VERSION ""

NS_ :

BS_:

BU_:IC_MMI GW AC AVM BCM DSM_D DSM_P FSCM PSR CWC

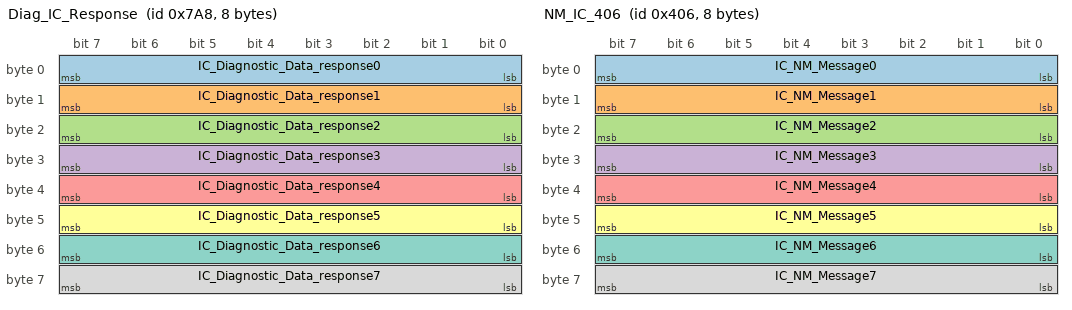
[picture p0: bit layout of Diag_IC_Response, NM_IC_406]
BO_ 1960 Diag_IC_Response: 8 IC_MMI
 SG_ IC_Diagnostic_Data_response0 : 7|8@0+ (1,0) [0|255] "" GW
 SG_ IC_Diagnostic_Data_response1 : 15|8@0+ (1,0) [0|255] "" GW
 SG_ IC_Diagnostic_Data_response2 : 23|8@0+ (1,0) [0|255] "" GW
 SG_ IC_Diagnostic_Data_response3 : 31|8@0+ (1,0) [0|255] "" GW
 SG_ IC_Diagnostic_Data_response4 : 39|8@0+ (1,0) [0|255] "" GW
 SG_ IC_Diagnostic_Data_response5 : 47|8@0+ (1,0) [0|255] "" GW
 SG_ IC_Diagnostic_Data_response6 : 55|8@0+ (1,0) [0|255] "" GW
 SG_ IC_Diagnostic_Data_response7 : 63|8@0+ (1,0) [0|255] "" GW

BO_ 1030 NM_IC_406: 8 IC_MMI
 SG_ IC_NM_Message0 : 7|8@0+ (1,0) [0|255] "" GW,AC,BCM
 SG_ IC_NM_Message1 : 15|8@0+ (1,0) [0|255] "" GW,AC,BCM
 SG_ IC_NM_Message2 : 23|8@0+ (1,0) [0|255] "" GW,AC,BCM
 SG_ IC_NM_Message3 : 31|8@0+ (1,0) [0|255] "" GW,AC,BCM
 SG_ IC_NM_Message4 : 39|8@0+ (1,0) [0|255] "" GW,AC,BCM
 SG_ IC_NM_Message5 : 47|8@0+ (1,0) [0|255] "" GW,AC,BCM
 SG_ IC_NM_Message6 : 55|8@0+ (1,0) [0|255] "" GW,AC,BCM
 SG_ IC_NM_Message7 : 63|8@0+ (1,0) [0|255] "" GW,AC,BCM

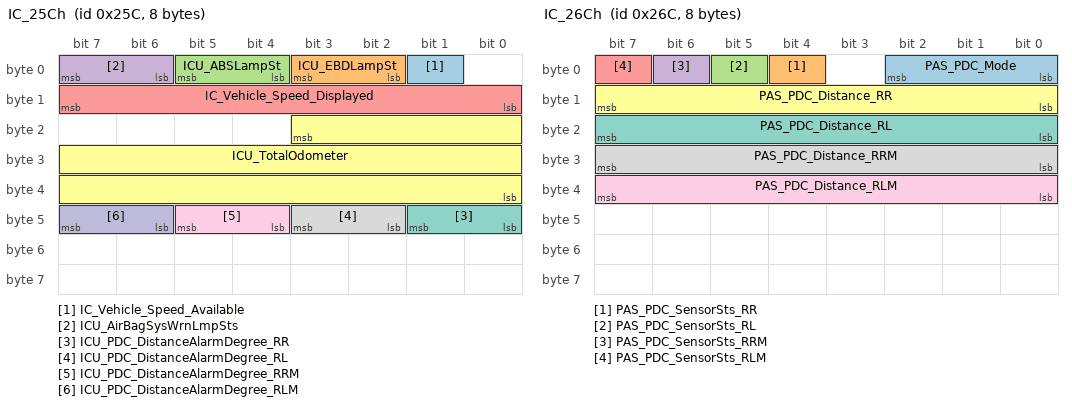
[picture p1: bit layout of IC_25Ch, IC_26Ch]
BO_ 604 IC_25Ch: 8 IC_MMI
 SG_ IC_Vehicle_Speed_Available : 1|1@0+ (1,0) [0|1] "" GW
 SG_ ICU_EBDLampSt : 3|2@0+ (1,0) [0|3] "" GW
 SG_ ICU_ABSLampSt : 5|2@0+ (1,0) [0|3] "" GW
 SG_ ICU_AirBagSysWrnLmpSts : 7|2@0+ (1,0) [0|3] "" GW
 SG_ IC_Vehicle_Speed_Displayed : 15|8@0+ (1,0) [0|255] "km/h" GW,AVM
 SG_ ICU_TotalOdometer : 19|20@0+ (1,0) [0|999999] "Km" GW,AVM,BCM
 SG_ ICU_PDC_DistanceAlarmDegree_RR : 41|2@0+ (1,0) [0|3] "" GW,AVM
 SG_ ICU_PDC_DistanceAlarmDegree_RL : 43|2@0+ (1,0) [0|3] "" GW,AVM
 SG_ ICU_PDC_DistanceAlarmDegree_RRM : 45|2@0+ (1,0) [0|3] "" GW,AVM
 SG_ ICU_PDC_DistanceAlarmDegree_RLM : 47|2@0+ (1,0) [0|3] "" GW,AVM

BO_ 620 IC_26Ch: 8 IC_MMI
 SG_ PAS_PDC_Mode : 2|3@0+ (1,0) [0|7] "" GW,AVM
 SG_ PAS_PDC_SensorSts_RR : 4|1@0+ (1,0) [0|1] "" GW,AVM
 SG_ PAS_PDC_SensorSts_RL : 5|1@0+ (1,0) [0|1] "" GW,AVM
 SG_ PAS_PDC_SensorSts_RRM : 6|1@0+ (1,0) [0|1] "" GW,AVM
 SG_ PAS_PDC_SensorSts_RLM : 7|1@0+ (1,0) [0|1] "" GW,AVM
 SG_ PAS_PDC_Distance_RR : 15|8@0+ (0.01,0) [0|1.5] "m" GW,AVM
 SG_ PAS_PDC_Distance_RL : 23|8@0+ (0.01,0) [0|1.5] "m" GW,AVM
 SG_ PAS_PDC_Distance_RRM : 31|8@0+ (0.01,0) [0|1.5] "m" GW,AVM
 SG_ PAS_PDC_Distance_RLM : 39|8@0+ (0.01,0) [0|1.5] "m" GW,AVM

BO_ 648 MMI_288h: 8 IC_MMI
 SG_ MMI_ACAUTOReqValid : 0|1@0+ (1,0) [0|1] "" GW,AC
 SG_ MMI_ACAUTOReq : 1|1@0+ (1,0) [0|1] "" GW,AC
 SG_ MMI_ACCompressorReqValid : 2|1@0+ (1,0) [0|1] "" GW,AC
 SG_ MMI_ACCompressorReq : 3|1@0+ (1,0) [0|1] "" GW,AC
 SG_ MMI_ACMaxReqValid : 4|1@0+ (1,0) [0|1] "" GW,AC
 SG_ MMI_ACMaxReq : 5|1@0+ (1,0) [0|1] "" GW,AC
 SG_ MMI_ACOFFReqValid : 6|1@0+ (1,0) [0|1] "" GW,AC
 SG_ MMI_ACOFFReq : 7|1@0+ (1,0) [0|1] "" GW,AC
 SG_ MMI_InsideTempIncDecReqValid : 8|1@0+ (1,0) [0|1] "" GW,AC
 SG_ MMI_InsideTempIncDecReq : 9|1@0+ (1,0) [0|1] "" GW,AC
 SG_ MMI_BLOWERReqValid : 10|1@0+ (1,0) [0|1] "" GW,AC
 SG_ MMI_BLOWERReq : 11|1@0+ (1,0) [0|1] "" GW,AC
 SG_ MMI_ACBlowModeReqValid : 12|1@0+ (1,0) [0|1] "" GW,AC
 SG_ MMI_ACBlowModeReq : 15|3@0+ (1,0) [0|7] "" GW,AC
 SG_ MMI_CirculatingModeSetValid : 16|1@0+ (1,0) [0|1] "" GW,AC
 SG_ MMI_CirculatingModeSet : 17|1@0+ (1,0) [0|1] "" GW,AC
 SG_ MMI_InsideTempSetValid : 18|1@0+ (1,0) [0|1] "" GW,AC
 SG_ MMI_InsideTempSet : 23|5@0+ (0.5,18) [18|32] "℃" GW,AC
 SG_ MMI_SeatHeatReq_right : 25|2@0+ (1,0) [0|3] "" GW,AC
 SG_ MMI_SeatHeatReq_left : 27|2@0+ (1,0) [0|3] "" GW,AC
 SG_ MMI_BLOWERGearSetValid : 28|1@0+ (1,0) [0|1] "" GW,AC
 SG_ MMI_BLOWERGearSet : 31|3@0+ (1,0) [0|7] "" GW,AC
 SG_ MMI_FrontDeforstReq : 33|2@0+ (1,0) [0|3] "" GW,AC
 SG_ MMI_RearDeforstReq : 35|2@0+ (1,0) [0|3] "" GW,AC
 SG_ MMI_RearViewMirrorHeatReq : 41|2@0+ (1,0) [0|3] "" GW,AC
 SG_ MMI_AnionNegativeIonReq : 43|2@0+ (1,0) [0|3] "" GW,AC

BO_ 370 MMI_172h: 8 IC_MMI
 SG_ MMI_LDW_Main_Switch : 0|1@0+ (1,0) [0|1] "" GW
 SG_ MMI_LDW_Switch_Available : 1|1@0+ (1,0) [0|1] "" GW
 SG_ MMI_FCW_Sensitivity : 3|2@0+ (1,0) [0|3] "" GW
 SG_ MMI_FCW_Main_Switch : 4|1@0+ (1,0) [0|1] "" GW
 SG_ MMI_FCW_Switch_Available : 5|1@0+ (1,0) [0|1] "" GW
 SG_ MMI_AEB_Main_Switch : 6|1@0+ (1,0) [0|1] "" GW
 SG_ MMI_AEB_Switch_Available : 7|1@0+ (1,0) [0|1] "" GW
 SG_ MMI_TSR_Main_Switch : 10|1@0+ (1,0) [0|1] "" GW
 SG_ MMI_TSR_Switch_Available : 11|1@0+ (1,0) [0|1] "" GW
 SG_ MMI_IHC_Main_Switch : 12|1@0+ (1,0) [0|1] "" GW
 SG_ MMI_IHC_Switch_Available : 13|1@0+ (1,0) [0|1] "" GW
 SG_ MMI_LDW_Sensitivity : 15|2@0+ (1,0) [0|3] "" GW
 SG_ MMI_BSD_Main_Switch : 16|1@0+ (1,0) [0|1] "" GW
 SG_ MMI_BSD_Switch_Available : 17|1@0+ (1,0) [0|1] "" GW
 SG_ MMI_BSD_Sensitivity : 19|2@0+ (1,0) [0|3] "" GW
 SG_ MMI_EPS_ModeSwitch : 22|3@0+ (1,0) [0|7] "" GW
 SG_ MMI_PauseContinueChrgRQ : 25|2@0+ (1,0) [0|3] "" GW
 SG_ MMI_WCBS_CstSwitch : 26|1@0+ (1,0) [0|1] "" GW
 SG_ MMI_WCBS_HDCSwitch : 27|1@0+ (1,0) [0|1] "" GW
 SG_ MMI_OperationMode : 30|3@0+ (1,0) [0|7] "" GW
 SG_ MMI_ChrgMaxPower : 38|7@0+ (1,0) [0|100] "%" GW
 SG_ MMI_ChrgCurrentSet : 47|8@0+ (0.1,0) [0|25.5] "A" GW
 SG_ MMI_EnergyRecoveryContr : 50|3@0+ (1,0) [0|7] "" GW
 SG_ MMI_LKA_Main_Switch : 52|1@0+ (1,0) [0|1] "" GW
 SG_ MMI_LKA_Switch_Available : 53|1@0+ (1,0) [0|1] "" GW

BO_ 630 MMI_276h: 8 IC_MMI
 SG_ MMI_AVM_ConnectStatus : 3|4@0+ (1,0) [0|15] "" GW,AVM
 SG_ MMI_AVM_LanguageSet : 7|4@0+ (1,0) [0|15] "" GW,AVM
 SG_ MMI_AVM_AVM3DDynTrajSet : 9|2@0+ (1,0) [0|3] "" GW,AVM
 SG_ MMI_AVM_AVM3DExitDelaySet : 11|2@0+ (1,0) [0|3] "" GW,AVM
 SG_ MMI_AVM_AVM3DTurnLightSet : 13|2@0+ (1,0) [0|3] "" GW,AVM
 SG_ MMI_AVM_AVM3DBlindFillSet : 15|2@0+ (1,0) [0|3] "" GW,AVM
 SG_ MMI_AVM_BSDFunction : 17|2@0+ (1,0) [0|3] "" GW,AVM
 SG_ MMI_AVM_OTFunction : 19|2@0+ (1,0) [0|3] "" GW,AVM
 SG_ MMI_AVM_AVM3DCarIconColor : 23|4@0+ (1,0) [0|15] "" GW,AVM
 SG_ MMI_AVM_AVM3DCarIconTransparenValid : 25|2@0+ (1,0) [0|3] "" GW,AVM
 SG_ MMI_AVM_VideoOutputStatus : 31|4@0+ (1,0) [0|15] "" GW,AVM
 SG_ MMI_AVM_AVM3DCarIconTransparent : 39|8@0+ (1,0) [0|100] "%" GW,AVM
 SG_ MMI_AmphereLampCtrl_Colour : 43|4@0+ (1,0) [0|15] "" GW
 SG_ MMI_AmphereLampCtrl_Fleshmode : 46|3@0+ (1,0) [0|7] "" GW
 SG_ MMI_AmphereLampCtrl_Drivingmode : 49|2@0+ (1,0) [0|3] "" GW
 SG_ MMI_AmphereLampCtrl_SW : 51|2@0+ (1,0) [0|3] "" GW
 SG_ MMI_AmphereLampCtrl_BrtnsVal : 63|8@0+ (1,0) [0|100] "" GW

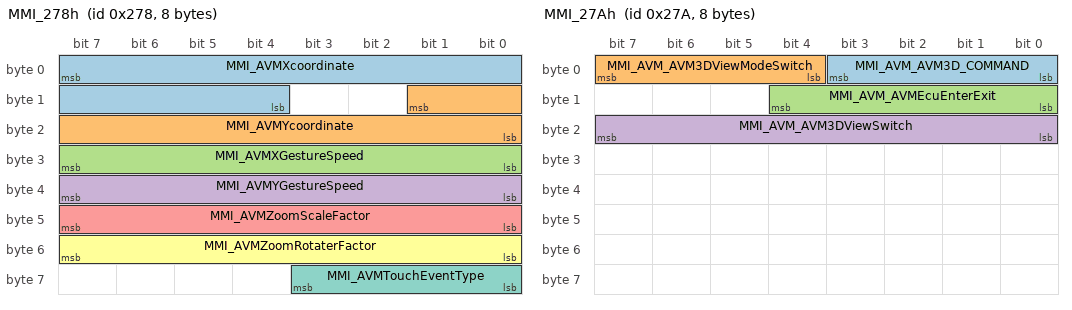
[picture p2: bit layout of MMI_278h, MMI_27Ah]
BO_ 632 MMI_278h: 8 IC_MMI
 SG_ MMI_AVMXcoordinate : 7|12@0+ (1,0) [0|4094] "" GW,AVM
 SG_ MMI_AVMYcoordinate : 9|10@0+ (1,0) [0|1022] "" GW,AVM
 SG_ MMI_AVMXGestureSpeed : 31|8@0+ (1,0) [0|254] "pixels/100ms" GW,AVM
 SG_ MMI_AVMYGestureSpeed : 39|8@0+ (1,0) [0|254] "pixels/100ms" GW,AVM
 SG_ MMI_AVMZoomScaleFactor : 47|8@0+ (1,0) [0|254] "" GW,AVM
 SG_ MMI_AVMZoomRotaterFactor : 55|8@0+ (1,0) [0|254] "" GW,AVM
 SG_ MMI_AVMTouchEventType : 59|4@0+ (1,0) [0|15] "" GW,AVM

BO_ 634 MMI_27Ah: 8 IC_MMI
 SG_ MMI_AVM_AVM3D_COMMAND : 3|4@0+ (1,0) [0|15] "" GW,AVM
 SG_ MMI_AVM_AVM3DViewModeSwitch : 7|4@0+ (1,0) [0|15] "" GW,AVM
 SG_ MMI_AVM_AVMEcuEnterExit : 12|5@0+ (1,0) [0|31] "" GW,AVM
 SG_ MMI_AVM_AVM3DViewSwitch : 23|8@0+ (1,0) [0|255] "" GW,AVM

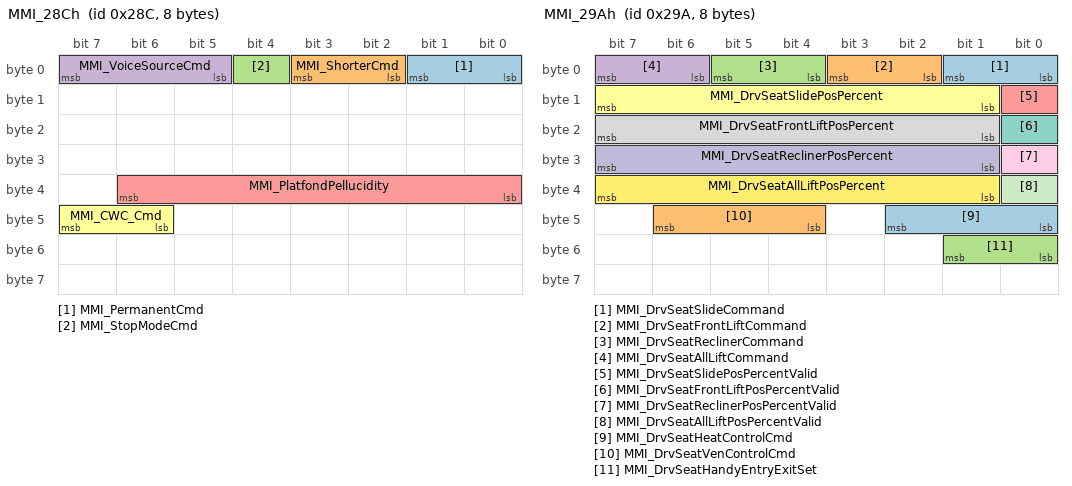
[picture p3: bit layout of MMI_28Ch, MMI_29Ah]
BO_ 652 MMI_28Ch: 8 IC_MMI
 SG_ MMI_PermanentCmd : 1|2@0+ (1,0) [0|3] "" GW
 SG_ MMI_ShorterCmd : 3|2@0+ (1,0) [0|3] "" GW
 SG_ MMI_StopModeCmd : 4|1@0+ (1,0) [0|1] "" GW
 SG_ MMI_VoiceSourceCmd : 7|3@0+ (1,0) [0|7] "" GW
 SG_ MMI_PlatfondPellucidity : 38|7@0+ (1,0) [0|100] "%" PSR
 SG_ MMI_CWC_Cmd : 47|2@0+ (1,0) [0|3] "" GW,CWC

BO_ 666 MMI_29Ah: 8 IC_MMI
 SG_ MMI_DrvSeatSlideCommand : 1|2@0+ (1,0) [0|3] "" DSM_D
 SG_ MMI_DrvSeatFrontLiftCommand : 3|2@0+ (1,0) [0|3] "" DSM_D
 SG_ MMI_DrvSeatReclinerCommand : 5|2@0+ (1,0) [0|3] "" DSM_D
 SG_ MMI_DrvSeatAllLiftCommand : 7|2@0+ (1,0) [0|3] "" DSM_D
 SG_ MMI_DrvSeatSlidePosPercentValid : 8|1@0+ (1,0) [0|1] "" DSM_D
 SG_ MMI_DrvSeatSlidePosPercent : 15|7@0+ (1,0) [0|100] "%" DSM_D
 SG_ MMI_DrvSeatFrontLiftPosPercentValid : 16|1@0+ (1,0) [0|1] "" DSM_D
 SG_ MMI_DrvSeatFrontLiftPosPercent : 23|7@0+ (1,0) [0|100] "%" DSM_D
 SG_ MMI_DrvSeatReclinerPosPercentValid : 24|1@0+ (1,0) [0|1] "" DSM_D
 SG_ MMI_DrvSeatReclinerPosPercent : 31|7@0+ (1,0) [0|100] "%" DSM_D
 SG_ MMI_DrvSeatAllLiftPosPercentValid : 32|1@0+ (1,0) [0|1] "" DSM_D
 SG_ MMI_DrvSeatAllLiftPosPercent : 39|7@0+ (1,0) [0|100] "%" DSM_D
 SG_ MMI_DrvSeatHeatControlCmd : 42|3@0+ (1,0) [0|7] "" FSCM
 SG_ MMI_DrvSeatVenControlCmd : 46|3@0+ (1,0) [0|7] "" FSCM
 SG_ MMI_DrvSeatHandyEntryExitSet : 49|2@0+ (1,0) [0|3] "" DSM_D

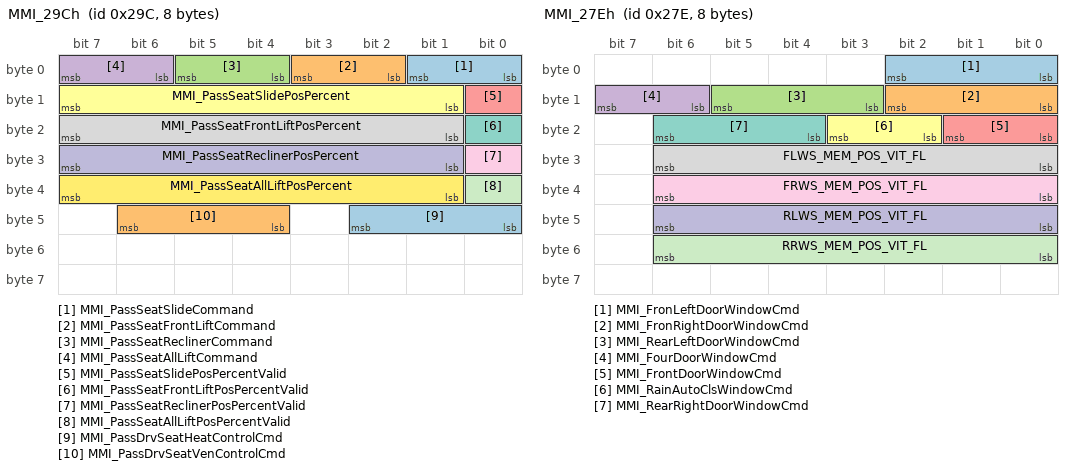
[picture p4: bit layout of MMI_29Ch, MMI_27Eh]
BO_ 668 MMI_29Ch: 8 IC_MMI
 SG_ MMI_PassSeatSlideCommand : 1|2@0+ (1,0) [0|3] "" DSM_P
 SG_ MMI_PassSeatFrontLiftCommand : 3|2@0+ (1,0) [0|3] "" DSM_P
 SG_ MMI_PassSeatReclinerCommand : 5|2@0+ (1,0) [0|3] "" DSM_P
 SG_ MMI_PassSeatAllLiftCommand : 7|2@0+ (1,0) [0|3] "" DSM_P
 SG_ MMI_PassSeatSlidePosPercentValid : 8|1@0+ (1,0) [0|1] "" DSM_P
 SG_ MMI_PassSeatSlidePosPercent : 15|7@0+ (1,0) [0|100] "%" DSM_P
 SG_ MMI_PassSeatFrontLiftPosPercentValid : 16|1@0+ (1,0) [0|1] "" DSM_P
 SG_ MMI_PassSeatFrontLiftPosPercent : 23|7@0+ (1,0) [0|100] "%" DSM_P
 SG_ MMI_PassSeatReclinerPosPercentValid : 24|1@0+ (1,0) [0|1] "" DSM_P
 SG_ MMI_PassSeatReclinerPosPercent : 31|7@0+ (1,0) [0|100] "%" DSM_P
 SG_ MMI_PassSeatAllLiftPosPercentValid : 32|1@0+ (1,0) [0|1] "" DSM_P
 SG_ MMI_PassSeatAllLiftPosPercent : 39|7@0+ (1,0) [0|100] "%" DSM_P
 SG_ MMI_PassDrvSeatHeatControlCmd : 42|3@0+ (1,0) [0|7] "" FSCM
 SG_ MMI_PassDrvSeatVenControlCmd : 46|3@0+ (1,0) [0|7] "" FSCM

BO_ 670 MMI_29Eh: 8 IC_MMI
 SG_ MMI_HazardLightCmd : 1|2@0+ (1,0) [0|3] "" BCM
 SG_ MMI_BCMLightCmd : 3|2@0+ (1,0) [0|3] "" BCM
 SG_ MMI_TailgateCmd : 5|2@0+ (1,0) [0|3] "" BCM
 SG_ MMI_RearViewCmd : 7|2@0+ (1,0) [0|3] "" BCM
 SG_ MMI_DoorLockCmd : 11|2@0+ (1,0) [0|3] "" BCM
 SG_ MMI_LowBeamLightCmd : 13|2@0+ (1,0) [0|3] "" BCM
 SG_ MMI_HighBeamLightCmd : 15|2@0+ (1,0) [0|3] "" BCM
 SG_ MMI_FoglightCmd : 17|2@0+ (1,0) [0|3] "" BCM
 SG_ MMI_WiperCmd : 20|3@0+ (1,0) [0|7] "" BCM
 SG_ MMI_AutolightSWCmd : 37|2@0+ (1,0) [0|3] "" BCM
 SG_ MMI_RainAutoClsWindowCmd : 39|2@0+ (1,0) [0|3] "" BCM
 SG_ MMI_ComfortModeSelectCmd : 41|2@0+ (1,0) [0|3] "" BCM
 SG_ MMI_RearViewMirrorSelect : 47|2@0+ (1,0) [0|3] "" BCM
 SG_ MMI_RearViewMirrorUpDown : 49|2@0+ (1,0) [0|3] "" BCM
 SG_ MMI_RearViewMirrorLeftRight : 51|2@0+ (1,0) [0|3] "" BCM
 SG_ MMI_LockVehicleWarmingTip : 53|2@0+ (1,0) [0|3] "" BCM
 SG_ MMI_UnlockVehicleOpenCourtesyLampSW : 55|2@0+ (1,0) [0|3] "" BCM
 SG_ MMI_AccLampSet : 59|2@0+ (1,0) [0|3] "" BCM
 SG_ MMI_RearViewMirrorAutoFoldFuc : 61|2@0+ (1,0) [0|3] "" BCM
 SG_ MMI_WiperMaintain : 63|2@0+ (1,0) [0|3] "" BCM

BO_ 638 MMI_27Eh: 8 IC_MMI
 SG_ MMI_FronLeftDoorWindowCmd : 2|3@0+ (1,0) [0|7] "" BCM
 SG_ MMI_FronRightDoorWindowCmd : 10|3@0+ (1,0) [0|7] "" BCM
 SG_ MMI_RearLeftDoorWindowCmd : 13|3@0+ (1,0) [0|7] "" BCM
 SG_ MMI_FourDoorWindowCmd : 15|2@0+ (1,0) [0|3] "" BCM
 SG_ MMI_FrontDoorWindowCmd : 17|2@0+ (1,0) [0|3] "" BCM
 SG_ MMI_RainAutoClsWindowCmd : 19|2@0+ (1,0) [0|3] "" BCM
 SG_ MMI_RearRightDoorWindowCmd : 22|3@0+ (1,0) [0|7] "" BCM
 SG_ FLWS_MEM_POS_VIT_FL : 30|7@0+ (1,0) [0|100] "%" BCM
 SG_ FRWS_MEM_POS_VIT_FL : 38|7@0+ (1,0) [0|100] "%" BCM
 SG_ RLWS_MEM_POS_VIT_FL : 46|7@0+ (1,0) [0|100] "%" BCM
 SG_ RRWS_MEM_POS_VIT_FL : 54|7@0+ (1,0) [0|100] "%" BCM

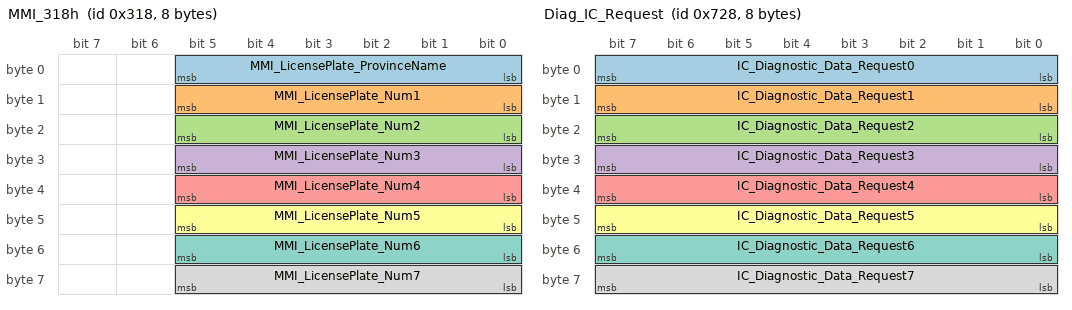
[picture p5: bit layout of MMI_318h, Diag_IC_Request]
BO_ 792 MMI_318h: 8 IC_MMI
 SG_ MMI_LicensePlate_ProvinceName : 5|6@0+ (1,0) [0|31] "" GW,AVM
 SG_ MMI_LicensePlate_Num1 : 13|6@0+ (1,0) [0|36] "" GW,AVM
 SG_ MMI_LicensePlate_Num2 : 21|6@0+ (1,0) [0|36] "" GW,AVM
 SG_ MMI_LicensePlate_Num3 : 29|6@0+ (1,0) [0|36] "" GW,AVM
 SG_ MMI_LicensePlate_Num4 : 37|6@0+ (1,0) [0|36] "" GW,AVM
 SG_ MMI_LicensePlate_Num5 : 45|6@0+ (1,0) [0|36] "" GW,AVM
 SG_ MMI_LicensePlate_Num6 : 53|6@0+ (1,0) [0|36] "" GW,AVM
 SG_ MMI_LicensePlate_Num7 : 61|6@0+ (1,0) [0|36] "" GW,AVM

BO_ 1832 Diag_IC_Request: 8 GW
 SG_ IC_Diagnostic_Data_Request0 : 7|8@0+ (1,0) [0|255] "" IC_MMI
 SG_ IC_Diagnostic_Data_Request1 : 15|8@0+ (1,0) [0|255] "" IC_MMI
 SG_ IC_Diagnostic_Data_Request2 : 23|8@0+ (1,0) [0|255] "" IC_MMI
 SG_ IC_Diagnostic_Data_Request3 : 31|8@0+ (1,0) [0|255] "" IC_MMI
 SG_ IC_Diagnostic_Data_Request4 : 39|8@0+ (1,0) [0|255] "" IC_MMI
 SG_ IC_Diagnostic_Data_Request5 : 47|8@0+ (1,0) [0|255] "" IC_MMI
 SG_ IC_Diagnostic_Data_Request6 : 55|8@0+ (1,0) [0|255] "" IC_MMI
 SG_ IC_Diagnostic_Data_Request7 : 63|8@0+ (1,0) [0|255] "" IC_MMI

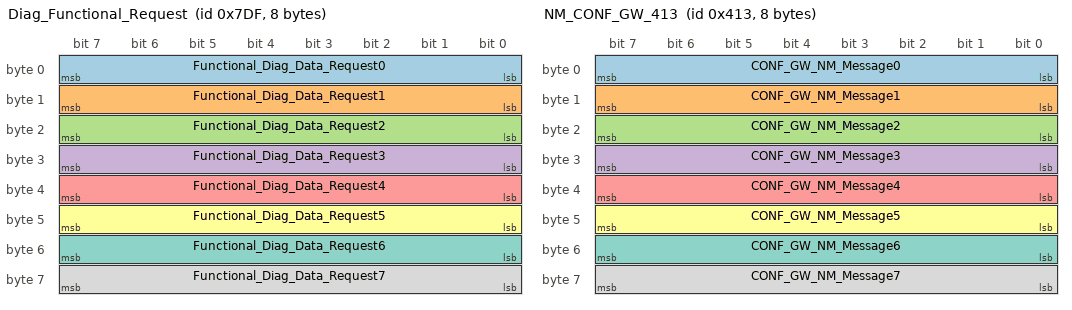
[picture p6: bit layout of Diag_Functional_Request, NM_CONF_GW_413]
BO_ 2015 Diag_Functional_Request: 8 GW
 SG_ Functional_Diag_Data_Request0 : 7|8@0+ (1,0) [0|255] "" IC_MMI,AC,AVM,BCM,DSM_D,DSM_P,FSCM,PSR,CWC
 SG_ Functional_Diag_Data_Request1 : 15|8@0+ (1,0) [0|255] "" IC_MMI,AC,AVM,BCM,DSM_D,DSM_P,FSCM,PSR,CWC
 SG_ Functional_Diag_Data_Request2 : 23|8@0+ (1,0) [0|255] "" IC_MMI,AC,AVM,BCM,DSM_D,DSM_P,FSCM,PSR,CWC
 SG_ Functional_Diag_Data_Request3 : 31|8@0+ (1,0) [0|255] "" IC_MMI,AC,AVM,BCM,DSM_D,DSM_P,FSCM,PSR,CWC
 SG_ Functional_Diag_Data_Request4 : 39|8@0+ (1,0) [0|255] "" IC_MMI,AC,AVM,BCM,DSM_D,DSM_P,FSCM,PSR,CWC
 SG_ Functional_Diag_Data_Request5 : 47|8@0+ (1,0) [0|255] "" IC_MMI,AC,AVM,BCM,DSM_D,DSM_P,FSCM,PSR,CWC
 SG_ Functional_Diag_Data_Request6 : 55|8@0+ (1,0) [0|255] "" IC_MMI,AC,AVM,BCM,DSM_D,DSM_P,FSCM,PSR,CWC
 SG_ Functional_Diag_Data_Request7 : 63|8@0+ (1,0) [0|255] "" IC_MMI,AC,AVM,BCM,DSM_D,DSM_P,FSCM,PSR,CWC

BO_ 1043 NM_CONF_GW_413: 8 GW
 SG_ CONF_GW_NM_Message0 : 7|8@0+ (1,0) [0|255] "" IC_MMI,AC,BCM
 SG_ CONF_GW_NM_Message1 : 15|8@0+ (1,0) [0|255] "" IC_MMI,AC,BCM
 SG_ CONF_GW_NM_Message2 : 23|8@0+ (1,0) [0|255] "" IC_MMI,AC,BCM
 SG_ CONF_GW_NM_Message3 : 31|8@0+ (1,0) [0|255] "" IC_MMI,AC,BCM
 SG_ CONF_GW_NM_Message4 : 39|8@0+ (1,0) [0|255] "" IC_MMI,AC,BCM
 SG_ CONF_GW_NM_Message5 : 47|8@0+ (1,0) [0|255] "" IC_MMI,AC,BCM
 SG_ CONF_GW_NM_Message6 : 55|8@0+ (1,0) [0|255] "" IC_MMI,AC,BCM
 SG_ CONF_GW_NM_Message7 : 63|8@0+ (1,0) [0|255] "" IC_MMI,AC,BCM

CM_ SG_ 604 IC_Vehicle_Speed_Available "indicates if IC is available
指示仪表车速信号是否可用";
CM_ SG_ 604 ICU_EBDLampSt "EBD灯的状态";
CM_ SG_ 604 ICU_ABSLampSt "ABS故障灯的状态";
CM_ SG_ 604 ICU_AirBagSysWrnLmpSts "Airbag System Warning Lamp Status

安全气囊报警指示灯状态";
CM_ SG_ 604 IC_Vehicle_Speed_Displayed "IPK displayed vehicle speed
仪表车速";
CM_ SG_ 604 ICU_TotalOdometer "Total Odometer 
总里程";
CM_ SG_ 604 ICU_PDC_DistanceAlarmDegree_RR "PDC rear right distance alarm degree
倒车雷达后右距离报警级别";
CM_ SG_ 604 ICU_PDC_DistanceAlarmDegree_RL "PDC rear left distance alarm degree
倒车雷达后左距离报警级别";
CM_ SG_ 604 ICU_PDC_DistanceAlarmDegree_RRM "PDC rear right midle distance alarm degree
倒车雷达后右中距离报警级别";
CM_ SG_ 604 ICU_PDC_DistanceAlarmDegree_RLM "PDC rear left midle distance alarm degree
倒车雷达后左中距离报警级别";
CM_ SG_ 620 PAS_PDC_Mode "PDC mode
倒车雷达的工作模式";
CM_ SG_ 620 PAS_PDC_SensorSts_RR "PDC Rear right sensor status
倒车雷达后右传感器状态";
CM_ SG_ 620 PAS_PDC_SensorSts_RL "PDC Rear left sensor status
倒车雷达后左传感器状态";
CM_ SG_ 620 PAS_PDC_SensorSts_RRM "PDC Rear right midle sensor status
倒车雷达后右中传感器状态";
CM_ SG_ 620 PAS_PDC_SensorSts_RLM "PDC Rear left midle sensor status
倒车雷达后左中传感器状态";
CM_ SG_ 620 PAS_PDC_Distance_RR "PDC Rear right distance display
倒车雷达后右区距离显示";
CM_ SG_ 620 PAS_PDC_Distance_RL "PDC Rear left distance display
倒车雷达后左区距离显示";
CM_ SG_ 620 PAS_PDC_Distance_RRM "PDC Rear right midle distance display
倒车雷达后右中区距离显示";
CM_ SG_ 620 PAS_PDC_Distance_RLM "PDC Rear left midle distance display
倒车雷达后左中区距离显示";
CM_ BO_ 648 "MMI发给空调的控制命令";
CM_ SG_ 648 MMI_ACAUTOReqValid "空调AUTO命令信号有效性";
CM_ SG_ 648 MMI_ACAUTOReq "空调AUTO命令";
CM_ SG_ 648 MMI_ACCompressorReqValid "空调压缩机命令信号有效性";
CM_ SG_ 648 MMI_ACCompressorReq "空调压缩机命令";
CM_ SG_ 648 MMI_ACMaxReqValid "最大制冷命令信号有效性";
CM_ SG_ 648 MMI_ACMaxReq "最大制冷命令请求";
CM_ SG_ 648 MMI_ACOFFReqValid "空调关机命令信号有效性";
CM_ SG_ 648 MMI_ACOFFReq "空调关机命令";
CM_ SG_ 648 MMI_InsideTempIncDecReqValid "温度增减命令信号有效性";
CM_ SG_ 648 MMI_InsideTempIncDecReq "温度增减命令
温度为18℃（LO）时，不响应温度减指令，温度为32℃（HI）时，不响应温度加指令；增减步进为0.5℃；";
CM_ SG_ 648 MMI_BLOWERReqValid "鼓风机风量增减命令信号有效性";
CM_ SG_ 648 MMI_BLOWERReq "鼓风机风量增减命令
风量为1档时，不执行风量减，风量为7时，不执行风量加指令";
CM_ SG_ 648 MMI_ACBlowModeReqValid "空调吹风模式命令信号有效性";
CM_ SG_ 648 MMI_ACBlowModeReq "空调吹风模式命令";
CM_ SG_ 648 MMI_CirculatingModeSetValid "循环模式设定信号有效性";
CM_ SG_ 648 MMI_CirculatingModeSet "循环模式设定";
CM_ SG_ 648 MMI_InsideTempSetValid "室内温度设定值命令信号有效性";
CM_ SG_ 648 MMI_InsideTempSet "室内温度设定值命令";
CM_ SG_ 648 MMI_SeatHeatReq_right "副驾座椅加热请求";
CM_ SG_ 648 MMI_SeatHeatReq_left "主驾座椅加热请求";
CM_ SG_ 648 MMI_BLOWERGearSetValid "鼓风机风量档位设定信号有效性";
CM_ SG_ 648 MMI_BLOWERGearSet "鼓风机风量档位设定
按照档位设定（1-7档），可在范围内设定；MMI下发指令设定风量时，直接赋值，不执行加减";
CM_ SG_ 648 MMI_FrontDeforstReq "前除霜控制命令";
CM_ SG_ 648 MMI_RearDeforstReq "后除霜控制命令";
CM_ SG_ 648 MMI_RearViewMirrorHeatReq "外后视镜加热控制命令";
CM_ SG_ 648 MMI_AnionNegativeIonReq "负离子开关命令";
CM_ BO_ 370 "给ADAS、BSD、预约充电的开关信号";
CM_ SG_ 370 MMI_LDW_Main_Switch "LDW main switch status
LDW主开关状态";
CM_ SG_ 370 MMI_LDW_Switch_Available "indicates if LDW switch is available
指示LDW开关信号是否可用";
CM_ SG_ 370 MMI_FCW_Sensitivity "driver selected sensitivity level
驾驶员选择的FCW敏感等级";
CM_ SG_ 370 MMI_FCW_Main_Switch "FCW main switch status
FCW主开关状态";
CM_ SG_ 370 MMI_FCW_Switch_Available "indicates if FCW switch is available
指示FCW开关是否可用";
CM_ SG_ 370 MMI_AEB_Main_Switch "AEB main switch status
AEB主开关状态";
CM_ SG_ 370 MMI_AEB_Switch_Available "indicates if AEB switch is available
指示AEB开关信号是否可用";
CM_ SG_ 370 MMI_TSR_Main_Switch "TSR main switch status
TSR主开关状态";
CM_ SG_ 370 MMI_TSR_Switch_Available "indicates if TSR switch is available
指示TSR开关是否可用";
CM_ SG_ 370 MMI_IHC_Main_Switch "IHC main switch status
IHC主开关状态";
CM_ SG_ 370 MMI_IHC_Switch_Available "indicates if IHC switch is available
指示IHC开关信号是否可用";
CM_ SG_ 370 MMI_LDW_Sensitivity "driver selected sensitivity level
驾驶员选择的LDW敏感等级";
CM_ SG_ 370 MMI_BSD_Main_Switch "BSD main switch status
BSD主开关状态";
CM_ SG_ 370 MMI_BSD_Switch_Available "indicates if BSDswitch is available
指示BSD开关信号是否可用";
CM_ SG_ 370 MMI_BSD_Sensitivity "driver selected sensitivity level
驾驶员选择的BSD敏感等级";
CM_ SG_ 370 MMI_EPS_ModeSwitch "EPS Mode Select
EPS模式选择";
CM_ SG_ 370 MMI_PauseContinueChrgRQ "Pause/Continue charge Request
请求暂停/继续充电(预留)";
CM_ SG_ 370 MMI_WCBS_CstSwitch "Comfortable Brake Swtich
CST功能开关";
CM_ SG_ 370 MMI_WCBS_HDCSwitch "陡坡缓降功能开关";
CM_ SG_ 370 MMI_OperationMode "Running mode
运行模式";
CM_ SG_ 370 MMI_ChrgMaxPower "Max Charging Power Set
最大充电电量设置(预留)";
CM_ SG_ 370 MMI_ChrgCurrentSet "Charge Current Set
充电电流设置(预留)";
CM_ SG_ 370 MMI_EnergyRecoveryContr "能量回收等级控制";
CM_ SG_ 370 MMI_LKA_Main_Switch "LKA main switch status
LKA主开关状态";
CM_ SG_ 370 MMI_LKA_Switch_Available "indicates if LKA switch is available
指示LKA开关信号是否可用";
CM_ BO_ 630 "MMI发给AVM的信号1(APA共用)";
CM_ SG_ 630 MMI_AVM_ConnectStatus "MMI connect status
MMI 与AVM连接状态";
CM_ SG_ 630 MMI_AVM_LanguageSet "语言设置";
CM_ SG_ 630 MMI_AVM_AVM3DDynTrajSet "AVM3D动态轨迹线设置";
CM_ SG_ 630 MMI_AVM_AVM3DExitDelaySet "AVM3D退出延迟设置";
CM_ SG_ 630 MMI_AVM_AVM3DTurnLightSet "AVM3D转向灯随动设置";
CM_ SG_ 630 MMI_AVM_AVM3DBlindFillSet "AVM3D车底盲区填充设置";
CM_ SG_ 630 MMI_AVM_BSDFunction "BSD功能是否开启";
CM_ SG_ 630 MMI_AVM_OTFunction "OTF功能是否开启";
CM_ SG_ 630 MMI_AVM_AVM3DCarIconColor "AVM车模颜色选择";
CM_ SG_ 630 MMI_AVM_AVM3DCarIconTransparenValid "AVM3D车模透明度是否有效";
CM_ SG_ 630 MMI_AVM_VideoOutputStatus "MMI AVM video outputstatus
MMI AVM 视频输出状态";
CM_ SG_ 630 MMI_AVM_AVM3DCarIconTransparent "AVM3D车模透明度";
CM_ SG_ 630 MMI_AmphereLampCtrl_Colour "氛围灯颜色控制";
CM_ SG_ 630 MMI_AmphereLampCtrl_Fleshmode "氛围灯呼吸模式控制";
CM_ SG_ 630 MMI_AmphereLampCtrl_Drivingmode "氛围灯驾驶模式控制";
CM_ SG_ 630 MMI_AmphereLampCtrl_SW "氛围灯开关控制";
CM_ SG_ 630 MMI_AmphereLampCtrl_BrtnsVal "氛围灯亮度值控制（0-100%）";
CM_ BO_ 632 "MMI发给AVM的信号2";
CM_ SG_ 632 MMI_AVMXcoordinate "触摸点横坐标";
CM_ SG_ 632 MMI_AVMYcoordinate "触摸点纵坐标";
CM_ SG_ 632 MMI_AVMXGestureSpeed "手势横向速度";
CM_ SG_ 632 MMI_AVMYGestureSpeed "手势纵向速度";
CM_ SG_ 632 MMI_AVMZoomScaleFactor "缩放系数";
CM_ SG_ 632 MMI_AVMZoomRotaterFactor "旋转系数";
CM_ SG_ 632 MMI_AVMTouchEventType "触摸事件类型";
CM_ BO_ 634 "MMI发给AVM的信号3";
CM_ SG_ 634 MMI_AVM_AVM3D_COMMAND "AVM3D操作指令";
CM_ SG_ 634 MMI_AVM_AVM3DViewModeSwitch "AVM3D视角模式切换";
CM_ SG_ 634 MMI_AVM_AVMEcuEnterExit "AVM_ECU进入/退出";
CM_ SG_ 634 MMI_AVM_AVM3DViewSwitch "AVM3D视角状态";
CM_ BO_ 652 "VSP/氛围灯/CWC/EPS/天窗的控制命令";
CM_ SG_ 652 MMI_PermanentCmd "VSP永久模式控制命令";
CM_ SG_ 652 MMI_ShorterCmd "VSP单次模式控制命令";
CM_ SG_ 652 MMI_StopModeCmd "VSP停车模式控制命令";
CM_ SG_ 652 MMI_VoiceSourceCmd "VSP声源选择控制命令";
CM_ SG_ 652 MMI_PlatfondPellucidity "全景天窗透明度";
CM_ SG_ 652 MMI_CWC_Cmd "CWC_OPEN_CLS                                                                  对无线充电器的开启与关闭";
CM_ BO_ 666 "MMI发送给主座椅调节及通风、加热命令";
CM_ SG_ 666 MMI_DrvSeatSlideCommand "主驾座椅前后调节指令";
CM_ SG_ 666 MMI_DrvSeatFrontLiftCommand "主驾座椅前升降调节指令";
CM_ SG_ 666 MMI_DrvSeatReclinerCommand "主驾座椅靠背调角调节指令";
CM_ SG_ 666 MMI_DrvSeatAllLiftCommand "主驾座椅全升降调节指令";
CM_ SG_ 666 MMI_DrvSeatSlidePosPercentValid "主驾座椅前后调节设置有效性";
CM_ SG_ 666 MMI_DrvSeatSlidePosPercent "主驾座椅前后调节设置";
CM_ SG_ 666 MMI_DrvSeatFrontLiftPosPercentValid "主驾座椅前升降调节设置有效性";
CM_ SG_ 666 MMI_DrvSeatFrontLiftPosPercent "主驾座椅前升降调节设置";
CM_ SG_ 666 MMI_DrvSeatReclinerPosPercentValid "主驾座椅靠背调角调节设置有效性";
CM_ SG_ 666 MMI_DrvSeatReclinerPosPercent "主驾座椅靠背调角调节设置";
CM_ SG_ 666 MMI_DrvSeatAllLiftPosPercentValid "主驾座椅全升降调节设置有效性";
CM_ SG_ 666 MMI_DrvSeatAllLiftPosPercent "主驾座椅全升降调节设置";
CM_ SG_ 666 MMI_DrvSeatHeatControlCmd "Driver seat heat control command
主驾座椅加热控制命令";
CM_ SG_ 666 MMI_DrvSeatVenControlCmd "Driver seat ventilation control command
主驾座椅通风控制命令";
CM_ SG_ 666 MMI_DrvSeatHandyEntryExitSet "便利进出设置";
CM_ BO_ 668 "MMI发送给副座椅调节及通风、加热命令";
CM_ SG_ 668 MMI_PassSeatSlideCommand "副驾座椅前后调节指令";
CM_ SG_ 668 MMI_PassSeatFrontLiftCommand "副驾座椅前升降调节指令";
CM_ SG_ 668 MMI_PassSeatReclinerCommand "副驾座椅靠背调角调节指令";
CM_ SG_ 668 MMI_PassSeatAllLiftCommand "副驾座椅全升降调节指令";
CM_ SG_ 668 MMI_PassSeatSlidePosPercentValid "副驾座椅前后调节设置有效性";
CM_ SG_ 668 MMI_PassSeatSlidePosPercent "副驾座椅前后调节设置";
CM_ SG_ 668 MMI_PassSeatFrontLiftPosPercentValid "副驾座椅前升降调节设置有效性";
CM_ SG_ 668 MMI_PassSeatFrontLiftPosPercent "副驾座椅前升降调节设置";
CM_ SG_ 668 MMI_PassSeatReclinerPosPercentValid "副驾座椅靠背调角调节设置有效性";
CM_ SG_ 668 MMI_PassSeatReclinerPosPercent "副驾座椅靠背调角调节设置";
CM_ SG_ 668 MMI_PassSeatAllLiftPosPercentValid "副驾座椅全升降调节设置有效性";
CM_ SG_ 668 MMI_PassSeatAllLiftPosPercent "副驾座椅全升降调节设置";
CM_ SG_ 668 MMI_PassDrvSeatHeatControlCmd "Pass Driver seat heat control command
副驾座椅加热控制命令";
CM_ SG_ 668 MMI_PassDrvSeatVenControlCmd "Pass seat ventilation control command
副驾座椅通风控制命令";
CM_ BO_ 670 "发送给BCM的控制命令";
CM_ SG_ 670 MMI_HazardLightCmd "对双闪灯的控制命令";
CM_ SG_ 670 MMI_BCMLightCmd "对小灯的控制命令";
CM_ SG_ 670 MMI_TailgateCmd "对尾门的控制命令";
CM_ SG_ 670 MMI_RearViewCmd "对后视镜的控制命令";
CM_ SG_ 670 MMI_DoorLockCmd "对车门门锁的控制命令";
CM_ SG_ 670 MMI_LowBeamLightCmd "对近光灯的控制命令";
CM_ SG_ 670 MMI_HighBeamLightCmd "对远光灯的控制命令";
CM_ SG_ 670 MMI_FoglightCmd "发送给雾灯的控制命令";
CM_ SG_ 670 MMI_WiperCmd "发送给雨刮的控制命令";
CM_ SG_ 670 MMI_AutolightSWCmd "自动大灯开关命令";
CM_ SG_ 670 MMI_RainAutoClsWindowCmd "雨天自动关闭四门车窗";
CM_ SG_ 670 MMI_ComfortModeSelectCmd "露营模式的选择命令";
CM_ SG_ 670 MMI_RearViewMirrorSelect "外后视镜选择控制命令(预留)";
CM_ SG_ 670 MMI_RearViewMirrorUpDown "视镜上下调节控制命令(预留)";
CM_ SG_ 670 MMI_RearViewMirrorLeftRight "视镜左右调节控制命令(预留)";
CM_ SG_ 670 MMI_LockVehicleWarmingTip "锁车提醒方式";
CM_ SG_ 670 MMI_UnlockVehicleOpenCourtesyLampSW "解锁车辆点亮迎宾灯开关";
CM_ SG_ 670 MMI_AccLampSet "伴我回家灯设置";
CM_ SG_ 670 MMI_RearViewMirrorAutoFoldFuc "后视镜自动折叠功能";
CM_ SG_ 670 MMI_WiperMaintain "雨刮维护功能控制命令";
CM_ BO_ 638 "车窗的控制命令";
CM_ SG_ 638 MMI_FronLeftDoorWindowCmd "主车窗的控制命令";
CM_ SG_ 638 MMI_FronRightDoorWindowCmd "副车窗的控制命令";
CM_ SG_ 638 MMI_RearLeftDoorWindowCmd "左后车窗的控制命令";
CM_ SG_ 638 MMI_FourDoorWindowCmd "四门车窗的控制命令";
CM_ SG_ 638 MMI_FrontDoorWindowCmd "前车窗的控制命令";
CM_ SG_ 638 MMI_RainAutoClsWindowCmd "雨天自动关闭四门车窗";
CM_ SG_ 638 MMI_RearRightDoorWindowCmd "右后车窗的控制命令";
CM_ SG_ 638 FLWS_MEM_POS_VIT_FL "Left Front window memory position
左前车窗记忆位置";
CM_ SG_ 638 FRWS_MEM_POS_VIT_FL "Right front window position
右前车窗记忆位置";
CM_ SG_ 638 RLWS_MEM_POS_VIT_FL "Left rear Window position
左后车窗记忆位置";
CM_ SG_ 638 RRWS_MEM_POS_VIT_FL "Right rear Window position
右后车窗记忆位置";
CM_ BO_ 792 "MMI发给AVM的信号4";
CM_ SG_ 792 MMI_LicensePlate_ProvinceName "Car License Plate Province
车牌号-省";
CM_ SG_ 792 MMI_LicensePlate_Num1 "Car License Plate Number 1
车牌号-数字号1";
CM_ SG_ 792 MMI_LicensePlate_Num2 "Car License Plate Number 2
车牌号-数字号2";
CM_ SG_ 792 MMI_LicensePlate_Num3 "Car License Plate Number 3
车牌号-数字号3";
CM_ SG_ 792 MMI_LicensePlate_Num4 "Car License Plate Number 4
车牌号-数字号4";
CM_ SG_ 792 MMI_LicensePlate_Num5 "Car License Plate Number 5
车牌号-数字号5";
CM_ SG_ 792 MMI_LicensePlate_Num6 "Car License Plate Number6
车牌号-数字号6";
CM_ SG_ 792 MMI_LicensePlate_Num7 "Car License Plate Number 7
车牌号-数字号7";
BA_DEF_ BO_  "NmMessage" ENUM "No","Yes";
BA_DEF_ BO_  "DiagState" ENUM  "No","Yes";
BA_DEF_ BO_  "DiagResponse" ENUM  "No","Yes";
BA_DEF_ BO_  "GenMsgSendType" ENUM  "NoSendType","Cycle","Event","IfActive","CE","CA";
BA_DEF_ BO_  "GenMsgCycleTime" INT 0 0;
BA_DEF_ SG_  "GenSigSendType" ENUM  "NoSendType","Cycle","OnWrite","OnWriteWithRepetition","OnChange","OnChangeWithRepetition","IfActive","IfActiveWithRepetition";
BA_DEF_ SG_  "GenSigStartValue" INT 0 0;
BA_DEF_ SG_  "GenSigInvalidValue" STRING;
BA_DEF_ BO_  "GenMsgCycleTimeFast" INT 0 0;
BA_DEF_ BO_  "GenMsgNrOfRepetition" INT 0 0;
BA_DEF_ BO_  "GenMsgDelayTime" INT 0 0;
BA_DEF_  "DBName" STRING ;
BA_DEF_ BU_  "NodeLayerModules" STRING ;
BA_DEF_ BU_  "NmNode" ENUM  "Not","Yes";
BA_DEF_  "NmBaseAddress" HEX 0 2047;
BA_DEF_  "NmMessageCount" INT 0 255;
BA_DEF_  "BusType" STRING ;

BA_DEF_DEF_  "NmMessage" "No";
BA_DEF_DEF_  "DiagState" "No";
BA_DEF_DEF_  "DiagResponse" "No";
BA_DEF_DEF_  "GenMsgSendType" "Cycle";
BA_DEF_DEF_  "GenMsgCycleTime" 0;
BA_DEF_DEF_  "GenSigSendType" "Cycle";
BA_DEF_DEF_  "GenSigStartValue" 0;
BA_DEF_DEF_  "GenSigInvalidValue" "";
BA_DEF_DEF_  "GenMsgCycleTimeFast" 0;
BA_DEF_DEF_  "GenMsgNrOfRepetition" 0;
BA_DEF_DEF_  "GenMsgDelayTime" 0;
BA_DEF_DEF_  "DBName" "";
BA_DEF_DEF_  "NodeLayerModules" "oseknm01.dll,osek_tp.dll,CANoeILNLVector.dll";
BA_DEF_DEF_  "NmNode" "Not";
BA_DEF_DEF_  "NmBaseAddress" 1024;
BA_DEF_DEF_  "NmMessageCount" 128;
BA_DEF_DEF_  "BusType" "CAN";
BA_ "DBName" "CAN";
BA_ "DiagState" BO_ 1960 1 ;
BA_ "DiagResponse" BO_ 1960 1 ;
BA_ "GenMsgSendType" BO_ 1960 2;
BA_ "GenSigSendType" SG_ 1960 IC_Diagnostic_Data_response0 2;
BA_ "GenSigSendType" SG_ 1960 IC_Diagnostic_Data_response1 2;
BA_ "GenSigSendType" SG_ 1960 IC_Diagnostic_Data_response2 2;
BA_ "GenSigSendType" SG_ 1960 IC_Diagnostic_Data_response3 2;
BA_ "GenSigSendType" SG_ 1960 IC_Diagnostic_Data_response4 2;
BA_ "GenSigSendType" SG_ 1960 IC_Diagnostic_Data_response5 2;
BA_ "GenSigSendType" SG_ 1960 IC_Diagnostic_Data_response6 2;
BA_ "GenSigSendType" SG_ 1960 IC_Diagnostic_Data_response7 2;
BA_ "NmMessage" BO_ 1030 1 ;
BA_ "GenMsgSendType" BO_ 1030 2;
BA_ "GenSigSendType" SG_ 1030 IC_NM_Message0 2;
BA_ "GenSigSendType" SG_ 1030 IC_NM_Message1 2;
BA_ "GenSigSendType" SG_ 1030 IC_NM_Message2 2;
BA_ "GenSigSendType" SG_ 1030 IC_NM_Message3 2;
BA_ "GenSigSendType" SG_ 1030 IC_NM_Message4 2;
BA_ "GenSigSendType" SG_ 1030 IC_NM_Message5 2;
BA_ "GenSigSendType" SG_ 1030 IC_NM_Message6 2;
BA_ "GenSigSendType" SG_ 1030 IC_NM_Message7 2;
BA_ "GenMsgCycleTime" BO_ 604 100 ;
BA_ "GenSigInvalidValue" SG_ 604 ICU_TotalOdometer "0xFFFFF";
BA_ "GenMsgCycleTime" BO_ 620 100 ;
BA_ "GenSigStartValue" SG_ 620 PAS_PDC_Distance_RR 255;
BA_ "GenSigInvalidValue" SG_ 620 PAS_PDC_Distance_RR "0xFF";
BA_ "GenSigStartValue" SG_ 620 PAS_PDC_Distance_RL 255;
BA_ "GenSigInvalidValue" SG_ 620 PAS_PDC_Distance_RL "0xFF";
BA_ "GenSigStartValue" SG_ 620 PAS_PDC_Distance_RRM 255;
BA_ "GenSigInvalidValue" SG_ 620 PAS_PDC_Distance_RRM "0xFF";
BA_ "GenSigStartValue" SG_ 620 PAS_PDC_Distance_RLM 255;
BA_ "GenSigInvalidValue" SG_ 620 PAS_PDC_Distance_RLM "0xFF";
BA_ "GenMsgSendType" BO_ 648 2;
BA_ "GenMsgCycleTimeFast" BO_ 648 100 ;
BA_ "GenMsgNrOfRepetition" BO_ 648 3 ;
BA_ "GenSigSendType" SG_ 648 MMI_ACAUTOReqValid 3;
BA_ "GenSigInvalidValue" SG_ 648 MMI_ACAUTOReqValid "0x0";
BA_ "GenSigSendType" SG_ 648 MMI_ACAUTOReq 3;
BA_ "GenSigSendType" SG_ 648 MMI_ACCompressorReqValid 3;
BA_ "GenSigInvalidValue" SG_ 648 MMI_ACCompressorReqValid "0x0";
BA_ "GenSigSendType" SG_ 648 MMI_ACCompressorReq 3;
BA_ "GenSigSendType" SG_ 648 MMI_ACMaxReqValid 3;
BA_ "GenSigInvalidValue" SG_ 648 MMI_ACMaxReqValid "0x0";
BA_ "GenSigSendType" SG_ 648 MMI_ACMaxReq 3;
BA_ "GenSigSendType" SG_ 648 MMI_ACOFFReqValid 3;
BA_ "GenSigInvalidValue" SG_ 648 MMI_ACOFFReqValid "0x0";
BA_ "GenSigSendType" SG_ 648 MMI_ACOFFReq 3;
BA_ "GenSigSendType" SG_ 648 MMI_InsideTempIncDecReqValid 3;
BA_ "GenSigInvalidValue" SG_ 648 MMI_InsideTempIncDecReqValid "0x0";
BA_ "GenSigSendType" SG_ 648 MMI_InsideTempIncDecReq 3;
BA_ "GenSigSendType" SG_ 648 MMI_BLOWERReqValid 3;
BA_ "GenSigInvalidValue" SG_ 648 MMI_BLOWERReqValid "0x0";
BA_ "GenSigSendType" SG_ 648 MMI_BLOWERReq 3;
BA_ "GenSigSendType" SG_ 648 MMI_ACBlowModeReqValid 3;
BA_ "GenSigInvalidValue" SG_ 648 MMI_ACBlowModeReqValid "0x0";
BA_ "GenSigSendType" SG_ 648 MMI_ACBlowModeReq 3;
BA_ "GenSigSendType" SG_ 648 MMI_CirculatingModeSetValid 3;
BA_ "GenSigInvalidValue" SG_ 648 MMI_CirculatingModeSetValid "0x0";
BA_ "GenSigSendType" SG_ 648 MMI_CirculatingModeSet 3;
BA_ "GenSigSendType" SG_ 648 MMI_InsideTempSetValid 3;
BA_ "GenSigInvalidValue" SG_ 648 MMI_InsideTempSetValid "0x0";
BA_ "GenSigSendType" SG_ 648 MMI_InsideTempSet 3;
BA_ "GenSigSendType" SG_ 648 MMI_SeatHeatReq_right 3;
BA_ "GenSigInvalidValue" SG_ 648 MMI_SeatHeatReq_right "0x0";
BA_ "GenSigSendType" SG_ 648 MMI_SeatHeatReq_left 3;
BA_ "GenSigInvalidValue" SG_ 648 MMI_SeatHeatReq_left "0x0";
BA_ "GenSigSendType" SG_ 648 MMI_BLOWERGearSetValid 3;
BA_ "GenSigInvalidValue" SG_ 648 MMI_BLOWERGearSetValid "0x0";
BA_ "GenSigSendType" SG_ 648 MMI_BLOWERGearSet 3;
BA_ "GenSigSendType" SG_ 648 MMI_FrontDeforstReq 3;
BA_ "GenSigInvalidValue" SG_ 648 MMI_FrontDeforstReq "0x0";
BA_ "GenSigSendType" SG_ 648 MMI_RearDeforstReq 3;
BA_ "GenSigInvalidValue" SG_ 648 MMI_RearDeforstReq "0x0";
BA_ "GenSigSendType" SG_ 648 MMI_RearViewMirrorHeatReq 3;
BA_ "GenSigInvalidValue" SG_ 648 MMI_RearViewMirrorHeatReq "0x0";
BA_ "GenSigSendType" SG_ 648 MMI_AnionNegativeIonReq 3;
BA_ "GenSigInvalidValue" SG_ 648 MMI_AnionNegativeIonReq "0x0";
BA_ "GenMsgSendType" BO_ 370 2;
BA_ "GenMsgCycleTimeFast" BO_ 370 100 ;
BA_ "GenMsgNrOfRepetition" BO_ 370 3 ;
BA_ "GenSigSendType" SG_ 370 MMI_LDW_Main_Switch 3;
BA_ "GenSigSendType" SG_ 370 MMI_LDW_Switch_Available 3;
BA_ "GenSigStartValue" SG_ 370 MMI_LDW_Switch_Available 1;
BA_ "GenSigSendType" SG_ 370 MMI_FCW_Sensitivity 3;
BA_ "GenSigSendType" SG_ 370 MMI_FCW_Main_Switch 3;
BA_ "GenSigSendType" SG_ 370 MMI_FCW_Switch_Available 3;
BA_ "GenSigStartValue" SG_ 370 MMI_FCW_Switch_Available 1;
BA_ "GenSigSendType" SG_ 370 MMI_AEB_Main_Switch 3;
BA_ "GenSigSendType" SG_ 370 MMI_AEB_Switch_Available 3;
BA_ "GenSigStartValue" SG_ 370 MMI_AEB_Switch_Available 1;
BA_ "GenSigSendType" SG_ 370 MMI_TSR_Main_Switch 3;
BA_ "GenSigSendType" SG_ 370 MMI_TSR_Switch_Available 3;
BA_ "GenSigStartValue" SG_ 370 MMI_TSR_Switch_Available 1;
BA_ "GenSigSendType" SG_ 370 MMI_IHC_Main_Switch 3;
BA_ "GenSigSendType" SG_ 370 MMI_IHC_Switch_Available 3;
BA_ "GenSigStartValue" SG_ 370 MMI_IHC_Switch_Available 1;
BA_ "GenSigSendType" SG_ 370 MMI_LDW_Sensitivity 3;
BA_ "GenSigSendType" SG_ 370 MMI_BSD_Main_Switch 3;
BA_ "GenSigSendType" SG_ 370 MMI_BSD_Switch_Available 3;
BA_ "GenSigSendType" SG_ 370 MMI_BSD_Sensitivity 3;
BA_ "GenSigSendType" SG_ 370 MMI_EPS_ModeSwitch 3;
BA_ "GenSigInvalidValue" SG_ 370 MMI_EPS_ModeSwitch "0x0";
BA_ "GenSigSendType" SG_ 370 MMI_PauseContinueChrgRQ 3;
BA_ "GenSigInvalidValue" SG_ 370 MMI_PauseContinueChrgRQ "0x0";
BA_ "GenSigSendType" SG_ 370 MMI_WCBS_CstSwitch 3;
BA_ "GenSigSendType" SG_ 370 MMI_WCBS_HDCSwitch 3;
BA_ "GenSigSendType" SG_ 370 MMI_OperationMode 3;
BA_ "GenSigSendType" SG_ 370 MMI_ChrgMaxPower 3;
BA_ "GenSigInvalidValue" SG_ 370 MMI_ChrgMaxPower "0x7F";
BA_ "GenSigSendType" SG_ 370 MMI_ChrgCurrentSet 3;
BA_ "GenSigInvalidValue" SG_ 370 MMI_ChrgCurrentSet "0x0";
BA_ "GenSigSendType" SG_ 370 MMI_EnergyRecoveryContr 3;
BA_ "GenSigInvalidValue" SG_ 370 MMI_EnergyRecoveryContr "0x0";
BA_ "GenSigSendType" SG_ 370 MMI_LKA_Main_Switch 3;
BA_ "GenSigSendType" SG_ 370 MMI_LKA_Switch_Available 3;
BA_ "GenMsgCycleTime" BO_ 630 100 ;
BA_ "GenSigInvalidValue" SG_ 630 MMI_AVM_ConnectStatus "f";
BA_ "GenSigInvalidValue" SG_ 630 MMI_AVM_LanguageSet "f";
BA_ "GenSigInvalidValue" SG_ 630 MMI_AVM_AVM3DDynTrajSet "3";
BA_ "GenSigInvalidValue" SG_ 630 MMI_AVM_AVM3DExitDelaySet "3";
BA_ "GenSigInvalidValue" SG_ 630 MMI_AVM_AVM3DTurnLightSet "3";
BA_ "GenSigInvalidValue" SG_ 630 MMI_AVM_AVM3DBlindFillSet "3";
BA_ "GenSigInvalidValue" SG_ 630 MMI_AVM_BSDFunction "3";
BA_ "GenSigInvalidValue" SG_ 630 MMI_AVM_OTFunction "3";
BA_ "GenSigInvalidValue" SG_ 630 MMI_AVM_AVM3DCarIconColor "f";
BA_ "GenSigInvalidValue" SG_ 630 MMI_AVM_AVM3DCarIconTransparenValid "3";
BA_ "GenSigInvalidValue" SG_ 630 MMI_AVM_VideoOutputStatus "f";
BA_ "GenSigInvalidValue" SG_ 630 MMI_AVM_AVM3DCarIconTransparent "FF";
BA_ "GenSigInvalidValue" SG_ 630 MMI_AmphereLampCtrl_Fleshmode "0x0";
BA_ "GenSigInvalidValue" SG_ 630 MMI_AmphereLampCtrl_Drivingmode "0x0";
BA_ "GenSigInvalidValue" SG_ 630 MMI_AmphereLampCtrl_SW "0x0";
BA_ "GenSigStartValue" SG_ 630 MMI_AmphereLampCtrl_BrtnsVal 255;
BA_ "GenSigInvalidValue" SG_ 630 MMI_AmphereLampCtrl_BrtnsVal "0xFF";
BA_ "GenMsgSendType" BO_ 632 2;
BA_ "GenMsgCycleTimeFast" BO_ 632 20 ;
BA_ "GenMsgNrOfRepetition" BO_ 632 3 ;
BA_ "GenSigSendType" SG_ 632 MMI_AVMXcoordinate 3;
BA_ "GenSigInvalidValue" SG_ 632 MMI_AVMXcoordinate "0xFFF";
BA_ "GenSigSendType" SG_ 632 MMI_AVMYcoordinate 3;
BA_ "GenSigInvalidValue" SG_ 632 MMI_AVMYcoordinate "0x3FF";
BA_ "GenSigSendType" SG_ 632 MMI_AVMXGestureSpeed 3;
BA_ "GenSigInvalidValue" SG_ 632 MMI_AVMXGestureSpeed "0xFF";
BA_ "GenSigSendType" SG_ 632 MMI_AVMYGestureSpeed 3;
BA_ "GenSigInvalidValue" SG_ 632 MMI_AVMYGestureSpeed "0xFF";
BA_ "GenSigSendType" SG_ 632 MMI_AVMZoomScaleFactor 3;
BA_ "GenSigInvalidValue" SG_ 632 MMI_AVMZoomScaleFactor "0xFF";
BA_ "GenSigSendType" SG_ 632 MMI_AVMZoomRotaterFactor 3;
BA_ "GenSigInvalidValue" SG_ 632 MMI_AVMZoomRotaterFactor "0xFF";
BA_ "GenSigSendType" SG_ 632 MMI_AVMTouchEventType 3;
BA_ "GenSigInvalidValue" SG_ 632 MMI_AVMTouchEventType "0x0";
BA_ "GenMsgSendType" BO_ 634 2;
BA_ "GenMsgCycleTimeFast" BO_ 634 20 ;
BA_ "GenMsgNrOfRepetition" BO_ 634 3 ;
BA_ "GenSigSendType" SG_ 634 MMI_AVM_AVM3D_COMMAND 3;
BA_ "GenSigInvalidValue" SG_ 634 MMI_AVM_AVM3D_COMMAND "0xf";
BA_ "GenSigSendType" SG_ 634 MMI_AVM_AVM3DViewModeSwitch 3;
BA_ "GenSigInvalidValue" SG_ 634 MMI_AVM_AVM3DViewModeSwitch "0xf";
BA_ "GenSigSendType" SG_ 634 MMI_AVM_AVMEcuEnterExit 3;
BA_ "GenSigSendType" SG_ 634 MMI_AVM_AVM3DViewSwitch 3;
BA_ "GenMsgSendType" BO_ 652 2;
BA_ "GenMsgCycleTimeFast" BO_ 652 100 ;
BA_ "GenMsgNrOfRepetition" BO_ 652 3 ;
BA_ "GenSigSendType" SG_ 652 MMI_PermanentCmd 3;
BA_ "GenSigSendType" SG_ 652 MMI_ShorterCmd 3;
BA_ "GenSigSendType" SG_ 652 MMI_StopModeCmd 3;
BA_ "GenSigSendType" SG_ 652 MMI_VoiceSourceCmd 3;
BA_ "GenSigSendType" SG_ 652 MMI_PlatfondPellucidity 3;
BA_ "GenSigInvalidValue" SG_ 652 MMI_PlatfondPellucidity "0x7f";
BA_ "GenSigSendType" SG_ 652 MMI_CWC_Cmd 3;
BA_ "GenSigInvalidValue" SG_ 652 MMI_CWC_Cmd "0x0";
BA_ "GenMsgSendType" BO_ 666 2;
BA_ "GenMsgCycleTimeFast" BO_ 666 100 ;
BA_ "GenMsgNrOfRepetition" BO_ 666 3 ;
BA_ "GenSigSendType" SG_ 666 MMI_DrvSeatSlideCommand 3;
BA_ "GenSigInvalidValue" SG_ 666 MMI_DrvSeatSlideCommand "0x0";
BA_ "GenSigSendType" SG_ 666 MMI_DrvSeatFrontLiftCommand 3;
BA_ "GenSigInvalidValue" SG_ 666 MMI_DrvSeatFrontLiftCommand "0x0";
BA_ "GenSigSendType" SG_ 666 MMI_DrvSeatReclinerCommand 3;
BA_ "GenSigInvalidValue" SG_ 666 MMI_DrvSeatReclinerCommand "0x0";
BA_ "GenSigSendType" SG_ 666 MMI_DrvSeatAllLiftCommand 3;
BA_ "GenSigInvalidValue" SG_ 666 MMI_DrvSeatAllLiftCommand "0x0";
BA_ "GenSigSendType" SG_ 666 MMI_DrvSeatSlidePosPercentValid 3;
BA_ "GenSigInvalidValue" SG_ 666 MMI_DrvSeatSlidePosPercentValid "0x0";
BA_ "GenSigSendType" SG_ 666 MMI_DrvSeatSlidePosPercent 3;
BA_ "GenSigStartValue" SG_ 666 MMI_DrvSeatSlidePosPercent 63;
BA_ "GenSigInvalidValue" SG_ 666 MMI_DrvSeatSlidePosPercent "0x3F";
BA_ "GenSigSendType" SG_ 666 MMI_DrvSeatFrontLiftPosPercentValid 3;
BA_ "GenSigInvalidValue" SG_ 666 MMI_DrvSeatFrontLiftPosPercentValid "0x0";
BA_ "GenSigSendType" SG_ 666 MMI_DrvSeatFrontLiftPosPercent 3;
BA_ "GenSigStartValue" SG_ 666 MMI_DrvSeatFrontLiftPosPercent 63;
BA_ "GenSigInvalidValue" SG_ 666 MMI_DrvSeatFrontLiftPosPercent "0x3F";
BA_ "GenSigSendType" SG_ 666 MMI_DrvSeatReclinerPosPercentValid 3;
BA_ "GenSigInvalidValue" SG_ 666 MMI_DrvSeatReclinerPosPercentValid "0x0";
BA_ "GenSigSendType" SG_ 666 MMI_DrvSeatReclinerPosPercent 3;
BA_ "GenSigStartValue" SG_ 666 MMI_DrvSeatReclinerPosPercent 63;
BA_ "GenSigInvalidValue" SG_ 666 MMI_DrvSeatReclinerPosPercent "0x3F";
BA_ "GenSigSendType" SG_ 666 MMI_DrvSeatAllLiftPosPercentValid 3;
BA_ "GenSigInvalidValue" SG_ 666 MMI_DrvSeatAllLiftPosPercentValid "0x0";
BA_ "GenSigSendType" SG_ 666 MMI_DrvSeatAllLiftPosPercent 3;
BA_ "GenSigStartValue" SG_ 666 MMI_DrvSeatAllLiftPosPercent 63;
BA_ "GenSigInvalidValue" SG_ 666 MMI_DrvSeatAllLiftPosPercent "0x3F";
BA_ "GenSigSendType" SG_ 666 MMI_DrvSeatHeatControlCmd 3;
BA_ "GenSigInvalidValue" SG_ 666 MMI_DrvSeatHeatControlCmd "0x0";
BA_ "GenSigSendType" SG_ 666 MMI_DrvSeatVenControlCmd 3;
BA_ "GenSigInvalidValue" SG_ 666 MMI_DrvSeatVenControlCmd "0x0";
BA_ "GenSigSendType" SG_ 666 MMI_DrvSeatHandyEntryExitSet 3;
BA_ "GenSigInvalidValue" SG_ 666 MMI_DrvSeatHandyEntryExitSet "0x0";
BA_ "GenMsgSendType" BO_ 668 2;
BA_ "GenMsgCycleTimeFast" BO_ 668 100 ;
BA_ "GenMsgNrOfRepetition" BO_ 668 3 ;
BA_ "GenSigSendType" SG_ 668 MMI_PassSeatSlideCommand 3;
BA_ "GenSigInvalidValue" SG_ 668 MMI_PassSeatSlideCommand "0x0";
BA_ "GenSigSendType" SG_ 668 MMI_PassSeatFrontLiftCommand 3;
BA_ "GenSigInvalidValue" SG_ 668 MMI_PassSeatFrontLiftCommand "0x0";
BA_ "GenSigSendType" SG_ 668 MMI_PassSeatReclinerCommand 3;
BA_ "GenSigInvalidValue" SG_ 668 MMI_PassSeatReclinerCommand "0x0";
BA_ "GenSigSendType" SG_ 668 MMI_PassSeatAllLiftCommand 3;
BA_ "GenSigInvalidValue" SG_ 668 MMI_PassSeatAllLiftCommand "0x0";
BA_ "GenSigSendType" SG_ 668 MMI_PassSeatSlidePosPercentValid 3;
BA_ "GenSigInvalidValue" SG_ 668 MMI_PassSeatSlidePosPercentValid "0x0";
BA_ "GenSigSendType" SG_ 668 MMI_PassSeatSlidePosPercent 3;
BA_ "GenSigStartValue" SG_ 668 MMI_PassSeatSlidePosPercent 63;
BA_ "GenSigInvalidValue" SG_ 668 MMI_PassSeatSlidePosPercent "0x3F";
BA_ "GenSigSendType" SG_ 668 MMI_PassSeatFrontLiftPosPercentValid 3;
BA_ "GenSigInvalidValue" SG_ 668 MMI_PassSeatFrontLiftPosPercentValid "0x0";
BA_ "GenSigSendType" SG_ 668 MMI_PassSeatFrontLiftPosPercent 3;
BA_ "GenSigStartValue" SG_ 668 MMI_PassSeatFrontLiftPosPercent 63;
BA_ "GenSigInvalidValue" SG_ 668 MMI_PassSeatFrontLiftPosPercent "0x3F";
BA_ "GenSigSendType" SG_ 668 MMI_PassSeatReclinerPosPercentValid 3;
BA_ "GenSigInvalidValue" SG_ 668 MMI_PassSeatReclinerPosPercentValid "0x0";
BA_ "GenSigSendType" SG_ 668 MMI_PassSeatReclinerPosPercent 3;
BA_ "GenSigStartValue" SG_ 668 MMI_PassSeatReclinerPosPercent 63;
BA_ "GenSigInvalidValue" SG_ 668 MMI_PassSeatReclinerPosPercent "0x3F";
BA_ "GenSigSendType" SG_ 668 MMI_PassSeatAllLiftPosPercentValid 3;
BA_ "GenSigInvalidValue" SG_ 668 MMI_PassSeatAllLiftPosPercentValid "0x0";
BA_ "GenSigSendType" SG_ 668 MMI_PassSeatAllLiftPosPercent 3;
BA_ "GenSigStartValue" SG_ 668 MMI_PassSeatAllLiftPosPercent 63;
BA_ "GenSigInvalidValue" SG_ 668 MMI_PassSeatAllLiftPosPercent "0x3F";
BA_ "GenSigSendType" SG_ 668 MMI_PassDrvSeatHeatControlCmd 3;
BA_ "GenSigInvalidValue" SG_ 668 MMI_PassDrvSeatHeatControlCmd "0x0";
BA_ "GenSigSendType" SG_ 668 MMI_PassDrvSeatVenControlCmd 3;
BA_ "GenSigInvalidValue" SG_ 668 MMI_PassDrvSeatVenControlCmd "0x0";
BA_ "GenMsgSendType" BO_ 670 2;
BA_ "GenMsgCycleTimeFast" BO_ 670 20 ;
BA_ "GenMsgNrOfRepetition" BO_ 670 3 ;
BA_ "GenSigSendType" SG_ 670 MMI_HazardLightCmd 3;
BA_ "GenSigSendType" SG_ 670 MMI_BCMLightCmd 3;
BA_ "GenSigSendType" SG_ 670 MMI_TailgateCmd 3;
BA_ "GenSigSendType" SG_ 670 MMI_RearViewCmd 3;
BA_ "GenSigSendType" SG_ 670 MMI_DoorLockCmd 3;
BA_ "GenSigSendType" SG_ 670 MMI_LowBeamLightCmd 3;
BA_ "GenSigSendType" SG_ 670 MMI_HighBeamLightCmd 3;
BA_ "GenSigSendType" SG_ 670 MMI_FoglightCmd 3;
BA_ "GenSigSendType" SG_ 670 MMI_WiperCmd 3;
BA_ "GenSigSendType" SG_ 670 MMI_AutolightSWCmd 3;
BA_ "GenSigSendType" SG_ 670 MMI_RainAutoClsWindowCmd 3;
BA_ "GenSigInvalidValue" SG_ 670 MMI_RainAutoClsWindowCmd "0";
BA_ "GenSigSendType" SG_ 670 MMI_ComfortModeSelectCmd 3;
BA_ "GenSigInvalidValue" SG_ 670 MMI_ComfortModeSelectCmd "0x0";
BA_ "GenSigSendType" SG_ 670 MMI_RearViewMirrorSelect 3;
BA_ "GenSigInvalidValue" SG_ 670 MMI_RearViewMirrorSelect "0x0";
BA_ "GenSigSendType" SG_ 670 MMI_RearViewMirrorUpDown 3;
BA_ "GenSigInvalidValue" SG_ 670 MMI_RearViewMirrorUpDown "0x0";
BA_ "GenSigSendType" SG_ 670 MMI_RearViewMirrorLeftRight 3;
BA_ "GenSigInvalidValue" SG_ 670 MMI_RearViewMirrorLeftRight "0x0";
BA_ "GenSigSendType" SG_ 670 MMI_LockVehicleWarmingTip 3;
BA_ "GenSigInvalidValue" SG_ 670 MMI_LockVehicleWarmingTip "0";
BA_ "GenSigSendType" SG_ 670 MMI_UnlockVehicleOpenCourtesyLampSW 3;
BA_ "GenSigInvalidValue" SG_ 670 MMI_UnlockVehicleOpenCourtesyLampSW "0";
BA_ "GenSigSendType" SG_ 670 MMI_AccLampSet 3;
BA_ "GenSigInvalidValue" SG_ 670 MMI_AccLampSet "0";
BA_ "GenSigSendType" SG_ 670 MMI_RearViewMirrorAutoFoldFuc 3;
BA_ "GenSigInvalidValue" SG_ 670 MMI_RearViewMirrorAutoFoldFuc "0";
BA_ "GenSigSendType" SG_ 670 MMI_WiperMaintain 3;
BA_ "GenSigInvalidValue" SG_ 670 MMI_WiperMaintain "0x0";
BA_ "GenMsgSendType" BO_ 638 2;
BA_ "GenMsgCycleTimeFast" BO_ 638 20 ;
BA_ "GenMsgNrOfRepetition" BO_ 638 3 ;
BA_ "GenSigSendType" SG_ 638 MMI_FronLeftDoorWindowCmd 3;
BA_ "GenSigInvalidValue" SG_ 638 MMI_FronLeftDoorWindowCmd "0x0";
BA_ "GenSigSendType" SG_ 638 MMI_FronRightDoorWindowCmd 3;
BA_ "GenSigInvalidValue" SG_ 638 MMI_FronRightDoorWindowCmd "0x0";
BA_ "GenSigSendType" SG_ 638 MMI_RearLeftDoorWindowCmd 3;
BA_ "GenSigInvalidValue" SG_ 638 MMI_RearLeftDoorWindowCmd "0x0";
BA_ "GenSigSendType" SG_ 638 MMI_FourDoorWindowCmd 3;
BA_ "GenSigInvalidValue" SG_ 638 MMI_FourDoorWindowCmd "0x0";
BA_ "GenSigSendType" SG_ 638 MMI_FrontDoorWindowCmd 3;
BA_ "GenSigInvalidValue" SG_ 638 MMI_FrontDoorWindowCmd "0x0";
BA_ "GenSigSendType" SG_ 638 MMI_RainAutoClsWindowCmd 3;
BA_ "GenSigInvalidValue" SG_ 638 MMI_RainAutoClsWindowCmd "0";
BA_ "GenSigSendType" SG_ 638 MMI_RearRightDoorWindowCmd 3;
BA_ "GenSigInvalidValue" SG_ 638 MMI_RearRightDoorWindowCmd "0x0";
BA_ "GenSigInvalidValue" SG_ 638 FLWS_MEM_POS_VIT_FL "0x7F";
BA_ "GenSigInvalidValue" SG_ 638 FRWS_MEM_POS_VIT_FL "0x7F";
BA_ "GenSigInvalidValue" SG_ 638 RLWS_MEM_POS_VIT_FL "0x7F";
BA_ "GenSigInvalidValue" SG_ 638 RRWS_MEM_POS_VIT_FL "0x7F";
BA_ "GenMsgCycleTime" BO_ 792 2000 ;
BA_ "GenSigStartValue" SG_ 792 MMI_LicensePlate_ProvinceName 63;
BA_ "GenSigInvalidValue" SG_ 792 MMI_LicensePlate_ProvinceName "3f";
BA_ "GenSigStartValue" SG_ 792 MMI_LicensePlate_Num1 63;
BA_ "GenSigInvalidValue" SG_ 792 MMI_LicensePlate_Num1 "3f";
BA_ "GenSigStartValue" SG_ 792 MMI_LicensePlate_Num2 63;
BA_ "GenSigInvalidValue" SG_ 792 MMI_LicensePlate_Num2 "3f";
BA_ "GenSigStartValue" SG_ 792 MMI_LicensePlate_Num3 63;
BA_ "GenSigInvalidValue" SG_ 792 MMI_LicensePlate_Num3 "3f";
BA_ "GenSigStartValue" SG_ 792 MMI_LicensePlate_Num4 63;
BA_ "GenSigInvalidValue" SG_ 792 MMI_LicensePlate_Num4 "3f";
BA_ "GenSigStartValue" SG_ 792 MMI_LicensePlate_Num5 63;
BA_ "GenSigInvalidValue" SG_ 792 MMI_LicensePlate_Num5 "3f";
BA_ "GenSigStartValue" SG_ 792 MMI_LicensePlate_Num6 63;
BA_ "GenSigInvalidValue" SG_ 792 MMI_LicensePlate_Num6 "3f";
BA_ "GenSigStartValue" SG_ 792 MMI_LicensePlate_Num7 63;
BA_ "GenSigInvalidValue" SG_ 792 MMI_LicensePlate_Num7 "3f";
BA_ "DiagState" BO_ 1832 1 ;
BA_ "DiagResponse" BO_ 1832 1 ;
BA_ "GenMsgSendType" BO_ 1832 2;
BA_ "GenSigSendType" SG_ 1832 IC_Diagnostic_Data_Request0 2;
BA_ "GenSigSendType" SG_ 1832 IC_Diagnostic_Data_Request1 2;
BA_ "GenSigSendType" SG_ 1832 IC_Diagnostic_Data_Request2 2;
BA_ "GenSigSendType" SG_ 1832 IC_Diagnostic_Data_Request3 2;
BA_ "GenSigSendType" SG_ 1832 IC_Diagnostic_Data_Request4 2;
BA_ "GenSigSendType" SG_ 1832 IC_Diagnostic_Data_Request5 2;
BA_ "GenSigSendType" SG_ 1832 IC_Diagnostic_Data_Request6 2;
BA_ "GenSigSendType" SG_ 1832 IC_Diagnostic_Data_Request7 2;
BA_ "DiagState" BO_ 2015 1 ;
BA_ "DiagResponse" BO_ 2015 1 ;
BA_ "GenMsgSendType" BO_ 2015 2;
BA_ "GenSigSendType" SG_ 2015 Functional_Diag_Data_Request0 2;
BA_ "GenSigSendType" SG_ 2015 Functional_Diag_Data_Request1 2;
BA_ "GenSigSendType" SG_ 2015 Functional_Diag_Data_Request2 2;
BA_ "GenSigSendType" SG_ 2015 Functional_Diag_Data_Request3 2;
BA_ "GenSigSendType" SG_ 2015 Functional_Diag_Data_Request4 2;
BA_ "GenSigSendType" SG_ 2015 Functional_Diag_Data_Request5 2;
BA_ "GenSigSendType" SG_ 2015 Functional_Diag_Data_Request6 2;
BA_ "GenSigSendType" SG_ 2015 Functional_Diag_Data_Request7 2;
BA_ "NmMessage" BO_ 1043 1 ;
BA_ "GenMsgSendType" BO_ 1043 2;
BA_ "GenSigSendType" SG_ 1043 CONF_GW_NM_Message0 2;
BA_ "GenSigSendType" SG_ 1043 CONF_GW_NM_Message1 2;
BA_ "GenSigSendType" SG_ 1043 CONF_GW_NM_Message2 2;
BA_ "GenSigSendType" SG_ 1043 CONF_GW_NM_Message3 2;
BA_ "GenSigSendType" SG_ 1043 CONF_GW_NM_Message4 2;
BA_ "GenSigSendType" SG_ 1043 CONF_GW_NM_Message5 2;
BA_ "GenSigSendType" SG_ 1043 CONF_GW_NM_Message6 2;
BA_ "GenSigSendType" SG_ 1043 CONF_GW_NM_Message7 2;
VAL_ 604 IC_Vehicle_Speed_Available 0 "Unavailable
" 1 "Available"  ;
VAL_ 604 ICU_EBDLampSt 0 "LightOff_with no failure
" 1 "LightOn_with no failure
" 2 "not used
" 3 "Off - failure present"  ;
VAL_ 604 ICU_ABSLampSt 0 "LightOff_with no failure
" 1 "LightOn_with no failure
" 2 "not used
" 3 "Off - failure present"  ;
VAL_ 604 ICU_AirBagSysWrnLmpSts 0 "LightOff_with no failure
" 1 "LightOn_with no failure
" 2 "not used
" 3 "Off - failure present"  ;
VAL_ 604 ICU_PDC_DistanceAlarmDegree_RR 0 "no alarm；
" 1 "alarm 1(距离<40cm)；
" 2 "alarm 2(40cm<距离<65cm)；
" 3 "reserved"  ;
VAL_ 604 ICU_PDC_DistanceAlarmDegree_RL 0 "no alarm；
" 1 "alarm 1(距离<40cm)；
" 2 "alarm 2(40cm<距离<65cm)；
" 3 "reserved"  ;
VAL_ 604 ICU_PDC_DistanceAlarmDegree_RRM 0 "no alarm；
" 1 "alarm 1(距离<40cm)；
" 2 "alarm 2(40cm<距离<100cm)；
" 3 "alarm 3(100cm<距离<150cm)；"  ;
VAL_ 604 ICU_PDC_DistanceAlarmDegree_RLM 0 "no alarm；
" 1 "alarm 1(距离<40cm)；
" 2 "alarm 2(40cm<距离<100cm)；
" 3 "alarm 3(100cm<距离<150cm)；"  ;
VAL_ 620 PAS_PDC_Mode 0 "车型请求模式
" 1 "自检模式
" 2 "正常工作模式
" 3 "停止
" 4 "通讯超时故障
" 5 "Reserved
" 6 "Reserved
" 7 "Reserved"  ;
VAL_ 620 PAS_PDC_SensorSts_RR 0 "normal
" 1 "fault"  ;
VAL_ 620 PAS_PDC_SensorSts_RL 0 "normal
" 1 "fault"  ;
VAL_ 620 PAS_PDC_SensorSts_RRM 0 "normal
" 1 "fault"  ;
VAL_ 620 PAS_PDC_SensorSts_RLM 0 "normal
" 1 "fault"  ;
VAL_ 648 MMI_ACAUTOReqValid 0 "Invalid
" 1 "Valid"  ;
VAL_ 648 MMI_ACAUTOReq 0 "OFF
" 1 "ON"  ;
VAL_ 648 MMI_ACCompressorReqValid 0 "Invalid
" 1 "Valid"  ;
VAL_ 648 MMI_ACCompressorReq 0 "OFF
" 1 "ON"  ;
VAL_ 648 MMI_ACMaxReqValid 0 "Invalid
" 1 "Valid"  ;
VAL_ 648 MMI_ACMaxReq 0 "No Req
" 1 "Req"  ;
VAL_ 648 MMI_ACOFFReqValid 0 "Invalid
" 1 "Valid"  ;
VAL_ 648 MMI_ACOFFReq 0 "No Req
" 1 "OFF"  ;
VAL_ 648 MMI_InsideTempIncDecReqValid 0 "Invalid
" 1 "Valid"  ;
VAL_ 648 MMI_InsideTempIncDecReq 0 "Up
" 1 "Down"  ;
VAL_ 648 MMI_BLOWERReqValid 0 "Invalid
" 1 "Valid"  ;
VAL_ 648 MMI_BLOWERReq 0 "Up
" 1 "Down"  ;
VAL_ 648 MMI_ACBlowModeReqValid 0 "Invalid
" 1 "Valid"  ;
VAL_ 648 MMI_ACBlowModeReq 0 "No Req
" 1 "Face
" 2 "Reserved
" 3 "FootAndDefrost
" 4 "Foot
" 5 "FaceAndFoot
" 6 "reserved
" 7 "reserved"  ;
VAL_ 648 MMI_CirculatingModeSetValid 0 "Invalid
" 1 "Valid"  ;
VAL_ 648 MMI_CirculatingModeSet 0 "车内循环
" 1 "车外循环"  ;
VAL_ 648 MMI_InsideTempSetValid 0 "Invalid
" 1 "Valid"  ;
VAL_ 648 MMI_SeatHeatReq_right 0 "Invalid
" 1 "off
" 2 "1档
" 3 "2档"  ;
VAL_ 648 MMI_SeatHeatReq_left 0 "Invalid
" 1 "off
" 2 "1档
" 3 "2档"  ;
VAL_ 648 MMI_BLOWERGearSetValid 0 "Invalid
" 1 "Valid"  ;
VAL_ 648 MMI_BLOWERGearSet 0 "No req
" 1 "Gear1
" 2 "Gear2
" 3 "Gear3
" 4 "Gear4
" 5 "Gear5
" 6 "Gear6
" 7 "Gear7"  ;
VAL_ 648 MMI_FrontDeforstReq 0 "Invalid
" 1 "On
" 2 "Off
" 3 "Reserved"  ;
VAL_ 648 MMI_RearDeforstReq 0 "Invalid
" 1 "On
" 2 "Off
" 3 "Reserved"  ;
VAL_ 648 MMI_RearViewMirrorHeatReq 0 "invalid
" 1 "open
" 2 "close
" 3 "reserved"  ;
VAL_ 648 MMI_AnionNegativeIonReq 0 "Invalid
" 1 "On
" 2 "Off
" 3 "Reserved"  ;
VAL_ 370 MMI_LDW_Main_Switch 0 "Off
" 1 "On"  ;
VAL_ 370 MMI_LDW_Switch_Available 0 "Available
" 1 "Unavailable"  ;
VAL_ 370 MMI_FCW_Sensitivity 0 "Reserved
" 1 "Level 1
" 2 "Level 2
" 3 "Level 3"  ;
VAL_ 370 MMI_FCW_Main_Switch 0 "Off
" 1 "On"  ;
VAL_ 370 MMI_FCW_Switch_Available 0 "Available
" 1 "Unavailable"  ;
VAL_ 370 MMI_AEB_Main_Switch 0 "Off
" 1 "On"  ;
VAL_ 370 MMI_AEB_Switch_Available 0 "Available
" 1 "Unavailable"  ;
VAL_ 370 MMI_TSR_Main_Switch 0 "Off
" 1 "On"  ;
VAL_ 370 MMI_TSR_Switch_Available 0 "Available
" 1 "Unavailable"  ;
VAL_ 370 MMI_IHC_Main_Switch 0 "Off
" 1 "On"  ;
VAL_ 370 MMI_IHC_Switch_Available 0 "Available
" 1 "Unavailable"  ;
VAL_ 370 MMI_LDW_Sensitivity 0 "Reserved
" 1 "Low
" 2 "Normal
" 3 "High"  ;
VAL_ 370 MMI_BSD_Main_Switch 0 "Off
" 1 "On"  ;
VAL_ 370 MMI_BSD_Switch_Available 0 "Unavailable
" 1 "Available"  ;
VAL_ 370 MMI_BSD_Sensitivity 0 "Reserved
" 1 "Low
" 2 "Normal
" 3 "High"  ;
VAL_ 370 MMI_EPS_ModeSwitch 0 "Invalid
" 1 "normal正常
" 2 "sport运动
" 3 "reserved
" 4 "reserved
" 5 "reserved
" 6 "reserved
" 7 "reserved"  ;
VAL_ 370 MMI_PauseContinueChrgRQ 0 "invalid
" 1 "暂停充电
" 2 "继续充电
" 3 "reserved"  ;
VAL_ 370 MMI_WCBS_CstSwitch 0 "Off
" 1 "On"  ;
VAL_ 370 MMI_WCBS_HDCSwitch 0 "Off
" 1 "On"  ;
VAL_ 370 MMI_OperationMode 0 "Reserved保留
" 1 "normal正常
" 2 "Economic经济
" 3 "Sport运动
" 4 "User define自定义
" 5 "Reserved
" 6 "Reserved
" 7 "Reserved"  ;
VAL_ 370 MMI_ChrgCurrentSet 0 "invalid"  ;
VAL_ 370 MMI_EnergyRecoveryContr 0 "Invalid
" 1 "Lev0
" 2 "Lev1
" 3 "Lev2
" 4 "Lev3
" 5 "reserved
" 6 "reserved
" 7 "reserved"  ;
VAL_ 370 MMI_LKA_Main_Switch 0 "Off
" 1 "On"  ;
VAL_ 370 MMI_LKA_Switch_Available 0 "Unavailable
" 1 "Available"  ;
VAL_ 630 MMI_AVM_ConnectStatus 0 "none(解决车机晚于AVM启动。AVM侧此状态可认为车机默认为已连接处理)
" 1 "disconnect
" 2 "connected
" 15 "invalid"  ;
VAL_ 630 MMI_AVM_LanguageSet 0 "none
" 1 "English
" 2 "Chinese
" 3 "reserved
" 4 "reserved
" 5 "reserved
" 6 "reserved
" 7 "reserved
" 8 "reserved
" 9 "reserved
" 10 "reserved
" 11 "reserved
" 12 "reserved
" 13 "reserved
" 14 "reserved
" 15 "invalid"  ;
VAL_ 630 MMI_AVM_AVM3DDynTrajSet 0 "none
" 1 "off
" 2 "on
" 3 "invalid"  ;
VAL_ 630 MMI_AVM_AVM3DExitDelaySet 0 "none
" 1 "off
" 2 "on
" 3 "invalid"  ;
VAL_ 630 MMI_AVM_AVM3DTurnLightSet 0 "none
" 1 "off
" 2 "on
" 3 "invalid"  ;
VAL_ 630 MMI_AVM_AVM3DBlindFillSet 0 "none
" 1 "off
" 2 "on
" 3 "invalid"  ;
VAL_ 630 MMI_AVM_BSDFunction 0 "none
" 1 "off
" 2 "on
" 3 "invalid"  ;
VAL_ 630 MMI_AVM_OTFunction 0 "none
" 1 "off
" 2 "on
" 3 "invalid"  ;
VAL_ 630 MMI_AVM_AVM3DCarIconColor 0 "none
" 1 "red
" 2 "yellow
" 3 "blue
" 4 "white
" 5 "black
" 6 "reserved
" 7 "reserved
" 8 "reserved
" 9 "reserved
" 10 "reserved
" 11 "reserved
" 12 "reserved
" 13 "reserved
" 14 "reserved
" 15 "invalid"  ;
VAL_ 630 MMI_AVM_AVM3DCarIconTransparenValid 0 "none
" 1 "valid/有效时，才能使用AVM3D车模透明度
" 2 "reserved
" 3 "invalid"  ;
VAL_ 630 MMI_AVM_VideoOutputStatus 0 "none/显示MMI画面
" 1 "off/显示MMI画面
" 2 "on/显示AVM画面
" 3 "invalid/显示MMI画面
" 4 "reserved
" 5 "reserved
" 6 "reserved
" 7 "reserved
" 8 "reserved
" 9 "reserved
" 10 "reserved
" 11 "reserved
" 12 "reserved
" 13 "reserved
" 14 "reserved
" 15 "invalid"  ;
VAL_ 630 MMI_AVM_AVM3DCarIconTransparent 0 "车模透明度的0~100%
" 1 "车模透明度的0~100%
" 2 "车模透明度的0~100%
" 3 "车模透明度的0~100%
" 4 "车模透明度的0~100%
" 5 "车模透明度的0~100%
" 6 "车模透明度的0~100%
" 7 "车模透明度的0~100%
" 8 "车模透明度的0~100%
" 9 "车模透明度的0~100%
" 10 "车模透明度的0~100%
" 11 "车模透明度的0~100%
" 12 "车模透明度的0~100%
" 13 "车模透明度的0~100%
" 14 "车模透明度的0~100%
" 15 "车模透明度的0~100%
" 16 "车模透明度的0~100%
" 17 "车模透明度的0~100%
" 18 "车模透明度的0~100%
" 19 "车模透明度的0~100%
" 20 "车模透明度的0~100%
" 21 "车模透明度的0~100%
" 22 "车模透明度的0~100%
" 23 "车模透明度的0~100%
" 24 "车模透明度的0~100%
" 25 "车模透明度的0~100%
" 26 "车模透明度的0~100%
" 27 "车模透明度的0~100%
" 28 "车模透明度的0~100%
" 29 "车模透明度的0~100%
" 30 "车模透明度的0~100%
" 31 "车模透明度的0~100%
" 32 "车模透明度的0~100%
" 33 "车模透明度的0~100%
" 34 "车模透明度的0~100%
" 35 "车模透明度的0~100%
" 36 "车模透明度的0~100%
" 37 "车模透明度的0~100%
" 38 "车模透明度的0~100%
" 39 "车模透明度的0~100%
" 40 "车模透明度的0~100%
" 41 "车模透明度的0~100%
" 42 "车模透明度的0~100%
" 43 "车模透明度的0~100%
" 44 "车模透明度的0~100%
" 45 "车模透明度的0~100%
" 46 "车模透明度的0~100%
" 47 "车模透明度的0~100%
" 48 "车模透明度的0~100%
" 49 "车模透明度的0~100%
" 50 "车模透明度的0~100%
" 51 "车模透明度的0~100%
" 52 "车模透明度的0~100%
" 53 "车模透明度的0~100%
" 54 "车模透明度的0~100%
" 55 "车模透明度的0~100%
" 56 "车模透明度的0~100%
" 57 "车模透明度的0~100%
" 58 "车模透明度的0~100%
" 59 "车模透明度的0~100%
" 60 "车模透明度的0~100%
" 61 "车模透明度的0~100%
" 62 "车模透明度的0~100%
" 63 "车模透明度的0~100%
" 64 "车模透明度的0~100%
" 65 "车模透明度的0~100%
" 66 "车模透明度的0~100%
" 67 "车模透明度的0~100%
" 68 "车模透明度的0~100%
" 69 "车模透明度的0~100%
" 70 "车模透明度的0~100%
" 71 "车模透明度的0~100%
" 72 "车模透明度的0~100%
" 73 "车模透明度的0~100%
" 74 "车模透明度的0~100%
" 75 "车模透明度的0~100%
" 76 "车模透明度的0~100%
" 77 "车模透明度的0~100%
" 78 "车模透明度的0~100%
" 79 "车模透明度的0~100%
" 80 "车模透明度的0~100%
" 81 "车模透明度的0~100%
" 82 "车模透明度的0~100%
" 83 "车模透明度的0~100%
" 84 "车模透明度的0~100%
" 85 "车模透明度的0~100%
" 86 "车模透明度的0~100%
" 87 "车模透明度的0~100%
" 88 "车模透明度的0~100%
" 89 "车模透明度的0~100%
" 90 "车模透明度的0~100%
" 91 "车模透明度的0~100%
" 92 "车模透明度的0~100%
" 93 "车模透明度的0~100%
" 94 "车模透明度的0~100%
" 95 "车模透明度的0~100%
" 96 "车模透明度的0~100%
" 97 "车模透明度的0~100%
" 98 "车模透明度的0~100%
" 99 "车模透明度的0~100%
" 100 "车模透明度的0~100%
" 255 "invalid"  ;
VAL_ 630 MMI_AmphereLampCtrl_Colour 0 "默认颜色
" 1 "红色
" 2 "橙色
" 3 "黄色
" 4 "绿色
" 5 "青色
" 6 "蓝色
" 7 "紫色
" 8 "Reserved
" 9 "Reserved
" 10 "Reserved
" 11 "Reserved
" 12 "Reserved
" 13 "Reserved
" 14 "Reserved
" 15 "Reserved"  ;
VAL_ 630 MMI_AmphereLampCtrl_Fleshmode 0 "无效
" 1 "打开普通呼吸模式
" 2 "打开车速呼吸模式
" 3 "打开人脸识别呼吸模式
" 4 "保留
" 5 "保留
" 6 "保留
" 7 "保留"  ;
VAL_ 630 MMI_AmphereLampCtrl_Drivingmode 0 "Invalid
" 1 "打开驾驶模式
" 2 "关闭驾驶模式
" 3 "保留"  ;
VAL_ 630 MMI_AmphereLampCtrl_SW 0 "Invalid
" 1 "OFF
" 2 "ON
" 3 "Reserved"  ;
VAL_ 632 MMI_AVMTouchEventType 0 "Invalid
" 1 "GESTURE_ONE_FINGER_DOWN
" 2 "GESTURE_ONE_FINGER_UP
" 3 "GESTURE_ONE_FINGER_SINGLE_CLICK
" 4 "GESTURE_ONE_FINGER_DOUBLE_CLICK
" 5 "GESTURE_ONE_FINGER_LONG_PRESS
" 6 "GESTURE_ONE_FINGER_MOVING
" 7 "GESTURE_ONE_FINGER_SWIPE
" 8 "GESTURE_ZOOM_IN
" 9 "GESTURE_ZOOM_OUT
" 10 "GESTURE_ROTATE
" 11 "Reserved
" 12 "Reserved
" 13 "Reserved
" 14 "Reserved
" 15 "Reserved"  ;
VAL_ 634 MMI_AVM_AVM3D_COMMAND 0 "none
" 1 "clear otf calibration data
" 15 "invalid"  ;
VAL_ 634 MMI_AVM_AVM3DViewModeSwitch 0 "none
" 1 "2d
" 2 "3d
" 3 "speed3D
" 4 "Ctv_Front
" 5 "Ctv_Rear
" 6 "Rim_Front
" 7 "Rim_Rear
" 8 "reserved
" 9 "reserved
" 10 "reserved
" 11 "reserved
" 12 "reserved
" 13 "reserved
" 14 "reserved
" 15 "invalid"  ;
VAL_ 634 MMI_AVM_AVMEcuEnterExit 0 "none
" 1 "avm3d_enter_softkey
" 2 "avm3d_enter_hardkey
" 3 "avm3d_enter_gesture
" 4 "avm3d_enter_recognition
" 5 "reserved
" 6 "reserved
" 7 "reserved
" 8 "avm3d_exit_softkey
" 9 "avm3d_exit_hardkey
" 10 "avm3d_exit_gesture
" 11 "avm3d_exit_recognition
" 16 "reserved
" 17 "calibration enter/标定只有进入，禁止从车机请求退出"  ;
VAL_ 634 MMI_AVM_AVM3DViewSwitch 0 "none
" 1 "2d_front
" 2 "2d_right
" 3 "2d_left
" 4 "2d_rear
" 5 "reserved
" 6 "reserved
" 7 "reserved
" 8 "reserved
" 9 "reserved
" 10 "reserved
" 11 "reserved
" 12 "reserved
" 13 "reserved
" 14 "reserved
" 15 "reserved
" 16 "reserved
" 17 "3d_front
" 18 "3d_right
" 19 "3d_left
" 20 "3d_rear
" 21 "3d_right_front
" 22 "3d_left_front
" 23 "3d_left_rear
" 24 "3d_right_rear
" 25 "reserved
" 26 "reserved
" 27 "reserved
" 28 "reserved
" 29 "reserved
" 30 "reserved
" 31 "reserved
" 32 "reserved
" 33 "reserved
" 34 "reserved
" 35 "reserved
" 36 "reserved
" 37 "reserved
" 38 "reserved
" 39 "reserved
" 40 "reserved
" 41 "reserved
" 42 "reserved
" 43 "reserved
" 44 "reserved
" 45 "reserved
" 46 "reserved
" 47 "reserved
" 48 "reserved
" 49 "reserved
" 50 "reserved
" 51 "reserved
" 52 "reserved
" 53 "reserved
" 54 "reserved
" 55 "reserved
" 56 "reserved
" 57 "reserved
" 58 "reserved
" 59 "reserved
" 60 "reserved
" 61 "reserved
" 62 "reserved
" 63 "reserved
" 64 "reserved
" 65 "reserved
" 66 "reserved
" 67 "reserved
" 68 "reserved
" 69 "reserved
" 70 "reserved
" 71 "reserved
" 72 "reserved
" 73 "reserved
" 74 "reserved
" 75 "reserved
" 76 "reserved
" 77 "reserved
" 78 "reserved
" 79 "reserved
" 80 "reserved
" 81 "reserved
" 82 "reserved
" 83 "reserved
" 84 "reserved
" 85 "reserved
" 86 "reserved
" 87 "reserved
" 88 "reserved
" 89 "reserved
" 90 "reserved
" 91 "reserved
" 92 "reserved
" 93 "reserved
" 94 "reserved
" 95 "reserved
" 96 "reserved
" 97 "reserved
" 98 "reserved
" 99 "reserved
" 100 "reserved
" 101 "reserved
" 102 "reserved
" 103 "reserved
" 104 "reserved
" 105 "reserved
" 106 "reserved
" 107 "reserved
" 108 "reserved
" 109 "reserved
" 110 "reserved
" 111 "reserved
" 112 "reserved
" 113 "reserved
" 114 "reserved
" 115 "reserved
" 116 "reserved
" 117 "reserved
" 118 "reserved
" 119 "reserved
" 120 "reserved
" 121 "reserved
" 122 "reserved
" 123 "reserved
" 124 "reserved
" 125 "reserved
" 126 "reserved
" 127 "reserved
" 128 "reserved
" 129 "reserved
" 130 "reserved
" 131 "reserved
" 132 "reserved
" 133 "reserved
" 134 "reserved
" 135 "reserved
" 136 "reserved
" 137 "reserved
" 138 "reserved
" 139 "reserved
" 140 "reserved
" 141 "reserved
" 142 "reserved
" 143 "reserved
" 144 "reserved
" 145 "reserved
" 146 "reserved
" 147 "reserved
" 148 "reserved
" 149 "reserved
" 150 "reserved
" 151 "reserved
" 152 "reserved
" 153 "reserved
" 154 "reserved
" 155 "reserved
" 156 "reserved
" 157 "reserved
" 158 "reserved
" 159 "reserved
" 160 "reserved
" 161 "reserved
" 162 "reserved
" 163 "reserved
" 164 "reserved
" 165 "reserved
" 166 "reserved
" 167 "reserved
" 168 "reserved
" 169 "reserved
" 170 "reserved
" 171 "reserved
" 172 "reserved
" 173 "reserved
" 174 "reserved
" 175 "reserved
" 176 "reserved
" 177 "reserved
" 178 "reserved
" 179 "reserved
" 180 "reserved
" 181 "reserved
" 182 "reserved
" 183 "reserved
" 184 "reserved
" 185 "reserved
" 186 "reserved
" 187 "reserved
" 188 "reserved
" 189 "reserved
" 190 "reserved
" 191 "reserved
" 192 "reserved
" 193 "reserved
" 194 "reserved
" 195 "reserved
" 196 "reserved
" 197 "reserved
" 198 "reserved
" 199 "reserved
" 200 "reserved
" 201 "reserved
" 202 "reserved
" 203 "reserved
" 204 "reserved
" 205 "reserved
" 206 "reserved
" 207 "reserved
" 208 "reserved
" 209 "reserved
" 210 "reserved
" 211 "reserved
" 212 "reserved
" 213 "reserved
" 214 "reserved
" 215 "reserved
" 216 "reserved
" 217 "reserved
" 218 "reserved
" 219 "reserved
" 220 "reserved
" 221 "reserved
" 222 "reserved
" 223 "reserved
" 224 "reserved
" 225 "reserved
" 226 "reserved
" 227 "reserved
" 228 "reserved
" 229 "reserved
" 230 "reserved
" 231 "reserved
" 232 "reserved
" 233 "reserved
" 234 "reserved
" 235 "reserved
" 236 "reserved
" 237 "reserved
" 238 "reserved
" 239 "reserved
" 240 "reserved
" 241 "reserved
" 242 "reserved
" 243 "reserved
" 244 "reserved
" 245 "reserved
" 246 "reserved
" 247 "reserved
" 248 "reserved
" 249 "reserved
" 250 "reserved
" 251 "reserved
" 252 "reserved
" 253 "reserved
" 254 "reserved
" 255 "reserved"  ;
VAL_ 652 MMI_PermanentCmd 0 "无效
" 1 "永久开（永久性翻转VSP状态开）
" 2 "永久关（永久性翻转VSP状态关）
" 3 "保留"  ;
VAL_ 652 MMI_ShorterCmd 0 "无效
" 1 "临时开（临时性翻转VSP状态开）
" 2 "临时关（临时性翻转VSP状态关）
" 3 "保留"  ;
VAL_ 652 MMI_StopModeCmd 0 "停车模式开
" 1 "停车模式关"  ;
VAL_ 652 MMI_VoiceSourceCmd 0 "Invalid
" 1 "选择声源1
" 2 "选择声源2
" 3 "选择声源3
" 4 "选择声源4
" 5 "选择声源5
" 6 "选择声源6
" 7 "选择声源7"  ;
VAL_ 652 MMI_PlatfondPellucidity 127 " Invalid" 0 "0%~100%" 1 "0%~100%" 2 "0%~100%" 3 "0%~100%" 4 "0%~100%" 5 "0%~100%" 6 "0%~100%" 7 "0%~100%" 8 "0%~100%" 9 "0%~100%" 10 "0%~100%" 11 "0%~100%" 12 "0%~100%" 13 "0%~100%" 14 "0%~100%" 15 "0%~100%" 16 "0%~100%" 17 "0%~100%" 18 "0%~100%" 19 "0%~100%" 20 "0%~100%" 21 "0%~100%" 22 "0%~100%" 23 "0%~100%" 24 "0%~100%" 25 "0%~100%" 26 "0%~100%" 27 "0%~100%" 28 "0%~100%" 29 "0%~100%" 30 "0%~100%" 31 "0%~100%" 32 "0%~100%" 33 "0%~100%" 34 "0%~100%" 35 "0%~100%" 36 "0%~100%" 37 "0%~100%" 38 "0%~100%" 39 "0%~100%" 40 "0%~100%" 41 "0%~100%" 42 "0%~100%" 43 "0%~100%" 44 "0%~100%" 45 "0%~100%" 46 "0%~100%" 47 "0%~100%" 48 "0%~100%" 49 "0%~100%" 50 "0%~100%" 51 "0%~100%" 52 "0%~100%" 53 "0%~100%" 54 "0%~100%" 55 "0%~100%" 56 "0%~100%" 57 "0%~100%" 58 "0%~100%" 59 "0%~100%" 60 "0%~100%" 61 "0%~100%" 62 "0%~100%" 63 "0%~100%" 64 "0%~100%" 65 "0%~100%" 66 "0%~100%" 67 "0%~100%" 68 "0%~100%" 69 "0%~100%" 70 "0%~100%" 71 "0%~100%" 72 "0%~100%" 73 "0%~100%" 74 "0%~100%" 75 "0%~100%" 76 "0%~100%" 77 "0%~100%" 78 "0%~100%" 79 "0%~100%" 80 "0%~100%" 81 "0%~100%" 82 "0%~100%" 83 "0%~100%" 84 "0%~100%" 85 "0%~100%" 86 "0%~100%" 87 "0%~100%" 88 "0%~100%" 89 "0%~100%" 90 "0%~100%" 91 "0%~100%" 92 "0%~100%" 93 "0%~100%" 94 "0%~100%" 95 "0%~100%" 96 "0%~100%" 97 "0%~100%" 98 "0%~100%" 99 "0%~100%" 100 "0%~100%"  ;
VAL_ 652 MMI_CWC_Cmd 0 "Invalid
" 1 "打开
" 2 "关闭
" 3 "reserve"  ;
VAL_ 666 MMI_DrvSeatSlideCommand 0 "invalid
" 1 "停止调节
" 2 "向前调节
" 3 "向后调节"  ;
VAL_ 666 MMI_DrvSeatFrontLiftCommand 0 "invalid
" 1 "停止调节
" 2 "向上调节
" 3 "向下调节"  ;
VAL_ 666 MMI_DrvSeatReclinerCommand 0 "invalid
" 1 "停止调节
" 2 "向前调节
" 3 "向后调节"  ;
VAL_ 666 MMI_DrvSeatAllLiftCommand 0 "invalid
" 1 "停止调节
" 2 "向上调节
" 3 "向下调节"  ;
VAL_ 666 MMI_DrvSeatSlidePosPercentValid 0 "invalid
" 1 "有效"  ;
VAL_ 666 MMI_DrvSeatFrontLiftPosPercentValid 0 "invalid
" 1 "有效"  ;
VAL_ 666 MMI_DrvSeatReclinerPosPercentValid 0 "invalid
" 1 "有效"  ;
VAL_ 666 MMI_DrvSeatAllLiftPosPercentValid 0 "invalid
" 1 "有效"  ;
VAL_ 666 MMI_DrvSeatHeatControlCmd 0 "Invalid
" 1 "OFF
" 2 "Heating Level 1
" 3 "Heating Level 2
" 4 "Heating Level 3
" 5 "reserved
" 6 "reserved
" 7 "reserved"  ;
VAL_ 666 MMI_DrvSeatVenControlCmd 0 "Invalid
" 1 "OFF
" 2 "Venting Level 1
" 3 "Venting Level 2
" 4 "Venting Level 3
" 5 "reserved
" 6 "reserved
" 7 "reserved"  ;
VAL_ 666 MMI_DrvSeatHandyEntryExitSet 0 "invalid
" 1 "Open
" 2 "Close
" 3 "Reserved"  ;
VAL_ 668 MMI_PassSeatSlideCommand 0 "invalid
" 1 "停止调节
" 2 "向前调节
" 3 "向后调节"  ;
VAL_ 668 MMI_PassSeatFrontLiftCommand 0 "invalid
" 1 "停止调节
" 2 "向上调节
" 3 "向下调节"  ;
VAL_ 668 MMI_PassSeatReclinerCommand 0 "invalid
" 1 "停止调节
" 2 "向前调节
" 3 "向后调节"  ;
VAL_ 668 MMI_PassSeatAllLiftCommand 0 "invalid
" 1 "停止调节
" 2 "向上调节
" 3 "向下调节"  ;
VAL_ 668 MMI_PassSeatSlidePosPercentValid 0 "invalid
" 1 "有效"  ;
VAL_ 668 MMI_PassSeatFrontLiftPosPercentValid 0 "invalid
" 1 "有效"  ;
VAL_ 668 MMI_PassSeatReclinerPosPercentValid 0 "invalid
" 1 "有效"  ;
VAL_ 668 MMI_PassSeatAllLiftPosPercentValid 0 "invalid
" 1 "有效"  ;
VAL_ 668 MMI_PassDrvSeatHeatControlCmd 0 "Invalid
" 1 "OFF
" 2 "Heating Level 1
" 3 "Heating Level 2
" 4 "Heating Level 3
" 5 "reserved
" 6 "reserved
" 7 "reserved"  ;
VAL_ 668 MMI_PassDrvSeatVenControlCmd 0 "Invalid
" 1 "OFF
" 2 "Venting Level 1
" 3 "Venting Level 2
" 4 "Venting Level 3
" 5 "reserved
" 6 "reserved
" 7 "reserved"  ;
VAL_ 670 MMI_HazardLightCmd 0 "无指令
" 1 "打开
" 2 "关闭"  ;
VAL_ 670 MMI_BCMLightCmd 0 "无指令
" 1 "打开
" 2 "关闭"  ;
VAL_ 670 MMI_TailgateCmd 0 "无指令
" 1 "尾门打开
" 2 "尾门关闭"  ;
VAL_ 670 MMI_RearViewCmd 0 "无指令
" 1 "后视镜折叠
" 2 "后视镜展开"  ;
VAL_ 670 MMI_DoorLockCmd 0 "无指令
" 1 "打开锁
" 2 "关闭锁"  ;
VAL_ 670 MMI_LowBeamLightCmd 0 "无指令
" 1 "打开
" 2 "关闭"  ;
VAL_ 670 MMI_HighBeamLightCmd 0 "无指令
" 1 "打开
" 2 "关闭"  ;
VAL_ 670 MMI_FoglightCmd 0 "无指令
" 1 "打开
" 2 "关闭"  ;
VAL_ 670 MMI_WiperCmd 0 "无指令
" 1 "点动
" 2 "间歇1档
" 3 "间歇2档
" 4 "间歇3档
" 5 "低速
" 6 "高速
" 7 "停止"  ;
VAL_ 670 MMI_AutolightSWCmd 0 "无指令
" 1 "打开
" 2 "关闭"  ;
VAL_ 670 MMI_RainAutoClsWindowCmd 0 " invalid" 1 " Open" 2 " Close" 3 " Reserved"  ;
VAL_ 670 MMI_ComfortModeSelectCmd 0 " 默认模式/无露营" 1 " 模式1" 2 " 模式2" 3 " 模式3"  ;
VAL_ 670 MMI_RearViewMirrorSelect 0 "Invalid
" 1 "左后视镜
" 2 "右后视镜
" 3 "Reserved"  ;
VAL_ 670 MMI_RearViewMirrorUpDown 0 "Invalid
" 1 "上调
" 2 "下调
" 3 "Reserved"  ;
VAL_ 670 MMI_RearViewMirrorLeftRight 0 "Invalid
" 1 "左调
" 2 "右调
" 3 "Reserved"  ;
VAL_ 670 MMI_LockVehicleWarmingTip 0 "invalid
" 1 "flash
" 2 "flash with horn
" 3 "Reserved"  ;
VAL_ 670 MMI_UnlockVehicleOpenCourtesyLampSW 0 "invalid
" 1 "close
" 2 "open
" 3 "Reserved"  ;
VAL_ 670 MMI_AccLampSet 0 "invalid
" 1 "close
" 2 "开启(延迟30s关闭)
" 3 "开启(延迟60s关闭)"  ;
VAL_ 670 MMI_RearViewMirrorAutoFoldFuc 0 "invalid
" 1 "close
" 2 "open
" 3 "Reserved"  ;
VAL_ 670 MMI_WiperMaintain 0 "Invalid
" 1 "close
" 2 "open
" 3 "Reserved"  ;
VAL_ 638 MMI_FronLeftDoorWindowCmd 0 "Invalid
" 1 "一键降主驾窗
" 2 "一键升主驾窗
" 3 "点动降主驾窗
" 4 "点动升主驾窗                                                                    0x5～0x7"  ;
VAL_ 638 MMI_FronRightDoorWindowCmd 0 "Invalid
" 1 "一键降副驾窗
" 2 "一键升副驾窗
" 3 "点动降副驾窗
" 4 "点动升副驾窗                                                                    0x5～0x7"  ;
VAL_ 638 MMI_RearLeftDoorWindowCmd 0 "Invalid
" 1 "一键降左后窗
" 2 "一键升左后窗
" 3 "点动降左后窗
" 4 "点动升左后窗                                                                    0x5～0x7"  ;
VAL_ 638 MMI_FourDoorWindowCmd 0 "Invalid
" 1 "一键降四门车窗
" 2 "一键升四门车窗
" 3 "Reserved"  ;
VAL_ 638 MMI_FrontDoorWindowCmd 0 "Invalid
" 1 "一键降前车窗至10%(透气)
" 2 "一键降前车窗至30%(通风)
" 3 "Reserved"  ;
VAL_ 638 MMI_RainAutoClsWindowCmd 0 "invalid
" 1 "Open
" 2 "Close
" 3 "Reserved"  ;
VAL_ 638 MMI_RearRightDoorWindowCmd 0 "Invalid
" 1 "一键降右后窗
" 2 "一键升右后窗
" 3 "点动降右后窗
" 4 "点动升右后窗                                                                    0x5～0x7"  ;
VAL_ 792 MMI_LicensePlate_ProvinceName 0 "none；
" 1 "京；
" 2 "津；
" 3 "沪；
" 4 "渝；
" 5 "冀；
" 6 "晋；
" 7 "辽；
" 8 "吉；
" 9 "黑；
" 10 "苏；
" 11 "浙；
" 12 "皖；
" 13 "闽；
" 14 "赣；
" 15 "鲁；
" 16 "豫；
" 17 "鄂；
" 18 "湘；
" 19 "粤；
" 20 "琼；
" 21 "川；
" 22 "贵；
" 23 "云；
" 24 "陕；
" 25 "甘；
" 26 "青；
" 27 "桂；
" 28 "蒙；
" 29 "藏；
" 30 "宁；
" 31 "新；
" 63 "invalid"  ;
VAL_ 792 MMI_LicensePlate_Num1 0 "none；
" 1 "A；
" 2 "B；
" 3 "C；
" 4 "D；
" 5 "E；
" 6 "F；
" 7 "G；
" 8 "H；
" 9 "I；
" 10 "J；
" 11 "K；
" 12 "L；
" 13 "M；
" 14 "N；
" 15 "O；
" 16 "P；
" 17 "Q；
" 18 "R；
" 19 "S；
" 20 "T；
" 21 "U；
" 22 "V；
" 23 "W；
" 24 "X；
" 25 "Y；
" 26 "Z；
" 27 "0；
" 28 "1
" 29 "2；
" 30 "3；
" 31 "4；
" 32 "5；
" 33 "6
" 34 "7；
" 35 "8；
" 36 "9；
" 63 "invalid"  ;
VAL_ 792 MMI_LicensePlate_Num2 0 "none；
" 1 "A；
" 2 "B；
" 3 "C；
" 4 "D；
" 5 "E；
" 6 "F；
" 7 "G；
" 8 "H；
" 9 "I；
" 10 "J；
" 11 "K；
" 12 "L；
" 13 "M；
" 14 "N；
" 15 "O；
" 16 "P；
" 17 "Q；
" 18 "R；
" 19 "S；
" 20 "T；
" 21 "U；
" 22 "V；
" 23 "W；
" 24 "X；
" 25 "Y；
" 26 "Z；
" 27 "0；
" 28 "1
" 29 "2；
" 30 "3；
" 31 "4；
" 32 "5；
" 33 "6
" 34 "7；
" 35 "8；
" 36 "9；
" 63 "invalid"  ;
VAL_ 792 MMI_LicensePlate_Num3 0 "none；
" 1 "A；
" 2 "B；
" 3 "C；
" 4 "D；
" 5 "E；
" 6 "F；
" 7 "G；
" 8 "H；
" 9 "I；
" 10 "J；
" 11 "K；
" 12 "L；
" 13 "M；
" 14 "N；
" 15 "O；
" 16 "P；
" 17 "Q；
" 18 "R；
" 19 "S；
" 20 "T；
" 21 "U；
" 22 "V；
" 23 "W；
" 24 "X；
" 25 "Y；
" 26 "Z；
" 27 "0；
" 28 "1
" 29 "2；
" 30 "3；
" 31 "4；
" 32 "5；
" 33 "6
" 34 "7；
" 35 "8；
" 36 "9；
" 63 "invalid"  ;
VAL_ 792 MMI_LicensePlate_Num4 0 "none；
" 1 "A；
" 2 "B；
" 3 "C；
" 4 "D；
" 5 "E；
" 6 "F；
" 7 "G；
" 8 "H；
" 9 "I；
" 10 "J；
" 11 "K；
" 12 "L；
" 13 "M；
" 14 "N；
" 15 "O；
" 16 "P；
" 17 "Q；
" 18 "R；
" 19 "S；
" 20 "T；
" 21 "U；
" 22 "V；
" 23 "W；
" 24 "X；
" 25 "Y；
" 26 "Z；
" 27 "0；
" 28 "1
" 29 "2；
" 30 "3；
" 31 "4；
" 32 "5；
" 33 "6
" 34 "7；
" 35 "8；
" 36 "9；
" 63 "invalid"  ;
VAL_ 792 MMI_LicensePlate_Num5 0 "none；
" 1 "A；
" 2 "B；
" 3 "C；
" 4 "D；
" 5 "E；
" 6 "F；
" 7 "G；
" 8 "H；
" 9 "I；
" 10 "J；
" 11 "K；
" 12 "L；
" 13 "M；
" 14 "N；
" 15 "O；
" 16 "P；
" 17 "Q；
" 18 "R；
" 19 "S；
" 20 "T；
" 21 "U；
" 22 "V；
" 23 "W；
" 24 "X；
" 25 "Y；
" 26 "Z；
" 27 "0；
" 28 "1
" 29 "2；
" 30 "3；
" 31 "4；
" 32 "5；
" 33 "6
" 34 "7；
" 35 "8；
" 36 "9；
" 63 "invalid"  ;
VAL_ 792 MMI_LicensePlate_Num6 0 "none；
" 1 "A；
" 2 "B；
" 3 "C；
" 4 "D；
" 5 "E；
" 6 "F；
" 7 "G；
" 8 "H；
" 9 "I；
" 10 "J；
" 11 "K；
" 12 "L；
" 13 "M；
" 14 "N；
" 15 "O；
" 16 "P；
" 17 "Q；
" 18 "R；
" 19 "S；
" 20 "T；
" 21 "U；
" 22 "V；
" 23 "W；
" 24 "X；
" 25 "Y；
" 26 "Z；
" 27 "0；
" 28 "1
" 29 "2；
" 30 "3；
" 31 "4；
" 32 "5；
" 33 "6
" 34 "7；
" 35 "8；
" 36 "9；
" 63 "invalid"  ;
VAL_ 792 MMI_LicensePlate_Num7 0 "none；
" 1 "A；
" 2 "B；
" 3 "C；
" 4 "D；
" 5 "E；
" 6 "F；
" 7 "G；
" 8 "H；
" 9 "I；
" 10 "J；
" 11 "K；
" 12 "L；
" 13 "M；
" 14 "N；
" 15 "O；
" 16 "P；
" 17 "Q；
" 18 "R；
" 19 "S；
" 20 "T；
" 21 "U；
" 22 "V；
" 23 "W；
" 24 "X；
" 25 "Y；
" 26 "Z；
" 27 "0；
" 28 "1
" 29 "2；
" 30 "3；
" 31 "4；
" 32 "5；
" 33 "6
" 34 "7；
" 35 "8；
" 36 "9；
" 63 "invalid"  ;
VAL_ 342 SteerWheel_L_OK 0 "not pressed
" 1 "pressed"  ;
VAL_ 342 SteerWheel_Voice 0 "not pressed
" 1 "pressed"  ;
VAL_ 342 SteerWheel_VOL_Inc 0 "not pressed
" 1 "pressed"  ;
VAL_ 342 SteerWheel_VOL_Dec 0 "not pressed
" 1 "pressed"  ;
VAL_ 342 SteerWheel_PREV 0 "not pressed
" 1 "pressed"  ;
VAL_ 342 SteerWheel_Defi 0 "not pressed
" 1 "pressed"  ;
VAL_ 342 SteerWheel_NEXT 0 "not pressed
" 1 "pressed"  ;
VAL_ 342 SteerWheel_Mode 0 "not pressed
" 1 "pressed"  ;
VAL_ 342 SteerWheel_Return_Home 0 "not pressed
" 1 "pressed"  ;
VAL_ 342 SteerWheel_Hang_Down 0 "not pressed
" 1 "pressed"  ;
VAL_ 342 AmphereLampMode 0 "无效
" 1 "打开普通呼吸模式
" 2 "打开车速呼吸模式
" 3 "打开人脸识别呼吸模式
" 4 "保留
" 5 "保留
" 6 "保留
" 7 "保留"  ;
VAL_ 342 AmphereLampSta_Drivingmode 0 "无效
" 1 "驾驶模式开
" 2 "驾驶模式关
" 3 "保留"  ;
VAL_ 342 AmphereLampSta_SW 0 "Invalid
" 1 "OFF
" 2 "ON
" 3 "Reserved"  ;
VAL_ 342 AmphereLampSta_Colour 0 "默认颜色
" 1 "红色
" 2 "橙色
" 3 "黄色
" 4 "绿色
" 5 "青色
" 6 "蓝色
" 7 "紫色"  ;
VAL_ 586 ACU_AirBagSysWrnLmpCmd 0 "Off
" 1 "On"  ;
VAL_ 586 ACU_Crashinfo 0 "no crash
" 1 "front crash
" 2 "left side crash
" 3 "right side crash
" 4 "rear crash
" 5 "reserved
" 6 "reserved
" 7 "invalid"  ;
VAL_ 352 ACC_DecToStop 0 "Not active
" 1 "Active"  ;
VAL_ 352 ACC_Set_Headway 0 "No gap set
" 1 "Distance stage 1
" 2 "Distance stage 2
" 3 "Distance stage 3
" 4 "Distance stage 4
" 5 "Reserved
" 6 "Reserved
" 7 "Invalid value"  ;
VAL_ 352 ADAS_TJAorHWATouchWarning 0 "Normal
" 1 "ShortLeave
" 2 "LongLeave
" 3 "Reserved"  ;
VAL_ 352 ADAS_TJA_HWAFuncStatus 0 "Inhibit
" 1 "Standby
" 2 "Active
" 3 "Failure
" 4 "Pause
" 5 "Abort
" 6 "Nextcycle
" 7 "Reserved
" 8 "Reserved
" 9 "Reserved
" 10 "Invalid"  ;
VAL_ 352 TJAHWA_Auto_Cancel 0 "No request
" 1 "Condition dissatisfy
" 2 "Function cancel"  ;
VAL_ 352 ALC_Auto_Cancel 0 "No request
" 1 "Condition dissatisfy
" 2 "Function cancel"  ;
VAL_ 354 AEB_ABA_Level 0 "Normal sensitivity
" 1 "Low sensitivity
" 2 "Middle sensitivity
" 3 "High sensivitity"  ;
VAL_ 354 AEB_ABA_Req 0 "No request
" 1 "Request"  ;
VAL_ 354 AEB_Prefill_Request 0 "No request
" 1 "Request"  ;
VAL_ 354 AEB_AWB_Req 0 "No request
" 1 "Request"  ;
VAL_ 354 AEB_State 0 "Unavailable state
" 1 "Off
" 2 "Standby
" 3 "Active (no intervention)
" 4 "Active"  ;
VAL_ 354 AEB_DecCtlReq 0 "No request
" 1 "Request"  ;
VAL_ 354 FCW_State 0 "Unavailable state
" 1 "Off
" 2 "Standby
" 3 "Active (no intervention)
" 4 "Active"  ;
VAL_ 354 ACC_MinBraking 0 "No requst
" 1 "Request"  ;
VAL_ 354 ADAS_Sensorstatus 0 "No error
" 1 "System Initialize摄像头初始化
" 2 "Sensor blocked摄像头被遮挡
" 3 "service requoired摄像头系统故障
" 4 "Reserved
" 5 "Reserved
" 6 "Reserved
" 7 "Reserved"  ;
VAL_ 354 HW_Warning_Level 0 "No warning
" 1 "Warning Level 1
" 2 "Warning Level 2
" 3 "Reserved"  ;
VAL_ 354 FCW_Warning_Level 0 "No warning
" 1 "Warning Level 1
" 2 "Warning Level 2
" 3 "Reserved"  ;
VAL_ 354 ACC_CIPV_Indicator 0 "No request
" 1 "Request"  ;
VAL_ 354 ACC_Auto_Cancel 0 "No request
" 1 "Condition dissatisfy
" 2 "Function cancel"  ;
VAL_ 354 ACC_Driver_Cancel 0 "No request
" 1 "Request"  ;
VAL_ 354 ACC_ModeReq 0 "OFF
" 1 "Passive
" 2 "StandBy
" 3 "Active Control
" 4 "Brake Only
" 5 "Override
" 6 "Stand Still
" 7 "Failure"  ;
VAL_ 354 AEB_AWB_Level 0 "No level
" 1 "Level 1
" 2 "Level 2
" 3 "Level 3"  ;
VAL_ 354 ACC_ShutDownMode 0 "Soft Off
" 1 "Fast Off
" 2 "immediate Off
" 3 "No Request"  ;
VAL_ 354 ACC_DriveOff 0 "Not active
" 1 "Active"  ;
VAL_ 354 ACC_BrkPreferred 0 "Not active
" 1 "Active"  ;
VAL_ 354 ACC_Go_Indicator 0 "No request
" 1 "Request"  ;
VAL_ 354 ACC_Takeover_Indicator 0 "No request
" 1 "Request"  ;
VAL_ 356 TSR_State 0 "Unavailable state
" 1 "Off
" 2 "Standby
" 3 "Active (no intervention)
" 4 "Active"  ;
VAL_ 356 DAS_TSR_Main_Switch 0 "off
" 1 "on"  ;
VAL_ 356 IHC_Mainbeam_Request 0 "On
" 1 "Off"  ;
VAL_ 356 IHC_State 0 "Unavailable state
" 1 "Off
" 2 "Standby
" 3 "Active (no intervention)
" 4 "Active"  ;
VAL_ 356 LDW_Line_Detect_Status 0 "Neither side lane mark detected
" 1 "Left side lane mark detected
" 2 "Right side lane mark detected
" 3 "Both side lane marks detected"  ;
VAL_ 356 LDW_Warning 0 "No warning
" 1 "Left Warning
" 2 "Right Warning
" 3 "Reserved"  ;
VAL_ 356 LDW_State 0 "Unavailable state
" 1 "Off
" 2 "Standby
" 3 "Active (no intervention)
" 4 "Active"  ;
VAL_ 356 TSR_Targetspeed_Request 0 "release warning识别到限速解除
" 255 "Invalid"  ;
VAL_ 356 LKA_Takeover_Request 0 "No Request
" 1 "Request"  ;
VAL_ 356 LKA_Torque_Request_Status 0 "no torque request
" 1 "torque request"  ;
VAL_ 356 LCK_State 0 "Unavailable state
" 1 "Off
" 2 "Standby
" 3 "Active (no intervene)
" 4 "Active (left intervene)
" 5 "Active (right intervene)
" 6 "Exit
" 7 "Reserved"  ;
VAL_ 356 LKA_State 0 "Unavailable state
" 1 "Off
" 2 "Standby
" 3 "Active (no intervene)
" 4 "Active (left intervene)
" 5 "Active (right intervene)
" 6 "Exit
" 7 "Reserved"  ;
VAL_ 356 LKA_Hands_Off_Warning 0 "No warning
" 1 "Warning"  ;
VAL_ 356 DAS_LDW_Main_Switch 0 "Off
" 1 "On"  ;
VAL_ 356 DAS_LDW_Sensitivity 0 "Reserved
" 1 "Level 1
" 2 "Level 2
" 3 "Level 3"  ;
VAL_ 356 DAS_FCW_Main_Switch 0 "Off
" 1 "On"  ;
VAL_ 356 DAS_FCW_Sensitivity 0 "Reserved
" 1 "Level 1
" 2 "Level 2
" 3 "Level 3"  ;
VAL_ 356 DAS_AEB_Main_Switch 0 "Off
" 1 "On"  ;
VAL_ 356 DAS_IHC_Main_Switch 0 "Off
" 1 "On"  ;
VAL_ 1281 ADAS_RelativeLogitudinalDistToObject1 2047 " Invalid"  ;
VAL_ 1281 ADAS_RelativeLateralDistToObject1 2047 " Invalid"  ;
VAL_ 1281 ADAS_Object1Type 0 " None" 1 " Car" 2 " Truck" 3 " Bicycle" 4 " Moto" 5 " PasserBy" 7 " Uncertainvehicle"  ;
VAL_ 1281 ADAS_RelativeLogitudinalDistToObject2 2047 " Invalid"  ;
VAL_ 1281 ADAS_RelativeLateralDistToObject2 2047 " Invalid"  ;
VAL_ 1281 ADAS_Object2Type 0 " None" 1 " Car" 2 " Truck" 3 " Bicycle" 4 " Moto" 5 " PasserBy" 7 " Uncertainvehicle"  ;
VAL_ 1281 ADAS_Object1_2_RollingCounter  ;
VAL_ 1281 ADAS_Object1_2_Checksum  ;
VAL_ 1282 ADAS_RelativeLogitudinalDistToObject3 2047 " Invalid"  ;
VAL_ 1282 ADAS_RelativeLateralDistToObject3 2047 " Invalid"  ;
VAL_ 1282 ADAS_Object3Type 0 " None" 1 " Car" 2 " Truck" 3 " Bicycle" 4 " Moto" 5 " PasserBy" 7 " Uncertainvehicle"  ;
VAL_ 1282 ADAS_RelativeLogitudinalDistToObject4 2047 " Invalid"  ;
VAL_ 1282 ADAS_RelativeLateralDistToObject4 2047 " Invalid"  ;
VAL_ 1282 ADAS_Object4Type 0 " None" 1 " Car" 2 " Truck" 3 " Bicycle" 4 " Moto" 5 " PasserBy" 7 " Uncertainvehicle"  ;
VAL_ 1282 ADAS_Object3_4_RollingCounter  ;
VAL_ 1282 ADAS_Object3_4_Checksum  ;
VAL_ 1283 ADAS_RelativeLogitudinalDistToObject5 2047 " Invalid"  ;
VAL_ 1283 ADAS_RelativeLateralDistToObject5 2047 " Invalid"  ;
VAL_ 1283 ADAS_Object5Type 0 " None" 1 " Car" 2 " Truck" 3 " Bicycle" 4 " Moto" 5 " PasserBy" 7 " Uncertainvehicle"  ;
VAL_ 1283 ADAS_RelativeLogitudinalDistToObject6 2047 " Invalid"  ;
VAL_ 1283 ADAS_RelativeLateralDistToObject6 2047 " Invalid"  ;
VAL_ 1283 ADAS_Object6Type 0 " None" 1 " Car" 2 " Truck" 3 " Bicycle" 4 " Moto" 5 " PasserBy" 7 " Uncertainvehicle"  ;
VAL_ 1283 ADAS_Object5_6_RollingCounter  ;
VAL_ 1283 ADAS_Object5_6_Checksum  ;
VAL_ 1288 ADAS_LeftLaneColor 0 " None" 1 " White Line" 2 " Yellow Line" 3 " Else Color" 4 " Reserved                                                            0x6" 7 " Invaild"  ;
VAL_ 1288 ADAS_LeftLaneType 0 " None" 1 " Dotted Line" 2 " Solid Line" 3 " Roadside" 4 " Reserved                                                                    0x5" 7 " Invaild"  ;
VAL_ 1288 ADAS_LeftLeftLaneType 0 " None" 1 " Dotted Line" 2 " Solid Line" 3 " Roadside" 4 " Reserved                                                                    0x5" 7 " Invaild"  ;
VAL_ 1288 ADAS_RightLaneColor 0 " None" 1 " White Line" 2 " Yellow Line" 3 " Else Color" 4 " Reserved                                                            0x6" 7 " Invaild"  ;
VAL_ 1288 ADAS_RightLaneType 0 " None" 1 " Dotted Line" 2 " Solid Line" 3 " Roadside" 4 " Reserved                                                                    0x5" 7 " Invaild"  ;
VAL_ 1288 ADAS_RightRightLaneType 0 " None" 1 " Dotted Line" 2 " Solid Line" 3 " Roadside" 4 " Reserved                                                                    0x5" 7 " Invaild"  ;
VAL_ 1288 ADAS_RightRightLaneColor 0 " None" 1 " White Line" 2 " Yellow Line" 3 " Else Color" 4 " Reserved                                                            0x6" 7 " Invaild"  ;
VAL_ 1288 ADAS_LeftLeftLaneColor 0 " None" 1 " White Line" 2 " Yellow Line" 3 " Else Color" 4 " Reserved                                                            0x6" 7 " Invaild"  ;
VAL_ 1288 ADAS_ALCStatusup 0 " Init" 1 " standby" 2 " Active_lane_chaning（right）" 3 " Active_lane_chaning（left）" 4 " Active_waiting" 5 " takeover request" 6 " Fault" 7 " Reserved"  ;
VAL_ 1288 ADAS_ALCAvailable 0 " Avalilable" 1 " Unavailable"  ;
VAL_ 384 APA_MMI_ConnectStatus 0 "none/提示用户APA_ECU等待连接
" 1 "disconnect/提示用户APA_ECU断开连接
" 2 "connected
" 15 "invalid/提示用户APA_ECU连接异常"  ;
VAL_ 384 APA_MMI_EcuStatus 0 "none/提示用户APA_ECU上电中
" 1 "power off/提示用户APA_ECU已下电
" 2 "power on
" 3 "reserved
" 4 "reserved
" 5 "reserved
" 6 "reserved
" 7 "reserved
" 8 "reserved
" 9 "reserved
" 10 "reserved
" 11 "reserved
" 12 "reserved
" 13 "reserved
" 14 "reserved
" 15 "invalid/提示用户APA_ECU状态异常"  ;
VAL_ 384 APA_MMI_VideoOutputStatus 0 "none/显示MMI画面
" 1 "off/显示MMI画面
" 2 "on/显示APA画面
" 3 "invalid/显示MMI画面"  ;
VAL_ 384 APA_MMI_3DViewModeStatus 0 "none
" 1 "2d
" 2 "3d
" 3 "speed3D
" 4 "Ctv_Front
" 5 "Ctv_Rear
" 6 "Rim_Front
" 7 "Rim_Rear
" 8 "reserved
" 9 "reserved
" 10 "reserved
" 11 "reserved
" 12 "reserved
" 13 "reserved
" 14 "reserved
" 15 "invalid"  ;
VAL_ 384 APA_MMI_AVM3DViewSwitch 0 "none
" 1 "2d_front
" 2 "2d_right
" 3 "2d_left
" 4 "2d_rear
" 5 "reserved
" 6 "reserved
" 7 "reserved
" 8 "reserved
" 9 "reserved
" 10 "reserved
" 11 "reserved
" 12 "reserved
" 13 "reserved
" 14 "reserved
" 15 "reserved
" 16 "reserved
" 17 "3d_front
" 18 "3d_right
" 19 "3d_left
" 20 "3d_rear
" 21 "3d_right_front
" 22 "3d_left_front
" 23 "3d_left_rear
" 24 "3d_right_rear
" 25 "reserved
" 26 "reserved
" 27 "reserved
" 28 "reserved
" 29 "reserved
" 30 "reserved
" 31 "reserved
" 32 "reserved
" 33 "reserved
" 34 "reserved
" 35 "reserved
" 36 "reserved
" 37 "reserved
" 38 "reserved
" 39 "reserved
" 40 "reserved
" 41 "reserved
" 42 "reserved
" 43 "reserved
" 44 "reserved
" 45 "reserved
" 46 "reserved
" 47 "reserved
" 48 "reserved
" 49 "reserved
" 50 "reserved
" 51 "reserved
" 52 "reserved
" 53 "reserved
" 54 "reserved
" 55 "reserved
" 56 "reserved
" 57 "reserved
" 58 "reserved
" 59 "reserved
" 60 "reserved
" 61 "reserved
" 62 "reserved
" 63 "reserved
" 64 "reserved
" 65 "reserved
" 66 "reserved
" 67 "reserved
" 68 "reserved
" 69 "reserved
" 70 "reserved
" 71 "reserved
" 72 "reserved
" 73 "reserved
" 74 "reserved
" 75 "reserved
" 76 "reserved
" 77 "reserved
" 78 "reserved
" 79 "reserved
" 80 "reserved
" 81 "reserved
" 82 "reserved
" 83 "reserved
" 84 "reserved
" 85 "reserved
" 86 "reserved
" 87 "reserved
" 88 "reserved
" 89 "reserved
" 90 "reserved
" 91 "reserved
" 92 "reserved
" 93 "reserved
" 94 "reserved
" 95 "reserved
" 96 "reserved
" 97 "reserved
" 98 "reserved
" 99 "reserved
" 100 "reserved
" 101 "reserved
" 102 "reserved
" 103 "reserved
" 104 "reserved
" 105 "reserved
" 106 "reserved
" 107 "reserved
" 108 "reserved
" 109 "reserved
" 110 "reserved
" 111 "reserved
" 112 "reserved
" 113 "reserved
" 114 "reserved
" 115 "reserved
" 116 "reserved
" 117 "reserved
" 118 "reserved
" 119 "reserved
" 120 "reserved
" 121 "reserved
" 122 "reserved
" 123 "reserved
" 124 "reserved
" 125 "reserved
" 126 "reserved
" 127 "reserved
" 128 "reserved
" 129 "reserved
" 130 "reserved
" 131 "reserved
" 132 "reserved
" 133 "reserved
" 134 "reserved
" 135 "reserved
" 136 "reserved
" 137 "reserved
" 138 "reserved
" 139 "reserved
" 140 "reserved
" 141 "reserved
" 142 "reserved
" 143 "reserved
" 144 "reserved
" 145 "reserved
" 146 "reserved
" 147 "reserved
" 148 "reserved
" 149 "reserved
" 150 "reserved
" 151 "reserved
" 152 "reserved
" 153 "reserved
" 154 "reserved
" 155 "reserved
" 156 "reserved
" 157 "reserved
" 158 "reserved
" 159 "reserved
" 160 "reserved
" 161 "reserved
" 162 "reserved
" 163 "reserved
" 164 "reserved
" 165 "reserved
" 166 "reserved
" 167 "reserved
" 168 "reserved
" 169 "reserved
" 170 "reserved
" 171 "reserved
" 172 "reserved
" 173 "reserved
" 174 "reserved
" 175 "reserved
" 176 "reserved
" 177 "reserved
" 178 "reserved
" 179 "reserved
" 180 "reserved
" 181 "reserved
" 182 "reserved
" 183 "reserved
" 184 "reserved
" 185 "reserved
" 186 "reserved
" 187 "reserved
" 188 "reserved
" 189 "reserved
" 190 "reserved
" 191 "reserved
" 192 "reserved
" 193 "reserved
" 194 "reserved
" 195 "reserved
" 196 "reserved
" 197 "reserved
" 198 "reserved
" 199 "reserved
" 200 "reserved
" 201 "reserved
" 202 "reserved
" 203 "reserved
" 204 "reserved
" 205 "reserved
" 206 "reserved
" 207 "reserved
" 208 "reserved
" 209 "reserved
" 210 "reserved
" 211 "reserved
" 212 "reserved
" 213 "reserved
" 214 "reserved
" 215 "reserved
" 216 "reserved
" 217 "reserved
" 218 "reserved
" 219 "reserved
" 220 "reserved
" 221 "reserved
" 222 "reserved
" 223 "reserved
" 224 "reserved
" 225 "reserved
" 226 "reserved
" 227 "reserved
" 228 "reserved
" 229 "reserved
" 230 "reserved
" 231 "reserved
" 232 "reserved
" 233 "reserved
" 234 "reserved
" 235 "reserved
" 236 "reserved
" 237 "reserved
" 238 "reserved
" 239 "reserved
" 240 "reserved
" 241 "reserved
" 242 "reserved
" 243 "reserved
" 244 "reserved
" 245 "reserved
" 246 "reserved
" 247 "reserved
" 248 "reserved
" 249 "reserved
" 250 "reserved
" 251 "reserved
" 252 "reserved
" 253 "reserved
" 254 "reserved
" 255 "reserved"  ;
VAL_ 384 APA_Status 0 "Off
" 1 "Standby
" 2 "Seaching
" 3 "Guidance Active
" 4 "Completed Sucessfully
" 5 "Faliure
" 6 "Suspend
" 7 "Invalid 无效"  ;
VAL_ 384 PAS_APA_Mode 0 "车型请求模式
" 1 "自检模式
" 2 "正常工作模式
" 3 "停止
" 4 "通讯超时故障
" 5 "Reserved
" 6 "Reserved
" 7 "Reserved"  ;
VAL_ 384 PSA_APA_SensorStsLR_RL 0 "Normal
" 1 "Fault"  ;
VAL_ 384 PSA_APA_SensorStsLR_RR 0 "Normal
" 1 "Fault"  ;
VAL_ 384 PSA_APA_SensorStsSR_RL 0 "Normal
" 1 "Fault"  ;
VAL_ 384 PSA_APA_SensorStsSR_RML 0 "Normal
" 1 "Fault"  ;
VAL_ 384 PAS_APA_SensorStsSR_RMR 0 "Normal
" 1 "Fault"  ;
VAL_ 384 PAS_APA_SensorStsSR_RR 0 "Normal
" 1 "Fault"  ;
VAL_ 384 PSA_APA_SensorStsLR_FL 0 "Normal
" 1 "Fault"  ;
VAL_ 384 PSA_APA_SensorStsLR_FR 0 "Normal
" 1 "Fault"  ;
VAL_ 384 PSA_APA_SensorStsSR_FL 0 "Normal
" 1 "Fault"  ;
VAL_ 384 PSA_APA_SensorStsSR_FML 0 "Normal
" 1 "Fault"  ;
VAL_ 384 PAS_APA_SensorStsSR_FMR 0 "Normal
" 1 "Fault"  ;
VAL_ 384 PAS_APA_SensorStsSR_FR 0 "Normal
" 1 "Fault"  ;
VAL_ 386 APA_BSDLeftWaringSeverity 0 "level0
" 1 "level1
" 2 "level2
" 3 "level3
" 127 "invalid"  ;
VAL_ 386 APA_BSDLeftWaringValid 0 "invalid
" 1 "valid"  ;
VAL_ 386 APA_BSDRightWaringSeverity 0 "level0
" 1 "level1
" 2 "level2
" 3 "level3
" 127 "invalid"  ;
VAL_ 386 APA_BSDRightWaringValid 0 "invalid
" 1 "valid"  ;
VAL_ 386 APA_BSDStatus 0 "BSD not run
" 1 "BSD run"  ;
VAL_ 386 APA_BSDStatusValid 0 "invalid
" 1 "valid"  ;
VAL_ 784 APA_AVM_MCU_Version 0 "none
" 16777215 "invalid"  ;
VAL_ 784 APA_AVM_BSP_Version 0 "none
" 16777215 "invalid"  ;
VAL_ 786 APA_AVM_ZADAS_Version 0 "none
" 16777215 "invalid"  ;
VAL_ 786 APA_Avm3d_licenseStatus 0 "none
" 1 "no license
" 2 "has license
" 3 "invalid"  ;
VAL_ 786 APA_BSD_licenseStatus 0 "none
" 1 "no license
" 2 "has license
" 3 "invalid"  ;
VAL_ 514 BMS_Err_DischrgAnodeRelay 0 "Invalid
" 1 "Normal正常
" 2 "Cake烧结
" 3 "Failure错误"  ;
VAL_ 514 BMS_DischargeAnodeRelay_status 0 "Invalid
" 1 "Open
" 2 "Connect
" 3 "Reserved"  ;
VAL_ 514 BMS_Boot_Detection 0 "False；
" 1 "Pull"  ;
VAL_ 514 BMS_A 0 "False；
" 1 "Pull"  ;
VAL_ 514 BMS_Relay_HEAT 0 "OFF断开；
" 1 "ON吸合；
" 2 "adhesion粘连；
" 3 "reserved保留"  ;
VAL_ 514 BMS_Err_PrechargeAnodeRelay 0 "Invalid
" 1 "Normal正常
" 2 "Cake烧结
" 3 "Failure错误"  ;
VAL_ 514 BMS_Precharge_anode_Relay_status 0 "Invalid
" 1 "Open
" 2 "Connect
" 3 "Reserved"  ;
VAL_ 514 BMS_ChrgHeatColEnable 0 "无效
" 1 "交流充电允许
" 2 "交流加热/冷却允许
" 3 "直流充电允许；
" 4 "直流加热/冷却允许；
" 5 "Reserved
" 6 "Reserved
" 7 "Reserved"  ;
VAL_ 514 BMS_Sys_ChgorDisChrgSts 0 "Invalid
" 1 "Discharging
" 2 "Charging（快充中）
" 3 "Charging（慢充中）"  ;
VAL_ 514 BMS_FastChrgSts 0 "Invalid
" 1 "Not charged未充电
" 2 "充电就绪
" 3 "充电中
" 4 "充电完成
" 5 "充电结束
" 6 "故障结束
" 7 "Reserved保留"  ;
VAL_ 514 BMS_SlowChrgSts 0 "Invalid
" 1 "Not charged未充电
" 2 "充电就绪
" 3 "充电中
" 4 "充电完成
" 5 "充电结束
" 6 "故障结束
" 7 "Reserved保留"  ;
VAL_ 514 BMS_ChrgCouplesSt 0 "Disconnected
" 1 "Quick_charge_Connect
" 2 "Reserved
" 3 "Reserved"  ;
VAL_ 514 BMS_req_ConnectChargeRelay 0 "no request
" 1 "open
" 2 "Connect
" 3 "Reserved"  ;
VAL_ 514 BMS_request_subscribe_allow 0 "prohibit
" 1 "allow"  ;
VAL_ 514 BMS_CC2 0 "disconnected未连接；
" 1 "half-connected连接；"  ;
VAL_ 514 BMS_PauseContinueChrgStus 0 "invalid
" 1 "暂停充电
" 2 "继续充电
" 3 "reserved"  ;
VAL_ 518 BMS_ThermalManageReq 0 "no request
" 1 "heating
" 2 "cooling
" 3 "pump cycle"  ;
VAL_ 524 BMS_Powertrain_System_fault 0 "fault-free无故障；
" 1 "First-level faults一级故障；
" 2 "Second-degree faults二级故障；
" 3 "Level three faults三级故障"  ;
VAL_ 524 BMS_cell_Voltage_low 0 "fault-free无故障；
" 1 "First-level faults一级故障；
" 2 "Second-degree faults二级故障；
" 3 "Level three faults三级故障"  ;
VAL_ 524 BMS_cell_Voltage_High 0 "fault-free无故障；
" 1 "First-level faults一级故障；
" 2 "Second-degree faults二级故障；
" 3 "Level three faults三级故障"  ;
VAL_ 524 BMS_Battery_LowTemp_warning 0 "fault-free无故障；
" 1 "First-level faults一级故障；
" 2 "Second-degree faults二级故障；
" 3 "Level three faults三级故障"  ;
VAL_ 524 BMS_Battery_HighTemp_warning 0 "fault-free无故障；
" 1 "First-level faults一级故障；
" 2 "Second-degree faults二级故障；
" 3 "Level three faults三级故障"  ;
VAL_ 524 BMS_SOCHigh_Warning 0 "fault-free无故障；
" 1 "First-level faults一级故障；
" 2 "Second-degree faults二级故障；
" 3 "Level three faults三级故障"  ;
VAL_ 524 BMS_SOCLow_Warning 0 "fault-free无故障；
" 1 "First-level faults一级故障；
" 2 "Second-degree faults二级故障；
" 3 "Level three faults三级故障"  ;
VAL_ 524 BMS_Battery_SumVoltage_High 0 "fault-free无故障；
" 1 "First-level faults一级故障；
" 2 "Second-degree faults二级故障；
" 3 "Level three faults三级故障"  ;
VAL_ 524 BMS_Battery_SumVoltage_Low 0 "fault-free无故障；
" 1 "First-level faults一级故障；
" 2 "Second-degree faults二级故障；
" 3 "Level three faults三级故障"  ;
VAL_ 524 BMS_HVBatCellDiffFalt 0 "fault-free无故障；
" 1 "First-level faults一级故障；
" 2 "Second-degree faults二级故障；
" 3 "Level three faults三级故障"  ;
VAL_ 524 BMS_SOCJump_Warning 0 "fault-free无故障；
" 1 "First-level faults一级故障；
" 2 "Second-degree faults二级故障；
" 3 "Level three faults三级故障"  ;
VAL_ 524 BMS_BatNotMatchFlt 0 "fault-free无故障；
" 1 "fault 故障；
" 2 "Reserved
" 3 "Reserved"  ;
VAL_ 524 BMS_Err_ISO_LOW 0 "fault-free无故障；
" 1 "First-level faults一级故障；
" 2 "Second-degree faults二级故障；
" 3 "Level three faults三级故障"  ;
VAL_ 524 BMS_Err_ChgCurrent_High 0 "fault-free无故障；
" 1 "First-level faults一级故障；
" 2 "Second-degree faults二级故障；
" 3 "Level three faults三级故障"  ;
VAL_ 524 BMS_Err_DchCurrent_High 0 "fault-free无故障；
" 1 "First-level faults一级故障；
" 2 "Second-degree faults二级故障；
" 3 "Level three faults三级故障"  ;
VAL_ 524 BMS_Err_DtT_High 0 "fault-free无故障；
" 1 "First-level faults一级故障；
" 2 "Second-degree faults二级故障；
" 3 "Level three faults三级故障"  ;
VAL_ 524 ThermalManage_System_fault 0 "无故障；
" 1 "一级故障；
" 2 "二级故障；
" 3 "三级故障"  ;
VAL_ 524 BMS_Err_comunicacion 0 "fault-free无故障；
" 1 "Internal communication failure内部通讯故障；
" 2 "External communication failure外部通讯故障；
" 3 "内外部通讯故障"  ;
VAL_ 524 BMS_Err_InterLock 0 "fault-free无故障；
" 1 "Interlock faults互锁故障"  ;
VAL_ 524 BMS_Circuit_Protection 0 "normal正常；
" 1 "open短路保护开启"  ;
VAL_ 524 BMS_FeedFault 0 "fault-free无故障；
" 1 "First-level faults一级故障；
" 2 "Second-degree faults二级故障；
" 3 "Level three faults三级故障"  ;
VAL_ 340 RCTA_warm_status_left 0 "No Alarm
" 1 "warning
" 2 "Serious Warnning
" 3 "Invalid"  ;
VAL_ 340 BSDLCA_warm_status_left 0 "No Alarm
" 1 "warning
" 2 "Serious Warnning
" 3 "Invalid"  ;
VAL_ 340 BSD_ConnectionFault_left 0 "正常；
" 1 "异常；"  ;
VAL_ 340 BSD_RFICFault_left 0 "正常；
" 1 "异常；"  ;
VAL_ 340 BSD_OverTempFault_left 0 "正常；
" 1 "异常；"  ;
VAL_ 340 BSD_StoreFault_left 0 "正常；
" 1 "异常；"  ;
VAL_ 340 BSDDOW_warm_status_left 0 "No Alarm
" 1 "warning
" 2 "Serious Warnning
" 3 "Invalid"  ;
VAL_ 340 BSD_EnableStatus 0 "Invalid
" 1 "BSD系统待机
" 2 "BSD系统工作
" 3 "BSD系统异常"  ;
VAL_ 344 RCTA_warm_status_right 0 "No Alarm
" 1 "warning
" 2 "Serious Warnning
" 3 "Invalid"  ;
VAL_ 344 BSDLCA_warm_status_right 0 "No Alarm
" 1 "warning
" 2 "Serious Warnning
" 3 "Invalid"  ;
VAL_ 344 BSD_ConnectionFault_right 0 "正常；
" 1 "异常；"  ;
VAL_ 344 BSD_RFICFault_right 0 "正常；
" 1 "异常；"  ;
VAL_ 344 BSD_OverTempFault_right 0 "正常；
" 1 "异常；"  ;
VAL_ 344 BSD_StoreFault_right 0 "正常；
" 1 "异常；"  ;
VAL_ 344 BSDDOW_warm_status_right 0 "No Alarm
" 1 "warning
" 2 "Serious Warnning
" 3 "Invalid"  ;
VAL_ 332 WCBS_FaultStus 0 "No fault
" 1 "故障等级1
" 2 "故障等级2
" 3 "Reseved
" 4 "Reseved
" 5 "Reseved
" 6 "Reseved
" 7 "Reseved"  ;
VAL_ 332 WCBS_EPB_SystemStatus 0 "Released
" 1 "Applied
" 2 "Releasing
" 3 "Fault_Unknown state
" 4 "Applying
" 5 "Disengaged
" 6 "Reserved
" 7 "Reserved"  ;
VAL_ 332 WCBS_EPB_SwitchSstatus 0 "Neutral
" 1 "Release
" 2 "Apply
" 3 "invalid"  ;
VAL_ 332 WCBS_CC_Cancel_Request 0 "No request
" 1 "Request"  ;
VAL_ 332 WCBS_TMM_Open_Request 0 "No request
" 1 "Request"  ;
VAL_ 332 WCBS_EPB_WarnLampStatus 0 "Off
" 1 "On
" 2 "Blinking
" 3 "Reserved"  ;
VAL_ 332 WCBS_EPB_ParkLampStatus 0 "Off
" 1 "On
" 2 "Blinking
" 3 "Reserved"  ;
VAL_ 332 WCBS_Brake_Lights_Request 0 "No request
" 1 "Request"  ;
VAL_ 332 WCBS_EPB_DynamicApplyStatus 0 "Not Active
" 1 "EDC request active
" 2 "RWU active
" 3 "Degrade Apply
" 4 "reserved
" 5 "reserved
" 6 "reserved
" 7 "reserved"  ;
VAL_ 332 WCBS_EPB_Disp_ReleaseWithoutBrake 0 "Off
" 1 "Push brake pedal"  ;
VAL_ 332 WCBS_EPB_Disp_DAAWithoutDoorOrBelt 0 "Off
" 1 "Fasten the belt or Close the door"  ;
VAL_ 274 EPS_SteeringWheelAngVD 0 "Invalid
" 1 "Valid"  ;
VAL_ 274 EPS_SASFailureSts 0 "Sensor information invalid an internal sensor fault occurred传感器信息无效发生内部传感器故障
" 1 "Sensor information valid传感器信息有效"  ;
VAL_ 274 EPS_TorsionBarTorqueValid 0 "Invalid
" 1 "Valid"  ;
VAL_ 274 EPS_TorsionBarTorqueDir 0 "Positive
" 1 "Negative"  ;
VAL_ 274 EPS_Fault 0 "off 故障灯灭
" 1 "on 故障灯亮
" 2 "flashing 故障灯闪烁（没标中位）"  ;
VAL_ 274 EPS_State_Mode 0 "Invalid
" 1 "标准模式
" 2 "运动模式
" 3 "Reserved
" 4 "Reserved
" 5 "Reserved
" 6 "Reserved
" 7 "Reserved"  ;
VAL_ 274 EPS_Modesetting_Available 0 "Unavailable
" 1 "Available"  ;
VAL_ 274 EPS_SteerWheelRotSpdVD 0 "Invalid
" 1 "Valid"  ;
VAL_ 144 WCBS_ESC_TCSActive 0 "Not Active
" 1 "Active"  ;
VAL_ 144 WCBS_ESC_HHC_Failure 0 "no failure
" 1 "failure"  ;
VAL_ 144 WCBS_ESC_HHCActive 0 "Not Active
" 1 "Active"  ;
VAL_ 144 WCBS_ESC_EBDFailed 0 "no failure
" 1 "failure"  ;
VAL_ 144 WCBS_ESC_EBDActive 0 "Not Active
" 1 "Active"  ;
VAL_ 144 WCBS_ESC_ABSFailed 0 "no failure
" 1 "failure"  ;
VAL_ 144 WCBS_ESC_ABSActive 0 "Not Active
" 1 "Active"  ;
VAL_ 144 WCBS_ESC_AVH_Status 0 "Off
" 1 "Standby
" 2 "Active
" 3 "Error"  ;
VAL_ 144 WCBS_ESC_CST_Active 0 "Not active
" 1 "Active"  ;
VAL_ 144 WCBS_ESC_Sw 0 "ESC switch on
" 1 "ESC switch off"  ;
VAL_ 144 WCBS_ESC_HBAActive 0 "Not Active
" 1 "Active"  ;
VAL_ 144 WCBS_ESC_VDCFailure 0 "no failure
" 1 "failure"  ;
VAL_ 144 WCBS_ESC_VDCActive 0 "Not Active
" 1 "Active"  ;
VAL_ 144 WCBS_ESC_TCSFailure 0 "no failure
" 1 "failure"  ;
VAL_ 144 WCBS_ESC_NoBrakeForce 0 "Not active
" 1 "Active"  ;
VAL_ 144 WCBS_ESC_VehicleStandStill 0 "Not active
" 1 "Active"  ;
VAL_ 144 WCBS_ESC_ABP_Available 0 "Not Avaliable
" 1 "Avaliable"  ;
VAL_ 144 WCBS_ESC_APB_Active 0 "Not active
" 1 "Active"  ;
VAL_ 144 WCBS_ESC_AEB_Available 0 "Not Avaliable
" 1 "Avaliable"  ;
VAL_ 144 WCBS_ESC_AEB_Active 0 "Not active
" 1 "Active"  ;
VAL_ 144 WCBS_ESC_AWB_Available 0 "Not Avaliable
" 1 "Avaliable"  ;
VAL_ 144 WCBS_ESC_AWB_Active 0 "Not active
" 1 "Active"  ;
VAL_ 144 WCBS_ESC_Brake_Light_Control 0 "OFF
" 1 "ON"  ;
VAL_ 144 WCBS_ESC_BrkPrsVd 0 "Not Active
" 1 "Active"  ;
VAL_ 144 WCBS_ESC_AVH_Warning1 0 "Inactive
" 1 "Active"  ;
VAL_ 144 WCBS_ESC_AVH_Warning2 0 "Inactive
" 1 "Active"  ;
VAL_ 144 WCBS_ESC_AVH_Warning3 0 "Inactive
" 1 "Active"  ;
VAL_ 144 WCBS_ESC_HazLightReq 0 "No request
" 1 "Request"  ;
VAL_ 144 WCBS_ESC_HDC_CtlSts 0 "OFF
" 1 "On active braking
" 2 "On not active braking"  ;
VAL_ 144 WCBS_ESC_HDC_Available 0 "Not Avaliable
" 1 "Avaliable"  ;
VAL_ 144 WCBS_ESC_ABA_Available 0 "Not Avaliable
" 1 "Avaliable"  ;
VAL_ 144 WCBS_ESC_ABA_Active 0 "Not active
" 1 "Active"  ;
VAL_ 146 WCBS_ESC_WhlSpdFRVd 0 "Not valid
" 1 "Valid"  ;
VAL_ 146 WCBS_ESC_WhlSpdFLVd 0 "Not valid
" 1 "Valid"  ;
VAL_ 146 WCBS_ESC_VehSpdVd 0 "Not valid
" 1 "Valid"  ;
VAL_ 594 MCU_F_ResolverFault 0 "No_Failure
" 1 "Failure"  ;
VAL_ 594 MCU_F_Err_IGBT 0 "No_Failure
" 1 "Failure"  ;
VAL_ 594 MCU_F_CurrentOverload 0 "fault-free无故障；
" 1 "First-level faults一级故障；
" 2 "Second-degree faults二级故障；
" 3 "reserved保留"  ;
VAL_ 594 MCU_F_Controllertemp_Status 0 "fault-free无故障；
" 1 "First-level faults一级故障；
" 2 "Second-degree faults二级故障；
" 3 "reserved保留"  ;
VAL_ 594 MCU_F_stDischg 0 "off未泄放
" 1 "discharging主动泄放中
" 2 "finished泄放完成
" 3 "fault泄放故障"  ;
VAL_ 594 MCU_F_SpeedOtLoopFalult 0 "No_Failure
" 1 "Failure"  ;
VAL_ 594 MCU_F_MdTepErr 0 "No_Failure
" 1 "Failure"  ;
VAL_ 594 MCU_F_ControllerOverVolt_Status 0 "fault-free无故障；
" 1 "First-level faults一级故障；
" 2 "Second-degree faults二级故障；
" 3 "reserved保留"  ;
VAL_ 594 MCU_F_MotorTemp_Fault 0 "fault-free无故障；
" 1 "First-level faults一级故障；
" 2 "Second-degree faults二级故障；
" 3 "reserved保留"  ;
VAL_ 594 MCU_F_MotorOverSpd 0 "No_Failure
" 1 "Failure"  ;
VAL_ 594 MCU_F_VCUCommErr 0 "No_Failure
" 1 "Failure"  ;
VAL_ 594 MCU_F_ControllerLowUnderVolt_Status 0 "No_Failure
" 1 "Failure"  ;
VAL_ 594 MCU_F_ControllerUnderVolt_Status 0 "fault-free无故障；
" 1 "First-level faults一级故障；
" 2 "Second-degree faults二级故障；
" 3 "reserved保留"  ;
VAL_ 594 MCU_F_ControllerFault 0 "fault-free无故障；
" 1 "First-level faults一级故障（报警，无上下电要求 Alarm，no power up and down req）；
" 2 "Second-degree faults二级故障（降功率，无上下电要求 reduce power，no power up and down req）；
" 3 "Third-degree faults三级故障
" 4 "Fourth-degree faults四级故障(下高压，不允许上高压，若MCU高压在充电回路，不允许充电 down HV,fobit up HV,if MCU HV is charging,forbit charge)；
" 5 "Reserved
" 6 "Reserved
" 7 "Reserved"  ;
VAL_ 594 MCU_F_unload_status 0 "Invalid
" 1 "未卸载
" 2 "卸载中
" 3 "卸载完成"  ;
VAL_ 594 FMCU_HV_Interlock_Falult 0 "Invalid
" 1 "No_Failure无故障
" 2 "Failure故障
" 3 "Reserved预留"  ;
VAL_ 594 FMCU_Uncap_Falult 0 "Invalid
" 1 "No_Failure无故障
" 2 "Failure故障
" 3 "Reserved预留"  ;
VAL_ 594 MCU_F_MotTepErr 0 "No_Failure
" 1 "Failure"  ;
VAL_ 130 MCU_F_stMode 0 "Initialization 初始化模式
" 1 "Precharge 预充模式
" 2 "Standby 待机模式
" 3 "RUN 扭矩或转速模式
" 4 "Failure 故障模式
" 5 "Discharge 主动放电模式
" 6 "Afterrun 下电模式
" 7 "Reserved
" 8 "Reserved
" 9 "Reserved
" 10 "Reserved
" 11 "Reserved
" 12 "Reserved
" 13 "Reserved
" 14 "Reserved
" 15 "Reserved"  ;
VAL_ 130 MCU_F_TrqCurrValid 0 "Normal
" 1 "Failure"  ;
VAL_ 130 MCU_F_NCurrValid 0 "Normal
" 1 "Failure"  ;
VAL_ 608 MCU_R_ResolverFault 0 "No_Failure
" 1 "Failure"  ;
VAL_ 608 MCU_R_Err_IGBT 0 "No_Failure
" 1 "Failure"  ;
VAL_ 608 MCU_R_CurrentOverload 0 "fault-free无故障；
" 1 "First-level faults一级故障；
" 2 "Second-degree faults二级故障；
" 3 "reserved保留"  ;
VAL_ 608 MCU_R_Controllertemp_Status 0 "fault-free无故障；
" 1 "First-level faults一级故障；
" 2 "Second-degree faults二级故障；
" 3 "reserved保留"  ;
VAL_ 608 MCU_R_stDischg 0 "off未泄放
" 1 "discharging主动泄放中
" 2 "finished泄放完成
" 3 "fault泄放故障"  ;
VAL_ 608 MCU_R_SpeedOtLoopFalult 0 "No_Failure
" 1 "Failure"  ;
VAL_ 608 MCU_R_MdTepErr 0 "No_Failure
" 1 "Failure"  ;
VAL_ 608 MCU_R_ControllerOverVolt_Status 0 "fault-free无故障；
" 1 "First-level faults一级故障；
" 2 "Second-degree faults二级故障；
" 3 "reserved保留"  ;
VAL_ 608 MCU_R_MotorTemp_Fault 0 "fault-free无故障；
" 1 "First-level faults一级故障；
" 2 "Second-degree faults二级故障；
" 3 "reserved保留"  ;
VAL_ 608 MCU_R_MotorOverSpd 0 "No_Failure
" 1 "Failure"  ;
VAL_ 608 MCU_R_VCUCommErr 0 "No_Failure
" 1 "Failure"  ;
VAL_ 608 MCU_R_ControllerLowUnderVolt_Status 0 "No_Failure
" 1 "Failure"  ;
VAL_ 608 MCU_R_ControllerUnderVolt_Status 0 "fault-free无故障；
" 1 "First-level faults一级故障；
" 2 "Second-degree faults二级故障；
" 3 "reserved保留"  ;
VAL_ 608 MCU_R_ControllerFault 0 "fault-free无故障；
" 1 "First-level faults一级故障（报警，无上下电要求 Alarm，no power up and down req）；
" 2 "Second-degree faults二级故障（降功率，无上下电要求 reduce power，no power up and down req）；
" 3 "Third-degree faults三级故障
" 4 "Fourth-degree faults四级故障(下高压，不允许上高压，若MCU高压在充电回路，不允许充电 down HV,fobit up HV,if MCU HV is charging,forbit charge)；
" 5 "Reserved
" 6 "Reserved
" 7 "Reserved"  ;
VAL_ 608 MCU_R_unload_status 0 "Invalid
" 1 "未卸载
" 2 "卸载中
" 3 "卸载完成"  ;
VAL_ 608 RMCU_HV_Interlock_Falult 0 "Invalid
" 1 "No_Failure无故障
" 2 "Failure故障
" 3 "Reserved预留"  ;
VAL_ 608 RMCU_Uncap_Falult 0 "Invalid
" 1 "No_Failure无故障
" 2 "Failure故障
" 3 "Reserved预留"  ;
VAL_ 608 MCU_R_MotTepErr 0 "No_Failure
" 1 "Failure"  ;
VAL_ 178 MCU_R_stMode 0 "Initialization 初始化模式
" 1 "Precharge 预充模式
" 2 "Standby 待机模式
" 3 "RUN 扭矩或转速模式
" 4 "Failure 故障模式
" 5 "Discharge 主动放电模式
" 6 "Afterrun 下电模式
" 7 "Reserved
" 8 "Reserved
" 9 "Reserved
" 10 "Reserved
" 11 "Reserved
" 12 "Reserved
" 13 "Reserved
" 14 "Reserved
" 15 "Reserved"  ;
VAL_ 178 MCU_R_TrqCurrValid 0 "Normal
" 1 "Failure"  ;
VAL_ 178 MCU_R_NCurrValid 0 "Normal
" 1 "Failure"  ;
VAL_ 772 OBC_out_Cur_over_prot 0 "False正常；
" 1 "True异常；"  ;
VAL_ 772 OBC_out_vol_Less_prot 0 "False正常；
" 1 "True异常；"  ;
VAL_ 772 OBC_out_vol_over_prot 0 "False正常；
" 1 "True异常；"  ;
VAL_ 772 OBC_In_Cur_over_prot 0 "False正常；
" 1 "True异常；"  ;
VAL_ 772 OBC_ChargerInputVoltageLessFault 0 "False正常；
" 1 "True异常；"  ;
VAL_ 772 OBC_ChargerInputVoltageOverFault 0 "False正常；
" 1 "True异常；"  ;
VAL_ 772 ChargeInterfaceOverTemp 0 "温度正常；
" 1 "过温；"  ;
VAL_ 772 OBC_ChargerOTP 0 "No failure无故障；
" 1 "温度过高一级故障；
" 2 "温度过高二级故障；
" 3 "温度过高三级故障；"  ;
VAL_ 772 OBC_ChargerCoolingRequest 0 "不需冷却；
" 1 "请求冷却；"  ;
VAL_ 772 OBC_ChargerHardwareFault 0 "True正常；
" 1 "False异常；"  ;
VAL_ 772 OBC_Charger_CAN_Fault 0 "No failure无故障；
" 1 "failure故障；"  ;
VAL_ 772 OBC_Charger_Fail_State 0 "No failure无故障；
" 1 "failure故障；"  ;
VAL_ 772 OBC_Charger_NoBatt 0 "未连接；
" 1 "连接；
" 2 "电池包电压过低；"  ;
VAL_ 772 OBC_CP_Rsv 0 "False；
" 1 "Connected"  ;
VAL_ 772 OBC_CC_Resistance 0 "未连接；
" 1 "半连接；
" 2 "充电电缆数量为10A；
" 3 "充电电缆数量为16A；
" 4 "充电电缆数量为32A；
" 5 "充电电缆数量为63A；
" 6 "Reserved；
" 7 "Reserved；"  ;
VAL_ 772 OBC_ChargerStatus 0 "Init（初始化）
" 1 "Standby（待机）
" 2 "Working（工作）
" 3 "ChargerOver（类似于关机，过一段时间会休眠）
" 4 "Sleep（休眠）
" 5 "Recovery Fault（可恢复故障）
" 6 "DisRecovery Fault（不可恢复故障，输出过欠压不可恢复，其余均可恢复）
" 7 "Reserved"  ;
VAL_ 772 KL30_UnderVolt 0 "正常；
" 1 "过压；
" 2 "欠压；
" 3 "Reserved"  ;
VAL_ 772 ElectronicLockSts 0 "解锁状态；
" 1 "闭锁状态；"  ;
VAL_ 772 ElectronicLockFault 0 "无故障；
" 1 "解锁故障；
" 2 "闭锁故障；
" 3 "Reserved"  ;
VAL_ 772 OBC_Charger_Instructions 0 "未充电；
" 1 "充电中（OBC输出电流＞0A）；"  ;
VAL_ 772 OBC_Charger_Request 0 "不请求充电；
" 1 "请求充电；"  ;
VAL_ 776 DCDC_Status 0 "normal正常输出
" 1 "sleep休眠
" 2 "standby待机"  ;
VAL_ 776 DCDC_IN_vol_over_prot 0 "normal
" 1 "overvoltage"  ;
VAL_ 776 DCDC_IN_vol_Less_prot 0 "normal
" 1 "undervoltage"  ;
VAL_ 776 DCDC_short_err 0 "normal
" 1 "short"  ;
VAL_ 776 DCDC_Out_Curr_Over_prot 0 "normal
" 1 "Overcurr"  ;
VAL_ 776 DCDC_out_vol_over_prot 0 "normal
" 1 "overvoltage"  ;
VAL_ 776 DCDC_out_vol_Less_prot 0 "normal
" 1 "undervoltage"  ;
VAL_ 776 DCDC_out_VolSt 0 "normal
" 1 "overvoltage
" 2 "undervoltage"  ;
VAL_ 776 DCDC_Fault 0 "No failure无故障；
" 1 "failure故障；
" 2 "reserved"  ;
VAL_ 776 DCDC_OverTemp_Fault 0 "No failure无故障；
" 1 "温度过高一级故障；
" 2 "温度过高二级故障；
" 3 "温度过高三级故障；"  ;
VAL_ 776 DCDC_WorkingMode 0 "normal
" 1 "abnormal"  ;
VAL_ 776 DCDC_EnableSts 0 "normal
" 1 "abnormal"  ;
VAL_ 776 DCDC_CoolingReq 0 "不需冷却；
" 1 "请求冷却；"  ;
VAL_ 880 PDU_AirPTC_WorkStus 0 "未工作
" 1 "一档风PTC
" 2 "二档风PTC
" 3 "最大档风PTC（5000W功率）"  ;
VAL_ 372 VCU_Err_AccPedal 0 "No_Error无错误
" 1 "Error错误"  ;
VAL_ 372 VCU_InsuldDetcCtrl 0 "Inactive
" 1 "Active"  ;
VAL_ 372 VCU_GearPosition 0 "Invalid
" 1 "P档
" 2 "R倒挡
" 3 "N空挡
" 4 "D前进挡
" 5 "Reserved保留
" 6 "Error错误
" 7 "Reserved保留
" 8 "Reserved保留
" 9 "Reserved保留
" 10 "Reserved保留
" 11 "Reserved保留
" 12 "Reserved保留
" 13 "Reserved保留
" 14 "Reserved保留
" 15 "Reserved保留"  ;
VAL_ 372 VCU_PrechrgAnodeRelay_Status 0 "Invalid
" 1 "Open打开
" 2 "Connect连接
" 3 "Reserved"  ;
VAL_ 372 VCU_DischrgAnodeRelay_Control 0 "Open打开
" 1 "Connect连接"  ;
VAL_ 372 VCU_DischrgAnodeRelay_Status 0 "Invalid
" 1 "Open打开
" 2 "Connect连接
" 3 "Reserved"  ;
VAL_ 372 VCU_DischrgCathodeRelay_Control 0 "Open打开
" 1 "Connect连接"  ;
VAL_ 372 VCU_DischrgCathodeRelay_status 0 "Invalid
" 1 "Open打开
" 2 "Connect连接
" 3 "Reserved"  ;
VAL_ 372 VCU_PrechrgAnodeRelay_Control 0 "Open打开
" 1 "Connect连接"  ;
VAL_ 372 VCU_PTSystem_Satus 0 "normal无故障
" 1 "slight一般动力系统故障
" 2 "serious严重动力系统故障
" 3 "reserved预留"  ;
VAL_ 372 VCU_VehSysStatus 0 "Invalid
" 1 "KLOFF
" 2 "KLON
" 3 "READY
" 4 "HighVoltage Pending
" 5 "DCChargeMode
" 6 "ACChargeMode
" 7 "Vehicel Fault
" 8 "Reserved" 9 "Reserved" 10 "Reserved" 11 "Reserved" 12 "Reserved" 13 "Reserved" 14 "Reserved" 15 "Reserved" 16 "Reserved" 17 "Reserved" 18 "Reserved" 19 "Reserved" 20 "Reserved" 21 "Reserved" 22 "Reserved" 23 "Reserved" 24 "Reserved" 25 "Reserved" 26 "Reserved" 27 "Reserved" 28 "Reserved" 29 "Reserved" 30 "Reserved" 31 "Reserved"  ;
VAL_ 372 VCU_ChrgRelay_Control 0 "Open打开
" 1 "Connect连接"  ;
VAL_ 372 VCU_GearCtrlSts 0 "Driver Control
" 1 "APA Control
" 2 "ADAS Control
" 3 "Reserved"  ;
VAL_ 372 VCU_Cruise_MainSwitch 0 "Cruise_Main_Switch_Off关闭
" 1 "Cruise_Main_Switch_On打开"  ;
VAL_ 372 VCU_OperationMode 0 "Reserved保留
" 1 "normal正常
" 2 "Economic经济
" 3 "Sport运动"  ;
VAL_ 372 VCU_DrivingMode 0 "2 drive 两驱
" 1 "4 drive 四驱
" 2 "Auto
" 3 "Reservedd"  ;
VAL_ 372 VCU_FMCU_unloadReq 0 "no request
" 1 "request"  ;
VAL_ 372 VCU_RMCU_unloadReq 0 "no request
" 1 "request"  ;
VAL_ 372 VCU_AC_unloadReq 0 "no request
" 1 "request"  ;
VAL_ 372 VCU_TortoiseIndicator 0 "OFF关闭
" 1 "ON打开"  ;
VAL_ 372 VCU_ActiveDischargeOrder 0 "disactive关闭
" 1 "active开启"  ;
VAL_ 372 VCU_Cruise_Enable 0 "inactive
" 1 "active"  ;
VAL_ 372 VCU_UnlockSts 0 "Invalid
" 1 "succeed防盗解除成功
" 2 "failed防盗解除失败
" 3 "reserved"  ;
VAL_ 372 VCU_StartAllow 0 "Allowed
" 1 "Not allowed"  ;
VAL_ 568 VCU_AC_Permittion 0 "prohibit
" 1 "allow"  ;
VAL_ 568 FPump_Enable 0 "false
" 1 "true"  ;
VAL_ 568 VCU_VehicleMaintenanceMode 0 "Inactive
" 1 "active
" 2 "Reserved
" 3 "Reserved"  ;
VAL_ 568 VCU_CoolingFanSt 0 "Invalid
" 1 "first_gear
" 2 "second_gear
" 3 "Reserved"  ;
VAL_ 568 VCU_StartInf 0 "无提示
" 1 "启动时请勿松开制动踏板
" 2 "启动时请勿睬油门
" 3 "禁止在充电时启动车辆
" 4 "请在P挡或N挡启动车辆
" 5 "请确保深踩刹车、松开油门、断开充电枪、档位P/N
" 6 "Reserved
" 7 "Reserved"  ;
VAL_ 568 VCU_ChaGearInf 0 "无提示
" 1 "请踩住制动踏板换挡
" 2 "车辆行驶中，禁止换挡
" 3 "换挡失败，请重新尝试
" 4 "Reserved
" 5 "Reserved
" 6 "Reserved
" 7 "Reserved"  ;
VAL_ 568 VCU_ChgCpleInDrvInfor 0 "Inactive
" 1 "Active"  ;
VAL_ 568 VCU_ShutDwnRmdr 0 "无提示
" 1 "请深踩制动
" 2 "请松开油门
" 3 "请拔充电枪
" 4 "请将档位换至P/N
" 5 "请确保深踩刹车、松开油门、断开充电枪、档位P/N
" 6 "Reserved
" 7 "Reserved"  ;
VAL_ 568 VCU_PowerOffWarmingInfo 0 "无提示
" 1 "请停车熄火"  ;
VAL_ 568 VCU_APTC_PowerGear 0 "无请求
" 1 "一档风PTC
" 2 "二档风PTC
" 3 "最大档风PTC（5000W功率）"  ;
VAL_ 570 VCU_Fastchrg_Permittion 0 "Invalid
" 1 "prohibit
" 2 "allow
" 3 "Reserved"  ;
VAL_ 570 VCU_Slowchrg_Permittion 0 "Invalid
" 1 "prohibit
" 2 "allow
" 3 "Reserved"  ;
VAL_ 570 VCU_AC_ChrgStatus 0 "DCChrgDisable
" 1 "ChrgHandSharking
" 2 "ChrgFault
" 3 "DC_Charing
" 4 "DC_Heating
" 5 "ChargeToHeatHangup
" 6 "HeatToChargeHangup
" 7 "ChargeShutDown"  ;
VAL_ 570 VCU_OBC_Permittion 0 "prohibit
" 1 "allow"  ;
VAL_ 570 VCU_EnergyRecoverySt 0 "Invalid
" 1 "Lev0
" 2 "Lev1
" 3 "Lev2
" 4 "Lev3
" 5 "reserved
" 6 "reserved
" 7 "reserved"  ;
VAL_ 570 VCU_PwrFlowIndcr 0 "No Power Flow
" 1 "Charging Power Flow
" 2 "Charge Finished Power Flow
" 3 "Driving Power Flow
" 4 "Regener Power Flow
" 5 "reserved
" 6 "reserved
" 7 "reserved"  ;
VAL_ 570 VCU_DC_ChrgStatus 0 "DCChrgDisable
" 1 "ChrgHandSharking
" 2 "ChrgFault
" 3 "DC_Charing
" 4 "DC_Heating
" 5 "ChargeToHeatHangup
" 6 "HeatToChargeHangup
" 7 "ChargeShutDown"  ;
VAL_ 570 VCU_V2V_ChrgStatus 0 "DCChrgDisable
" 1 "ChrgHandSharking
" 2 "ChrgFault
" 3 "DC_Charing
" 4 "DC_Heating
" 5 "ChargeToHeatHangup
" 6 "HeatToChargeHangup
" 7 "ChargeShutDown"  ;
VAL_ 574 VCU_TbUnlockSts 0 "Invalid
" 1 "防盗解除成功
" 2 "防盗解除失败
" 3 "reserved"  ;
VAL_ 574 VCU_RCt_ModeSts 0 "OFF
" 1 "ON"  ;
VAL_ 574 VCU_VehPowerMode 0 "纯电动；
" 1 "混动；
" 2 "燃油；
" 3 "reserved"  ;
VAL_ 574 VCU_Precharge_Satus 0 "Not_precharge
" 1 "Pecharging
" 2 "Precharge_complete
" 3 "Precharge_Failure"  ;
VAL_ 574 VCU_request_subscribe_allow 0 "prohibit
" 1 "allow"  ;
VAL_ 574 VCU_DCSystemDischrgAllowed 0 "Discharge_forbid
" 1 "Discharge_allow
" 2 "Reserved
" 3 "Reserved"  ;
VAL_ 574 VCU_MotorLockAllowed 0 "Allowed
" 1 "Not Allowed"  ;
VAL_ 574 VCU_MotorLockSts 0 "unlocked
" 1 "locking
" 2 "reserved
" 3 "reserved"  ;
VAL_ 112 VCU_DriverLeverIntervention 0 "Not active
" 1 "Active"  ;
VAL_ 112 VCU_BrkSw_Sta 0 "not pressed
" 1 "pressed"  ;
VAL_ 112 VCU_BrkSw_V 0 "Inactive
" 1 "Active"  ;
VAL_ 112 VCU_Acc_Validity 0 "Valid
" 1 "Invalid"  ;
VAL_ 112 VCU_DriverOverride 0 "No override
" 1 "Override"  ;
VAL_ 913 VSP_PermanentStsFeedback 0 "无效
" 1 "永久开（永久性翻转VSP状态开）
" 2 "永久关（永久性翻转VSP状态关）
" 3 "保留"  ;
VAL_ 913 VSP_ShorterStsFeedback 0 "无效
" 1 "临时开（临时性翻转VSP状态开）
" 2 "临时关（临时性翻转VSP状态关）
" 3 "保留"  ;
VAL_ 913 VSP_StopModeStsFeedback 0 "停车模式开
" 1 "停车模式关"  ;
VAL_ 913 VSP_VoiceSourceStateFeedback 0 "无反馈
" 1 "当前声源1
" 2 "当前声源2
" 3 "当前声源3
" 4 "当前声源4
" 5 "当前声源5
" 6 "当前声源6
" 7 "当前声源7"  ;
VAL_ 656 Tbox_UnlockSts 0 "Invalid
" 1 "防盗解除成功
" 2 "防盗解除失败
" 3 "reserved"  ;
VAL_ 656 TBOX_AuthentificationRQ 0 "OFF
" 1 "ON"  ;
VAL_ 656 TBOX_FuncSts 0 " Invalid" 1 " off" 2 " on" 3 " reserved"  ;
VAL_ 656 Tbox_PELockCtl 0 " 蓝牙钥匙解锁/迎宾无效" 1 " 蓝牙钥匙解锁/迎宾有效"  ;
VAL_ 656 TBOX_TimeSts 0 " Invalid" 1 " out" 2 " in" 3 " reserved"  ;
VAL_ 645 TBOX_TimeCheckBit 0 "Valid
" 1 "invalid"  ;
VAL_ 664 Tbox_MMI_FICM_Available 0 "Available
" 1 "Unavailable"  ;
VAL_ 148 EHB_FaultSt 0 " No fault" 1 " Fault state1" 2 " Fault state2" 3 " Fault state3" 4 " Fault state4" 5 " Fault state5" 6 " Fault state6" 7 " Reserved"  ;
VAL_ 328 EPB_Brake_Lights_Request_L 0 " No request" 1 " Request"  ;
VAL_ 328 EPB_SwitchSta_L 0 " Neutral" 1 " Release" 2 " Apply" 3 " invalid"  ;
VAL_ 328 EPB_WarnLampSta_L 0 " OFF" 1 " ON" 2 " Blinking" 3 " Reserved"  ;
VAL_ 328 EPB_ParkLampSta_L 0 " OFF" 1 " ON" 2 " Blinking" 3 " Reserved"  ;
VAL_ 328 EPB_ActuatorSt_L 0 " Releasing" 1 " Brake On" 2 " Brake Off" 3 " Applying" 4 " Maintenance brake off" 5 " Broken" 6 " Hold" 7 " ActuatorAdjust"  ;
VAL_ 328 EPB_DisplayMsgID_L 0 " off" 1 " Fasten seatbelt" 2 " push brake pedal" 3 " Change Gear to no P gear"  ;
VAL_ 336 EPB_Brake_Lights_Request_R 0 " No request" 1 " Request"  ;
VAL_ 336 EPB_SwitchSta_R 0 " Neutral" 1 " Release" 2 " Apply" 3 " invalid"  ;
VAL_ 336 EPB_WarnLampSta_R 0 " OFF" 1 " ON" 2 " Blinking" 3 " Reserved"  ;
VAL_ 336 EPB_ParkLampSta_R 0 " OFF" 1 " ON" 2 " Blinking" 3 " Reserved"  ;
VAL_ 336 EPB_ActuatorSt_R 0 " Releasing" 1 " Brake On" 2 " Brake Off" 3 " Applying" 4 " Maintenance brake off" 5 " Broken" 6 " Hold" 7 " ActuatorAdjust"  ;
VAL_ 336 EPB_DisplayMsgID_R 0 " off" 1 " Fasten seatbelt" 2 " push brake pedal" 3 " Change Gear to no P gear"  ;
VAL_ 336 ESC_VehSpdVd 0 " Not valid" 1 " Valid"  ;
VAL_ 584 AC_AutoMode 0 "Invalid
" 1 "自动模式已开启
" 2 "自动模式未开启
" 3 "reserved"  ;
VAL_ 584 AC_ActualBlowingMode 0 "Invalid
" 1 "吹面
" 2 "吹面吹脚
" 3 "吹脚
" 4 "吹脚吹玻璃
" 5 "吹玻璃
" 6 "Reserved
" 7 "Reserved"  ;
VAL_ 584 AC_ActualCirculationMode 0 "Invalid
" 1 "内循环
" 2 "外循环
" 3 "reserved"  ;
VAL_ 584 AC_DVDDisplayReq 0 "No req
" 1 "Req"  ;
VAL_ 584 AC_ActualAirQuantity 0 "Invalid
" 1 "1档；
" 2 "2档；
" 3 "3档；
" 4 "4档；
" 5 "5档；
" 6 "6档；
" 7 "7档；"  ;
VAL_ 584 AC_FwdDeforstSts 0 "OFF
" 1 "ON"  ;
VAL_ 584 AC_RearDeforstSts 0 "OFF
" 1 "ON"  ;
VAL_ 584 AC_CoolingStaus 0 "Invalid
" 1 "opened
" 2 "closed
" 3 "reserved"  ;
VAL_ 584 AC_MaxCooingStaus 0 "Invalid
" 1 "opened
" 2 "closed
" 3 "reserved"  ;
VAL_ 584 AC_OffStaus 0 "Invalid
" 1 "valid"  ;
VAL_ 584 AC_PM25_Status 0 "Invalid
" 1 "valid"  ;
VAL_ 584 AC_RearViewMirroHeatStatus 0 "Invalid
" 1 "on
" 2 "off
" 3 "reserved"  ;
VAL_ 584 AC_NegativeIconGenStus 0 "Invalid
" 1 "on
" 2 "off
" 3 "reserved"  ;
VAL_ 607 AC_BatteryPumpState 0 "正常停机
" 1 "水泵运行
" 2 "故障停机
" 3 "Reserved
" 4 "Reserved
" 5 "Reserved
" 6 "Reserved
" 7 "Reserved
" 8 "Reserved
" 9 "Reserved
" 10 "Reserved
" 11 "Reserved
" 12 "Reserved
" 13 "Reserved
" 14 "Reserved
" 15 "Reserved"  ;
VAL_ 607 AC_ACMode 0 "Off
" 1 "Cabin cooling
" 2 "Cabin heating
" 3 "Defog
" 4 "Defrost
" 5 "Reserved
" 6 "Reserved
" 7 "Reserved
" 8 "Reserved
" 9 "Reserved
" 10 "Reserved
" 11 "Reserved
" 12 "Reserved
" 13 "Reserved
" 14 "Reserved
" 15 "Reserved"  ;
VAL_ 607 AC_RearDeforstReq 0 "off
" 1 "on"  ;
VAL_ 607 AC_AmbientAirTemperature_Validity 0 "valid；
" 1 "invalid"  ;
VAL_ 607 AC_Fan_SpeedReq 0 "No RQ
" 1 "1档
" 2 "2档
" 3 "reserved"  ;
VAL_ 607 AC_SeatHeatReq_right 0 "off
" 1 "1档
" 2 "2档
" 3 "reserved"  ;
VAL_ 607 AC_SeatHeatReq_left 0 "off
" 1 "1档
" 2 "2档
" 3 "reserved"  ;
VAL_ 607 AC_WorkingResponse_Status 0 "invalid
" 1 "未工作
" 2 "加热
" 3 "制冷
" 4 "水泵自循环
" 5 "故障
" 6 "保留
" 7 "保留"  ;
VAL_ 607 AC_unload_Status 0 "Invalid
" 1 "未卸载
" 2 "卸载中
" 3 "卸载完成"  ;
VAL_ 390 AVM_BSDLeftWaringSeverity 0 "level0
" 1 "level1
" 2 "level2
" 3 "level3
" 127 "invalid"  ;
VAL_ 390 AVM_BSDLeftWaringValid 0 "invalid
" 1 "valid"  ;
VAL_ 390 AVM_BSDRightWaringSeverity 0 "level0
" 1 "level1
" 2 "level2
" 3 "level3
" 127 "invalid"  ;
VAL_ 390 AVM_BSDRightWaringValid 0 "invalid
" 1 "valid"  ;
VAL_ 390 AVM_BSDStatus 0 "BSD not run
" 1 "BSD run"  ;
VAL_ 390 AVM_BSDStatusValid 0 "invalid
" 1 "valid"  ;
VAL_ 392 AVM_MMI_ConnectStatus 0 "none/提示用户AVM_ECU等待连接
" 1 "disconnect/提示用户AVM_ECU断开连接
" 2 "connected
" 15 "invalid/提示用户AVM_ECU连接异常"  ;
VAL_ 392 AVM_MMI_EcuStatus 0 "none/提示用户AVM_ECU上电中
" 1 "power off/提示用户AVM_ECU已下电
" 2 "power on
" 3 "reserved
" 4 "reserved
" 5 "reserved
" 6 "reserved
" 7 "reserved
" 8 "reserved
" 9 "reserved
" 10 "reserved
" 11 "reserved
" 12 "reserved
" 13 "reserved
" 14 "reserved
" 15 "invalid"  ;
VAL_ 392 AVM_MMI_VideoOutputStatus 0 "none/显示MMI画面
" 1 "off/显示MMI画面
" 2 "on/显示AVM画面
" 3 "invalid"  ;
VAL_ 392 AVM_MMI_AVM3DViewModeStatus 0 "none
" 1 "2d
" 2 "3d
" 3 "speed3D
" 4 "Ctv_Front
" 5 "Ctv_Rear
" 6 "Rim_Front
" 7 "Rim_Rear
" 8 "reserved
" 9 "reserved
" 10 "reserved
" 11 "reserved
" 12 "reserved
" 13 "reserved
" 14 "reserved
" 15 "invalid"  ;
VAL_ 392 AVM_MMI_AVM3DViewSwitch 0 "none
" 1 "2d_front
" 2 "2d_right
" 3 "2d_left
" 4 "2d_rear
" 5 "reserved
" 6 "reserved
" 7 "reserved
" 8 "reserved
" 9 "reserved
" 10 "reserved
" 11 "reserved
" 12 "reserved
" 13 "reserved
" 14 "reserved
" 15 "reserved
" 16 "reserved
" 17 "3d_front
" 18 "3d_right
" 19 "3d_left
" 20 "3d_rear
" 21 "3d_right_front
" 22 "3d_left_front
" 23 "3d_left_rear
" 24 "3d_right_rear
" 25 "reserved
" 26 "reserved
" 27 "reserved
" 28 "reserved
" 29 "reserved
" 30 "reserved
" 31 "reserved
" 32 "reserved
" 33 "reserved
" 34 "reserved
" 35 "reserved
" 36 "reserved
" 37 "reserved
" 38 "reserved
" 39 "reserved
" 40 "reserved
" 41 "reserved
" 42 "reserved
" 43 "reserved
" 44 "reserved
" 45 "reserved
" 46 "reserved
" 47 "reserved
" 48 "reserved
" 49 "reserved
" 50 "reserved
" 51 "reserved
" 52 "reserved
" 53 "reserved
" 54 "reserved
" 55 "reserved
" 56 "reserved
" 57 "reserved
" 58 "reserved
" 59 "reserved
" 60 "reserved
" 61 "reserved
" 62 "reserved
" 63 "reserved
" 64 "reserved
" 65 "reserved
" 66 "reserved
" 67 "reserved
" 68 "reserved
" 69 "reserved
" 70 "reserved
" 71 "reserved
" 72 "reserved
" 73 "reserved
" 74 "reserved
" 75 "reserved
" 76 "reserved
" 77 "reserved
" 78 "reserved
" 79 "reserved
" 80 "reserved
" 81 "reserved
" 82 "reserved
" 83 "reserved
" 84 "reserved
" 85 "reserved
" 86 "reserved
" 87 "reserved
" 88 "reserved
" 89 "reserved
" 90 "reserved
" 91 "reserved
" 92 "reserved
" 93 "reserved
" 94 "reserved
" 95 "reserved
" 96 "reserved
" 97 "reserved
" 98 "reserved
" 99 "reserved
" 100 "reserved
" 101 "reserved
" 102 "reserved
" 103 "reserved
" 104 "reserved
" 105 "reserved
" 106 "reserved
" 107 "reserved
" 108 "reserved
" 109 "reserved
" 110 "reserved
" 111 "reserved
" 112 "reserved
" 113 "reserved
" 114 "reserved
" 115 "reserved
" 116 "reserved
" 117 "reserved
" 118 "reserved
" 119 "reserved
" 120 "reserved
" 121 "reserved
" 122 "reserved
" 123 "reserved
" 124 "reserved
" 125 "reserved
" 126 "reserved
" 127 "reserved
" 128 "reserved
" 129 "reserved
" 130 "reserved
" 131 "reserved
" 132 "reserved
" 133 "reserved
" 134 "reserved
" 135 "reserved
" 136 "reserved
" 137 "reserved
" 138 "reserved
" 139 "reserved
" 140 "reserved
" 141 "reserved
" 142 "reserved
" 143 "reserved
" 144 "reserved
" 145 "reserved
" 146 "reserved
" 147 "reserved
" 148 "reserved
" 149 "reserved
" 150 "reserved
" 151 "reserved
" 152 "reserved
" 153 "reserved
" 154 "reserved
" 155 "reserved
" 156 "reserved
" 157 "reserved
" 158 "reserved
" 159 "reserved
" 160 "reserved
" 161 "reserved
" 162 "reserved
" 163 "reserved
" 164 "reserved
" 165 "reserved
" 166 "reserved
" 167 "reserved
" 168 "reserved
" 169 "reserved
" 170 "reserved
" 171 "reserved
" 172 "reserved
" 173 "reserved
" 174 "reserved
" 175 "reserved
" 176 "reserved
" 177 "reserved
" 178 "reserved
" 179 "reserved
" 180 "reserved
" 181 "reserved
" 182 "reserved
" 183 "reserved
" 184 "reserved
" 185 "reserved
" 186 "reserved
" 187 "reserved
" 188 "reserved
" 189 "reserved
" 190 "reserved
" 191 "reserved
" 192 "reserved
" 193 "reserved
" 194 "reserved
" 195 "reserved
" 196 "reserved
" 197 "reserved
" 198 "reserved
" 199 "reserved
" 200 "reserved
" 201 "reserved
" 202 "reserved
" 203 "reserved
" 204 "reserved
" 205 "reserved
" 206 "reserved
" 207 "reserved
" 208 "reserved
" 209 "reserved
" 210 "reserved
" 211 "reserved
" 212 "reserved
" 213 "reserved
" 214 "reserved
" 215 "reserved
" 216 "reserved
" 217 "reserved
" 218 "reserved
" 219 "reserved
" 220 "reserved
" 221 "reserved
" 222 "reserved
" 223 "reserved
" 224 "reserved
" 225 "reserved
" 226 "reserved
" 227 "reserved
" 228 "reserved
" 229 "reserved
" 230 "reserved
" 231 "reserved
" 232 "reserved
" 233 "reserved
" 234 "reserved
" 235 "reserved
" 236 "reserved
" 237 "reserved
" 238 "reserved
" 239 "reserved
" 240 "reserved
" 241 "reserved
" 242 "reserved
" 243 "reserved
" 244 "reserved
" 245 "reserved
" 246 "reserved
" 247 "reserved
" 248 "reserved
" 249 "reserved
" 250 "reserved
" 251 "reserved
" 252 "reserved
" 253 "reserved
" 254 "reserved
" 255 "reserved"  ;
VAL_ 338 BCM_RFDoorSwitchSt 0 "Close
" 1 "Open"  ;
VAL_ 338 BCM_LFDoorSwitchSt 0 "Close
" 1 "Open"  ;
VAL_ 338 BCM_PositionLampSt 0 "Close
" 1 "Open"  ;
VAL_ 338 BCM_FrontFogligthSt 0 "Close
" 1 "Open"  ;
VAL_ 338 BCM_BackFogligthSt 0 "Close
" 1 "Open"  ;
VAL_ 338 BCM_HighBeamStatus 0 "Close
" 1 "Open"  ;
VAL_ 338 BCM_LowBeamStatus 0 "Close
" 1 "Open"  ;
VAL_ 338 BCM_TrunkSt 0 "Close
" 1 "Open"  ;
VAL_ 338 BCM_TurnLeverLoc 0 "Invalid(左右转向未开启)
" 1 "左转向
" 2 "右转向
" 3 "Reserved"  ;
VAL_ 338 BCM_RightligthFaultSt 0 "No_Failure
" 1 "Failure"  ;
VAL_ 338 BCM_RightligthSt 0 "Close
" 1 "Open"  ;
VAL_ 338 BCM_LetfligthFaultSt 0 "No_Failure
" 1 "Failure"  ;
VAL_ 338 BCM_LetfligthSt 0 "Close
" 1 "Open"  ;
VAL_ 338 BCM_LRDoorSwitchSt 0 "Close
" 1 "Open"  ;
VAL_ 338 BCM_RRDoorSwitchSt 0 "Close
" 1 "Open"  ;
VAL_ 338 BCM_CentralLockSt 0 "Lock
" 1 "Unlock"  ;
VAL_ 338 BCM_Reverse_Light 0 "Off
" 1 "On"  ;
VAL_ 338 Bcm_OutSwitchPressCmd 0 "Close
" 1 "Open"  ;
VAL_ 338 BCM_HazardwarnLampSt 0 "Close
" 1 "Open"  ;
VAL_ 338 BCM_PassSeatbeltBucklestatus 0 "Safety belt tied
" 1 "Safety belt not tied"  ;
VAL_ 338 BCM_DrvSeatbeltBucklestatus 0 "Safety belt tied
" 1 "Safety belt not tied"  ;
VAL_ 338 BCM_FrontCoverSt 0 "Close
" 1 "Open"  ;
VAL_ 338 BCM_WiperMaintainFuncCtrStus 0 "Invalid
" 1 "close
" 2 "open
" 3 "Reserved"  ;
VAL_ 338 BCM_HornStus 0 " Close" 1 " Open"  ;
VAL_ 338 BCM_PositionLampOpenWarm 0 " 无报警" 1 " 报警"  ;
VAL_ 338 BCM_Auto_LightSwitch 0 "Off不处于AUTO挡
" 1 "On处于AUTO挡"  ;
VAL_ 338 BCM_Brake_Light 0 "Off
" 1 "On"  ;
VAL_ 338 BCM_RearViewMirrorAutoFoldFucFeedback 0 "invalid
" 1 "close
" 2 "open
" 3 "Reserved"  ;
VAL_ 338 BCM_Rain_Sensor 0 "No rain(OFF)
" 1 "Light rain(LOW)
" 2 "Heavy rain(HIGH)"  ;
VAL_ 338 BCM_DrvSeatbeltBucklevalidity 0 "not valid
" 1 "valid"  ;
VAL_ 338 BCM_PassSeatbeltBucklevalidity 0 "not valid
" 1 "valid"  ;
VAL_ 338 BCM_PowerMode 0 "Invalid无效
" 1 "OffPwr_Sts
" 2 "Localkeyon
" 3 "Remotekeyon                                                          0x4～0x7"  ;
VAL_ 338 BCM_RearViewMirror 0 "Invalid
" 1 "折叠
" 2 "展开
" 3 "Reserved"  ;
VAL_ 338 BCM_ChargeCoverLockStatus 0 "unlock
" 1 "lock"  ;
VAL_ 338 BCM_RearDeforstSts 0 "OFF
" 1 "ON"  ;
VAL_ 338 BCM_BkSeat_1_beltBucklevalidity 0 "invalid
" 1 "valid"  ;
VAL_ 338 BCM_BkSeat_1_beltBucklestatus 0 "Safety belt tied
" 1 "Safety belt not tied"  ;
VAL_ 338 BCM_BkSeat_2_beltBucklevalidity 0 "invalid
" 1 "valid"  ;
VAL_ 338 BCM_BkSeat_2_beltBucklestatus 0 "Safety belt tied
" 1 "Safety belt not tied"  ;
VAL_ 338 BCM_BkSeat_3_beltBucklevalidity 0 "invalid
" 1 "valid"  ;
VAL_ 338 BCM_BkSeat_3_beltBucklestatus 0 "Safety belt tied
" 1 "Safety belt not tied"  ;
VAL_ 338 BCM_RainAutoClsWindowFuncStus 0 "invalid
" 1 "Open
" 2 "Close
" 3 "Reserved"  ;
VAL_ 338 BCM_LockVehicleWarmingTipStus 0 "invalid
" 1 "flash
" 2 "flash with horn
" 3 "Reserved"  ;
VAL_ 338 BCM_CourtesyLampStus 0 "Close
" 1 "Open"  ;
VAL_ 338 BCM_VehicleCourtesyLampFuncStus 0 "invalid
" 1 "close
" 2 "open
" 3 "Reserved"  ;
VAL_ 338 BCM_AccLampSetStus 0 "invalid
" 1 "close
" 2 "开启(延迟30s关闭)
" 3 "开启(延迟60s关闭)"  ;
VAL_ 588 PEPS_KeyInCarWarning 0 "Inactive
" 1 "Active"  ;
VAL_ 588 ReminderPutInP_Nposition_OFF 0 "Inactive
" 1 "Active"  ;
VAL_ 588 ReminderPutInP_Nposition_Lock 0 "Inactive
" 1 "Active"  ;
VAL_ 588 PEPS_KeyNotInWarning 0 "Inactive
" 1 "Active"  ;
VAL_ 588 BCM_FrontWiperSt 0 "OFF
" 1 "AUTO or INT
" 2 "Continuous slow
" 3 "Continuous fast"  ;
VAL_ 588 PEPS_PutKeyInIMMOSocket 0 "Inactive
" 1 "Active"  ;
VAL_ 588 PEPS_PowerRelayFault 0 "Inactive
" 1 "Active"  ;
VAL_ 588 PEPS_RemoteLowVoltage 0 "Inactive
" 1 "Active"  ;
VAL_ 588 WashStatus 0 "off
" 1 "on"  ;
VAL_ 588 WipeReset 0 "回到位
" 1 "未回到位"  ;
VAL_ 588 PEPS_ESCLFault 0 "no fault
" 1 "fault"  ;
VAL_ 588 PEPS_ESCLUnlockFailed 0 "Normal
" 1 "Unlock failed"  ;
VAL_ 588 BCM_SenyClass 0 "Invalid
" 1 "等级1
" 2 "等级2
" 3 "等级3
" 4 "等级4
" 5 "Reserved
" 6 "Reserved
" 7 "Reserved"  ;
VAL_ 588 BCM_OpenDoorWarning 0 "Normal
" 1 "Alarm（车门已开，欢迎上车）"  ;
VAL_ 589 PEPS_LastLockType 0 "Non
" 1 "PE Lock
(或Poling上锁)" 2 "Remote Key Lock
" 3 "Auto Lock
（二次上锁）" 4 "Speed Lock
（随速上锁）" 5 "Tbox Lock
（Tbox上锁）" 6 "MMI Lock
（大屏上锁）" 7 "CentralCtrl Lock（中控上锁）"  ;
VAL_ 589 PEPS_RkeLockCmd 0 " no  operation" 1 " RKE 解锁" 2 " RKE 闭锁" 3 " RKE 遥控升窗" 4 " Reserved" 5 " RKE 寻车" 6 " RKE 遥控降窗" 7 " Reserved"  ;
VAL_ 589 BCM_LFDoorLockStatus 0 "default
" 1 "unlock；
" 2 "locked
" 7 "Invalid"  ;
VAL_ 589 BCM_TrunkDoorLockSts 0 "default
" 1 "unlock；
" 2 "locked
" 7 "Invalid"  ;
VAL_ 589 PEPS_ESCL_SteeringLockStatus 0 "transforming
" 1 "lock
" 2 "unlock
" 3 "Reserved"  ;
VAL_ 589 BCM_RFDoorLockStatus 0 "default
" 1 "unlock；
" 2 "locked
" 7 "Invalid"  ;
VAL_ 589 BCM_LRDoorLockStatus 0 "default
" 1 "unlock；
" 2 "locked
" 7 "Invalid"  ;
VAL_ 589 PEPS_DrvDoorRequestSwitchSt 0 "Inactive
" 1 "Active"  ;
VAL_ 589 PEPS_StartStopButtonSt 0 "Inactive
" 1 "Active"  ;
VAL_ 589 PEPS_TrunkRequestSwitchSt 0 "Inactive
" 1 "Active"  ;
VAL_ 589 PEPS_VDrvDoorRequestSwitchSt 0 "Inactive
" 1 "Active"  ;
VAL_ 589 BCM_RRDoorLockStatus 0 "default
" 1 "unlock；
" 2 "locked
" 7 "Invalid"  ;
VAL_ 589 BCM_RLS_RQ_WiperSPD 0 "No wiping
" 1 "Low Speed
" 2 "High Speed
" 3 "Not used"  ;
VAL_ 589 BCM_RLS_Fault 0 "No fault
" 1 "fault
" 2 "reserved
" 3 "reserved"  ;
VAL_ 610 BCM_RR_TirePrsSt 0 "Normal
" 1 "Over-pressure
" 2 "Under-pressure
" 3 "Reserved"  ;
VAL_ 610 BCM_RL_TirePrsSt 0 "Normal
" 1 "Over-pressure
" 2 "Under-pressure
" 3 "Reserved"  ;
VAL_ 610 BCM_FR_TirePrsSt 0 "Normal
" 1 "Over-pressure
" 2 "Under-pressure
" 3 "Reserved"  ;
VAL_ 610 BCM_FL_TirePrsSt 0 "Normal
" 1 "Over-pressure
" 2 "Under-pressure
" 3 "Reserved"  ;
VAL_ 612 BCM_RR_TireTptSt 0 "Normal
" 1 "Over temp"  ;
VAL_ 612 BCM_RL_TireTptSt 0 "Normal
" 1 "Over temp"  ;
VAL_ 612 BCM_FR_TireTptSt 0 "Normal
" 1 "Over temp"  ;
VAL_ 612 BCM_FL_TireTptSt 0 "Normal
" 1 "Over temp"  ;
VAL_ 612 BCM_TPMS_MonStatus 0 "Normal
" 1 "Abnormal"  ;
VAL_ 612 BCM_TPMS_Fault 0 "Normal
" 1 "fault"  ;
VAL_ 613 BCM_RR_TireLose 0 "Normal
" 1 "RRLose"  ;
VAL_ 613 BCM_RL_TireLose 0 "Normal
" 1 "RLLose"  ;
VAL_ 613 BCM_FR_TireLose 0 "Normal
" 1 "FRLose"  ;
VAL_ 613 BCM_FL_TireLose 0 "Normal
" 1 "FLLose"  ;
VAL_ 613 BCM_RR_TireLowVol 0 "Normal
" 1 "LowVoltage"  ;
VAL_ 613 BCM_RL_TireLowVol 0 "Normal
" 1 "LowVoltage"  ;
VAL_ 613 BCM_FR_TireLowVol 0 "Normal
" 1 "LowVoltage"  ;
VAL_ 613 BCM_FL_TireLowVol 0 "Normal
" 1 "LowVoltage"  ;
VAL_ 613 BCM_RR_TestSt 0 "System in normal status
" 1 "System inTest status"  ;
VAL_ 613 BCM_RL_TestSt 0 "System in normal status
" 1 "System inTest status"  ;
VAL_ 613 BCM_FR_TestSt 0 "System in normal status
" 1 "System inTest status"  ;
VAL_ 613 BCM_FL_TestSt 0 "System in normal status
" 1 "System inTest status"  ;
VAL_ 613 BCM_BatVol_ErrFlag 0 "Normal
" 1 "Abnormal"  ;
VAL_ 613 BCM_TPMS_TestSt 0 "System in normal status
" 1 "System in learn status
" 2 "Reserved
" 3 "Reserved"  ;
VAL_ 613 BCM_RR_Quikleakage 0 "Normal
" 1 "Quik leakage"  ;
VAL_ 613 BCM_RL_Quikleakage 0 "Normal
" 1 "Quik leakage"  ;
VAL_ 613 BCM_FR_Quikleakage 0 "Normal
" 1 "Quik leakage"  ;
VAL_ 613 BCM_FL_Quikleakage 0 "Normal
" 1 "Quik leakage"  ;
VAL_ 665 DSM_D_SlideDirection 0 "无调节
" 1 "调节中
" 2 "调节完
" 3 "异常"  ;
VAL_ 665 DSM_D_FrontLiftDirection 0 "无调节
" 1 "调节中
" 2 "调节完
" 3 "异常"  ;
VAL_ 665 DSM_D_ReclinerDirection 0 "无调节
" 1 "调节中
" 2 "调节完
" 3 "异常"  ;
VAL_ 665 DSM_D_AllLiftDirection 0 "无调节
" 1 "调节中
" 2 "调节完
" 3 "异常"  ;
VAL_ 665 DSM_DrvSeatHandyEntryExitSetStus 0 "invalid
" 1 "Open
" 2 "Close
" 3 "Reserved"  ;
VAL_ 667 DSM_P_SlideDirection 0 "无调节
" 1 "调节中
" 2 "调节完
" 3 "异常"  ;
VAL_ 667 DSM_P_FrontLiftDirection 0 "无调节
" 1 "调节中
" 2 "调节完
" 3 "异常"  ;
VAL_ 667 DSM_P_ReclinerDirection 0 "无调节
" 1 "调节中
" 2 "调节完
" 3 "异常"  ;
VAL_ 667 DSM_P_AllLiftDirection 0 "无调节
" 1 "调节中
" 2 "调节完
" 3 "异常"  ;
VAL_ 659 FSCM_DrvSeatHeat_Sts 1 "OFF
" 2 "Heating Level 1
" 3 "Heating Level 2
" 4 "Heating Level 3
" 5 "reserved
" 6 "reserved
" 7 "reserved"  ;
VAL_ 659 FSCM_DrvSeatVentilation_Sts 1 "OFF
" 2 "Venting Level 1
" 3 "Venting Level 2
" 4 "Venting Level 3
" 5 "reserved
" 6 "reserved
" 7 "reserved"  ;
VAL_ 659 FSCM_PassSeatHeat_Sts 1 "OFF
" 2 "Heating Level 1
" 3 "Heating Level 2
" 4 "Heating Level 3
" 5 "reserved
" 6 "reserved
" 7 "reserved"  ;
VAL_ 659 FSCM_PassSeatVentilation_Sts 1 "OFF
" 2 "Venting Level 1
" 3 "Venting Level 2
" 4 "Venting Level 3
" 5 "reserved
" 6 "reserved
" 7 "reserved"  ;
VAL_ 853 PSR_FaultStatus 0 "Normal
" 1 "Fault"  ;
VAL_ 853 PSR_PlatfondPellucidityStus 127 " Invalid" 0 "0%~100%" 1 "0%~100%" 2 "0%~100%" 3 "0%~100%" 4 "0%~100%" 5 "0%~100%" 6 "0%~100%" 7 "0%~100%" 8 "0%~100%" 9 "0%~100%" 10 "0%~100%" 11 "0%~100%" 12 "0%~100%" 13 "0%~100%" 14 "0%~100%" 15 "0%~100%" 16 "0%~100%" 17 "0%~100%" 18 "0%~100%" 19 "0%~100%" 20 "0%~100%" 21 "0%~100%" 22 "0%~100%" 23 "0%~100%" 24 "0%~100%" 25 "0%~100%" 26 "0%~100%" 27 "0%~100%" 28 "0%~100%" 29 "0%~100%" 30 "0%~100%" 31 "0%~100%" 32 "0%~100%" 33 "0%~100%" 34 "0%~100%" 35 "0%~100%" 36 "0%~100%" 37 "0%~100%" 38 "0%~100%" 39 "0%~100%" 40 "0%~100%" 41 "0%~100%" 42 "0%~100%" 43 "0%~100%" 44 "0%~100%" 45 "0%~100%" 46 "0%~100%" 47 "0%~100%" 48 "0%~100%" 49 "0%~100%" 50 "0%~100%" 51 "0%~100%" 52 "0%~100%" 53 "0%~100%" 54 "0%~100%" 55 "0%~100%" 56 "0%~100%" 57 "0%~100%" 58 "0%~100%" 59 "0%~100%" 60 "0%~100%" 61 "0%~100%" 62 "0%~100%" 63 "0%~100%" 64 "0%~100%" 65 "0%~100%" 66 "0%~100%" 67 "0%~100%" 68 "0%~100%" 69 "0%~100%" 70 "0%~100%" 71 "0%~100%" 72 "0%~100%" 73 "0%~100%" 74 "0%~100%" 75 "0%~100%" 76 "0%~100%" 77 "0%~100%" 78 "0%~100%" 79 "0%~100%" 80 "0%~100%" 81 "0%~100%" 82 "0%~100%" 83 "0%~100%" 84 "0%~100%" 85 "0%~100%" 86 "0%~100%" 87 "0%~100%" 88 "0%~100%" 89 "0%~100%" 90 "0%~100%" 91 "0%~100%" 92 "0%~100%" 93 "0%~100%" 94 "0%~100%" 95 "0%~100%" 96 "0%~100%" 97 "0%~100%" 98 "0%~100%" 99 "0%~100%" 100 "0%~100%"  ;
VAL_ 856 CWC_Status_Charge 0 "未充电
" 1 "充电中
" 2 "充满
" 3 "充电故障"  ;
VAL_ 856 CWC_Info_matter 0 "Inactive
" 1 "Active"  ;
VAL_ 856 CWC_Info_phoneforgotten 0 "Inactive
" 1 "Active"  ;
VAL_ 856 CWC_Over_Temp 0 "正常；
" 1 "异常；"  ;
VAL_ 856 CWC_Over_Current 0 "正常；
" 1 "异常；"  ;
VAL_ 856 CWC_Over_Voltage 0 "正常；
" 1 "异常；"  ;
